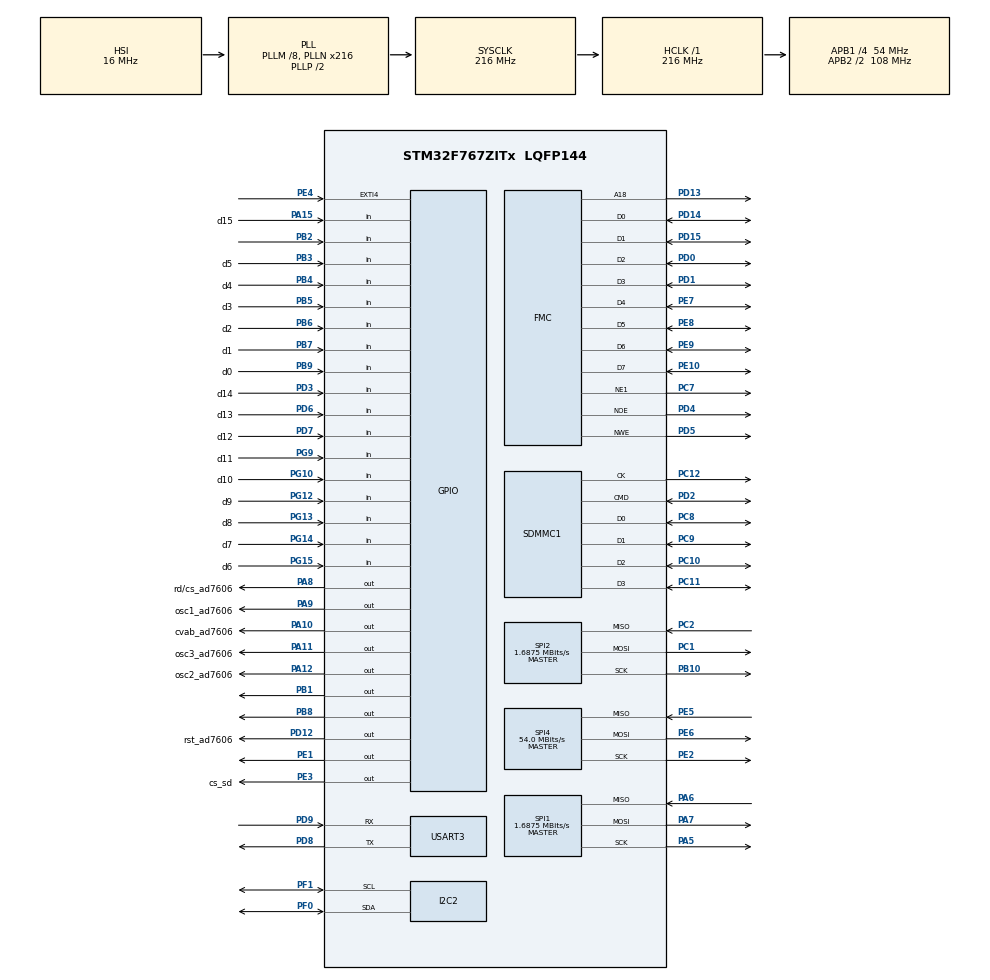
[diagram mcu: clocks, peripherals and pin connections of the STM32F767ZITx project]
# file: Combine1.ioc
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SH.FMC_D7_DA7.0=FMC_D7,8b-d1
PD12.GPIO_Label=rst_ad7606
SPI4.VirtualType=VM_MASTER
SPI1.VirtualType=VM_MASTER
SPI2.VirtualType=VM_MASTER
PB10.Mode=Full_Duplex_Master
PC12.Signal=SDMMC1_CK
PB6.GPIO_Label=d2
SH.FMC_D5_DA5.0=FMC_D5,8b-d1
PD6.GPIO_Label=d13
PG13.Signal=GPIO_Input
SH.FMC_NWE.0=FMC_NWE,Lcd1
RCC.SYSCLKSource=RCC_SYSCLKSOURCE_PLLCLK
USART3.VirtualMode-Asynchronous=VM_ASYNC
PG15.GPIO_Label=d6
SPI1.Direction=SPI_DIRECTION_2LINES
PE2.Mode=Full_Duplex_Master
RCC.APB2TimFreq_Value=216000000
PD4.Signal=FMC_NOE
PB6.Signal=GPIO_Input
PC7.Signal=FMC_NE1
SPI1.CalculateBaudRate=1.6875 MBits/s
PD0.Signal=FMC_D2_DA2
PD8.Signal=USART3_TX
PE5.Signal=SPI4_MISO
PE1.Signal=GPIO_Output
SH.FMC_A18.0=FMC_A18,A18_1
PB2.Signal=GPIO_Input
FMC.DataSetupTime1=255
PE9.Signal=FMC_D6_DA6
SPI1.DataSize=SPI_DATASIZE_8BIT
PC9.Mode=SD_4_bits_Wide_bus
SPI2.CalculateBaudRate=1.6875 MBits/s
PE2.Signal=SPI4_SCK
PA8.Signal=GPIO_Output
SH.FMC_D1_DA1.0=FMC_D1,8b-d1
PE10.Signal=FMC_D7_DA7
Mcu.Package=LQFP144
PB9.Signal=GPIO_Input
PB1.Signal=GPIO_Output
SPI2.Mode=SPI_MODE_MASTER
PD12.Signal=GPIO_Output
PA10.Signal=GPIO_Output
PC11.Mode=SD_4_bits_Wide_bus
RCC.APB2CLKDivider=RCC_HCLK_DIV2
RCC.APB1TimFreq_Value=108000000
PD15.Signal=FMC_D1_DA1
SH.FMC_D3_DA3.0=FMC_D3,8b-d1
PA5.Mode=Full_Duplex_Master
PG12.Signal=GPIO_Input
NVIC.EXTI4_IRQn=true\:0\:0\:false\:false\:true\:true\:true
PG9.Signal=GPIO_Input
FMC.WriteFifo1=FMC_WRITE_FIFO_ENABLE
PA9.GPIO_Label=osc1_ad7606
PD3.Signal=GPIO_Input
PC2.Signal=SPI2_MISO
PD7.Signal=GPIO_Input
PD1.Signal=FMC_D3_DA3
PA11.GPIO_Label=osc3_ad7606
RCC.APB1CLKDivider=RCC_HCLK_DIV4
SH.FMC_NOE.0=FMC_NOE,Lcd1
PG13.GPIO_Label=d8
PG10.Signal=GPIO_Input
PF1.Mode=I2C
PA8.GPIO_Label=rd/cs_ad7606
PA9.Signal=GPIO_Output
PD8.Mode=Asynchronous
PB10.Signal=SPI2_SCK
PA5.Signal=SPI1_SCK
PC12.Mode=SD_4_bits_Wide_bus
PE6.Mode=Full_Duplex_Master
PB4.GPIO_Label=d4
PE8.Signal=FMC_D5_DA5
SPI1.Mode=SPI_MODE_MASTER
PG14.GPIO_Label=d7
SPI1.NSSPMode=SPI_NSS_PULSE_DISABLE
PE4.GPIO_PuPd=GPIO_PULLUP
PC8.Mode=SD_4_bits_Wide_bus
PB5.Signal=GPIO_Input
PA11.Signal=GPIO_Output
ProjectManager.HeapSize=0x200
NVIC.PriorityGroup=NVIC_PRIORITYGROUP_4
PE3.Signal=GPIO_Output
SPI2.DataSize=SPI_DATASIZE_8BIT
PD2.Signal=SDMMC1_CMD
PC1.Signal=SPI2_MOSI
PG10.GPIO_Label=d10
PC1.Mode=Full_Duplex_Master
Mcu.Family=STM32F7
PA6.Mode=Full_Duplex_Master
RCC.CortexFreq_Value=216000000
PC10.Signal=SDMMC1_D2
SPI4.Direction=SPI_DIRECTION_2LINES
I2C2.Timing=0x20404768
SH.FMC_D6_DA6.0=FMC_D6,8b-d1
PD9.Mode=Asynchronous
PG15.Signal=GPIO_Input
ProjectManager.StackSize=0x400
PD13.Signal=FMC_A18
PA15.GPIO_Label=d15
PA12.Signal=GPIO_Output
SPI1.CLKPolarity=SPI_POLARITY_HIGH
SPI4.Mode=SPI_MODE_MASTER
RCC.HCLKFreq_Value=216000000
TIM3.Period=65535
RCC.AHBFreq_Value=216000000
SPI2.BaudRatePrescaler=SPI_BAUDRATEPRESCALER_32
RCC.HSE_VALUE=25000000
SH.FMC_D2_DA2.0=FMC_D2,8b-d1
TIM3.Prescaler=65
PA10.GPIO_Label=cvab_ad7606
PB7.Signal=GPIO_Input
PE4.Signal=GPXTI4
PD7.GPIO_Label=d12
PB7.GPIO_Label=d1
PA6.Signal=SPI1_MISO
SH.FMC_D0_DA0.0=FMC_D0,8b-d1
PA15.Signal=GPIO_Input
SH.FMC_D4_DA4.0=FMC_D4,8b-d1
PB5.GPIO_Label=d3
SPI2.Direction=SPI_DIRECTION_2LINES
PF0.Signal=I2C2_SDA
PD3.GPIO_Label=d14
PE7.Signal=FMC_D4_DA4
PD6.Signal=GPIO_Input
SPI1.BaudRatePrescaler=SPI_BAUDRATEPRESCALER_64
VP_TIM3_VS_ClockSourceINT.Mode=Internal
PB4.Signal=GPIO_Input
PB3.GPIO_Label=d5
PA7.Mode=Full_Duplex_Master
PB9.GPIO_Label=d0
SPI4.DataSize=SPI_DATASIZE_8BIT
PC11.Signal=SDMMC1_D3
PC8.Signal=SDMMC1_D0
PC10.Mode=SD_4_bits_Wide_bus
PE4.GPIO_ModeDefaultEXTI=GPIO_MODE_IT_RISING
PC2.Mode=Full_Duplex_Master
PD9.Signal=USART3_RX
PD5.Signal=FMC_NWE
PA12.GPIO_Label=osc2_ad7606
ProjectManager.TargetToolchain=STM32CubeIDE
RCC.USBFreq_Value=216000000
RCC.LSE_VALUE=32768
VP_FATFS_VS_Generic.Mode=User_defined
PD2.Mode=SD_4_bits_Wide_bus
PG9.GPIO_Label=d11
PG14.Signal=GPIO_Input
board=custom
RCC.VCOOutputFreq_Value=432000000
RCC.APB2Freq_Value=108000000
PE5.Mode=Full_Duplex_Master
SPI4.CalculateBaudRate=54.0 MBits/s
PF1.Signal=I2C2_SCL
PE6.Signal=SPI4_MOSI
Mcu.Name=STM32F767ZITx
PD14.Signal=FMC_D0_DA0
PB3.Signal=GPIO_Input
RCC.SYSCLKFreq_VALUE=216000000
PF0.Mode=I2C
PG12.GPIO_Label=d9
RCC.HSI_VALUE=16000000
RCC.PLLM=8
RCC.PLLN=216
PB8.Signal=GPIO_Output
PE3.GPIO_Label=cs_sd
PC9.Signal=SDMMC1_D1
PC7.Mode=NorPsramChipSelect1_1
RCC.APB1Freq_Value=54000000
PA7.Signal=SPI1_MOSI

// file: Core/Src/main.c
/* USER CODE BEGIN Header */
/**
  ******************************************************************************
  * @file           : main.c
  * @brief          : Main program body
  ******************************************************************************
  * @attention
  *
  * <h2><center>&copy; Copyright (c) 2021 STMicroelectronics.
  * All rights reserved.</center></h2>
  *
  * This software component is licensed by ST under BSD 3-Clause license,
  * the "License"; You may not use this file except in compliance with the
  * License. You may obtain a copy of the License at:
  *                        opensource.org/licenses/BSD-3-Clause
  *
  ******************************************************************************
  */
/* USER CODE END Header */
#include "main.h"
#include "fatfs.h"

/* USER CODE BEGIN Includes */
#include "MA_ILI9341.h"
#include "FIFO.h"
#include "defines.h"
#include "arm_math.h"
#include "arm_const_structs.h"

//extern float32_t testInput_f32_10khz[TEST_LENGTH_SAMPLES];
//static float32_t testOutput[TEST_LENGTH_SAMPLES/2];

#define NPT 1024 //point FFT
#define Fs 5120 //Sampling frequency 5120Hz Frequency resolution 5Hz
#define PI2 6.28318530717959

// ************ Global variables for FFT Bin Example
uint32_t fftSize = 1024;
uint32_t ifftFlag = 0;
uint32_t doBitReverse = 1;

/* USER CODE END Includes */

/* USER CODE BEGIN PTD */
uint8_t myImage[] =
{
0xff,0xff,0xff,0xff,0xff,0xff,0xff,0xff,0xff,0xff,0xff,0xff,0xff,0xff,0xff,0xff,0xff,0xff,0xff,0xff,0xff,0xff,0xff,0xff,0xff,0xff,0xff,0xff,0xff,0xff,0xff,0xff,0xff,0xff,0xff,0xff,0xff,0xff,0xff,0xff,0xff,0xff,0xff,0xff,0xff,0xff,0xff,0xff,0xff,0xff,0xff,0xff,0xff,0xff,0xff,0xff,0xff,0xff,0xff,0xff,0xff,0xff,0xff,0xff,0xff,0xff,0xff,0xff,0xff,0xff,0xff,0xff,0x9c,0xb1,0x39,0x85,0x39,0xc6,0x39,0xc6,0x39,0xe6,0x4a,0x48,0x42,0x27,0x42,0x27,0x5a,0xe9,0xef,0x9d,0xff,0xff,0xff,0xff,0xff,0xff,0xff,0xff,0xff,0xff,0xff,0xff,0xff,0xff,0xff,0xff,0xff,0xff,0xff,0xff,0xff,0xff,0xff,0xff,0xff,0xff,0xff,0xff,0xff,0xff,0xff,0xff,0xff,0xff,0xff,0xff,0xff,0xff,0xff,0xff,0xff,0xff,0xff,0xff,0xff,0xff,0xff,0xff,0xff,0xff,0xff,0xff,0xff,0xff,0xff,0xff,0xff,0xff,0xff,0xff,0xff,0xff,0xff,0xff,0xff,0xff,0xff,0xff
,0xff,0xff,0xff,0xff,0xff,0xff,0xff,0xff,0xff,0xff,0xff,0xff,0xff,0xff,0xff,0xff,0xff,0xff,0xff,0xff,0xff,0xff,0xff,0xff,0xff,0xff,0xff,0xff,0xff,0xff,0xff,0xff,0xff,0xff,0xff,0xff,0xff,0xff,0xff,0xff,0xff,0xff,0xff,0xff,0xff,0xff,0xff,0xff,0xff,0xff,0xff,0xff,0xff,0xff,0xff,0xff,0xff,0xff,0xff,0xff,0xff,0xff,0xff,0xff,0xff,0xff,0xff,0xff,0xff,0xff,0xff,0xff,0x94,0x70,0x5a,0x88,0x41,0xe7,0x39,0xc6,0x29,0x44,0x31,0x84,0x39,0xa5,0x4a,0x27,0x52,0x68,0xf7,0x7d,0xff,0xff,0xff,0xff,0xff,0xff,0xff,0xff,0xff,0xff,0xff,0xff,0xff,0xff,0xff,0xff,0xff,0xff,0xff,0xff,0xff,0xff,0xff,0xff,0xff,0xff,0xff,0xff,0xff,0xff,0xff,0xff,0xff,0xff,0xff,0xff,0xff,0xff,0xff,0xff,0xff,0xff,0xff,0xff,0xff,0xff,0xff,0xff,0xff,0xff,0xff,0xff,0xff,0xff,0xff,0xff,0xff,0xff,0xff,0xff,0xff,0xff,0xff,0xff,0xff,0xff,0xff,0xff
,0x7e,0x32,0x65,0xb0,0x65,0xb0,0x65,0x90,0x65,0x90,0x65,0x90,0x65,0x90,0x65,0x90,0x6d,0x90,0x6d,0x90,0x6d,0x90,0x6d,0x90,0x6d,0x90,0x6d,0x90,0x6d,0x90,0x6d,0x90,0x6d,0x90,0x6d,0x90,0x6d,0x90,0x6d,0x90,0x65,0x90,0x65,0xb0,0x6d,0x90,0x65,0xb0,0x65,0x90,0x65,0x90,0x65,0x90,0x65,0x90,0x65,0x90,0x65,0x90,0x6d,0x90,0x6d,0x90,0x75,0x90,0xae,0x15,0xbd,0xd5,0xbd,0xb4,0x84,0x0e,0x6b,0x2a,0x4a,0x48,0x4a,0x27,0x31,0x65,0x41,0xe6,0x4a,0x27,0x6b,0x2a,0x5a,0xa8,0xd6,0x78,0xde,0xda,0xc6,0xd8,0x7d,0xd2,0x75,0xd2,0x75,0xd2,0x75,0xd2,0x75,0xf2,0x75,0xf2,0x75,0xf2,0x75,0xf2,0x75,0xf2,0x75,0xd2,0x7d,0xf2,0x7d,0xf2,0x7d,0xf2,0x7d,0xf2,0x7d,0xf2,0x7e,0x12,0x7e,0x12,0x7e,0x12,0x7d,0xf2,0x7d,0xf2,0x7d,0xf2,0x7d,0xf2,0x7d,0xf2,0x7d,0xf2,0x7d,0xf2,0x7d,0xf2,0x7d,0xf2,0x7d,0xf3,0x7d,0xf3,0x7e,0x13,0x7e,0x33,0x8e,0x74
,0x0c,0x68,0x04,0x06,0x03,0xe6,0x03,0xe6,0x03,0xe6,0x03,0xe6,0x03,0xc6,0x03,0xc6,0x03,0xe6,0x03,0xc6,0x03,0xe6,0x03,0xe6,0x03,0xe6,0x03,0xe6,0x03,0xe6,0x03,0xe6,0x03,0xe6,0x03,0xe6,0x03,0xe6,0x03,0xe6,0x03,0xe6,0x03,0xe6,0x03,0xe6,0x04,0x06,0x04,0x06,0x03,0xe6,0x03,0xe6,0x03,0xe6,0x03,0xe6,0x03,0xe6,0x03,0xe6,0x03,0xe6,0x03,0xc6,0x6c,0xee,0xe7,0x1a,0xc5,0xd4,0x83,0xed,0x52,0x68,0x52,0x68,0x6b,0x4b,0x42,0x26,0x6b,0x2a,0x5a,0xc9,0x7b,0xad,0x4a,0x47,0xbd,0xd4,0xef,0x7c,0xa6,0x14,0x03,0xc6,0x03,0xe7,0x03,0xe7,0x03,0xe6,0x03,0xc6,0x03,0xc6,0x03,0xc6,0x03,0xe6,0x03,0xe6,0x03,0xe6,0x03,0xe6,0x03,0xe6,0x03,0xe6,0x03,0xe6,0x03,0xe7,0x03,0xe7,0x03,0xe7,0x03,0xe7,0x03,0xe7,0x03,0xe7,0x03,0xe7,0x03,0xe7,0x03,0xe7,0x03,0xe7,0x03,0xe6,0x03,0xe6,0x03,0xe7,0x03,0xe7,0x03,0xe7,0x03,0xe7,0x04,0x07,0x0c,0x28
,0x04,0x48,0x04,0x07,0x04,0x07,0x03,0xe7,0x03,0xe6,0x03,0xc7,0x03,0xa6,0x03,0x86,0x03,0xa6,0x03,0xc6,0x03,0xc6,0x03,0xc6,0x03,0xc6,0x03,0xc6,0x03,0xc6,0x03,0xe6,0x03,0xe6,0x03,0xe6,0x03,0xc6,0x03,0xe6,0x03,0xe6,0x03,0xe7,0x03,0xc6,0x03,0xe6,0x04,0x06,0x03,0xe6,0x03,0xe6,0x03,0xe6,0x03,0xe6,0x03,0xc6,0x03,0xc6,0x03,0xc6,0x03,0xe6,0x5c,0x6c,0xa5,0x12,0x9c,0x8f,0x7b,0xac,0x5a,0x89,0x42,0x27,0x8c,0x2e,0xce,0x36,0xbd,0xb5,0x4a,0x47,0x73,0xac,0x4a,0x47,0x94,0x90,0xad,0x74,0x95,0x52,0x03,0xa7,0x03,0xc7,0x03,0xc7,0x03,0xe7,0x03,0xe7,0x03,0xe7,0x03,0x86,0x03,0x86,0x03,0xe6,0x03,0xe6,0x03,0xe6,0x03,0xc6,0x03,0xc6,0x03,0xe7,0x03,0xe7,0x03,0xe7,0x03,0xe7,0x03,0xe7,0x03,0xe7,0x03,0xe7,0x03,0xe7,0x03,0xe7,0x03,0xe7,0x03,0xc7,0x03,0xa7,0x03,0xa7,0x03,0xe7,0x03,0xe7,0x03,0xe7,0x03,0xe7,0x03,0xe7,0x0c,0x08
,0x04,0x27,0x03,0xe7,0x03,0xe7,0x03,0xe6,0x03,0xe6,0x03,0xe7,0x33,0x89,0x4b,0xca,0x33,0x69,0x03,0xc6,0x03,0xc6,0x03,0xc6,0x03,0xc6,0x03,0xc6,0x03,0xe6,0x03,0xe6,0x03,0xe6,0x03,0xe6,0x03,0xe6,0x03,0xe6,0x03,0xe6,0x03,0xe6,0x03,0xe6,0x03,0xe6,0x03,0xe6,0x03,0xe6,0x03,0xe6,0x03,0xe6,0x03,0xe6,0x03,0xe5,0x03,0xe6,0x03,0xc6,0x03,0xe6,0x5c,0x6c,0x94,0x90,0x7b,0xab,0x73,0x6b,0x41,0xe6,0x42,0x06,0x5a,0xa8,0x94,0x6f,0x7b,0xcd,0x42,0x06,0x4a,0x88,0x52,0x88,0x94,0x4e,0xa5,0x32,0x95,0x52,0x03,0x87,0x03,0xe7,0x03,0xc7,0x03,0xe7,0x03,0xe7,0x03,0xa6,0x64,0x49,0x6c,0x69,0x03,0xa6,0x03,0xc7,0x03,0xc6,0x03,0xc6,0x03,0xc6,0x03,0xe7,0x03,0xe7,0x03,0xe7,0x03,0xe7,0x03,0xe7,0x03,0xe7,0x03,0xe7,0x03,0xe7,0x03,0xe7,0x03,0xe7,0x23,0x68,0x2b,0x27,0x3b,0x88,0x03,0xa7,0x03,0xe7,0x03,0xe7,0x03,0xe7,0x03,0xe7,0x14,0x08
,0x04,0x27,0x03,0xe7,0x03,0xe7,0x03,0xe7,0x03,0xe7,0x03,0xe7,0x2b,0x07,0x74,0x0a,0x4b,0xca,0x03,0xa6,0x03,0xc6,0x03,0xc6,0x03,0xc6,0x03,0xa5,0x03,0xe6,0x03,0xe6,0x03,0xe6,0x1c,0x28,0x3c,0x4b,0x33,0xa9,0x44,0x2b,0x23,0xe8,0x03,0x45,0x03,0x46,0x03,0x26,0x03,0x46,0x03,0x45,0x03,0x25,0x03,0x45,0x03,0xa6,0x03,0xe6,0x03,0xe6,0x03,0xe6,0x74,0xcf,0xd6,0x98,0xa5,0x31,0x73,0x8b,0x10,0xc2,0x18,0xc2,0x29,0x44,0x29,0x03,0x29,0x44,0x21,0x03,0x20,0xe2,0x4a,0x47,0xad,0x73,0xef,0x5c,0xa5,0xb4,0x03,0x86,0x03,0xe7,0x03,0xa6,0x03,0xe7,0x03,0xe7,0x03,0xc7,0x33,0x66,0x3b,0x87,0x03,0xc6,0x03,0xc7,0x03,0xc7,0x03,0xc6,0x03,0xc6,0x03,0xe7,0x03,0xe7,0x03,0xe7,0x03,0xe7,0x03,0xe7,0x03,0xe7,0x03,0xe7,0x03,0xe7,0x03,0xe7,0x03,0xe7,0x1b,0x07,0x6b,0xca,0x4b,0xeb,0x03,0xa7,0x03,0xe7,0x03,0xe7,0x03,0xc7,0x03,0xe7,0x14,0x08
,0x04,0x27,0x03,0xe7,0x03,0xe7,0x03,0xe7,0x03,0xe7,0x03,0xe7,0x33,0x89,0x4b,0x49,0x4b,0xaa,0x03,0xc6,0x03,0xc6,0x03,0xc6,0x03,0xc6,0x03,0xc6,0x03,0xe6,0x03,0xe6,0x03,0xe6,0x34,0x2a,0x84,0x4f,0x52,0x89,0x8c,0x8f,0x5c,0x6c,0x64,0xee,0x2c,0x49,0x03,0xa6,0x03,0xa6,0x03,0xa6,0x03,0x85,0x0b,0x45,0x03,0x45,0x03,0xc6,0x03,0xe6,0x03,0xe6,0x13,0x47,0x23,0x47,0x3b,0x68,0x63,0x2a,0x10,0xc2,0x10,0xa1,0x52,0x68,0x7b,0xad,0x63,0x0b,0x18,0xe2,0x20,0xe3,0x52,0x27,0x53,0xca,0x23,0x47,0x23,0x67,0x03,0xa7,0x03,0xc7,0x03,0xc7,0x03,0xc7,0x03,0xe7,0x03,0xe7,0x03,0xc6,0x03,0xc6,0x03,0xc7,0x03,0xc6,0x03,0xc7,0x03,0xe7,0x03,0xe7,0x03,0xe7,0x03,0xe7,0x03,0xe7,0x03,0xe7,0x03,0xe7,0x03,0xe7,0x03,0xe7,0x03,0xe7,0x03,0xe7,0x03,0xe7,0x2b,0x69,0x43,0x49,0x4b,0xaa,0x03,0xa7,0x03,0xe7,0x03,0xe7,0x03,0xc7,0x03,0xc7,0x14,0x08
,0x04,0x08,0x03,0xe7,0x03,0xe7,0x03,0xe7,0x03,0xe7,0x03,0xc7,0x03,0x46,0x2b,0x88,0x0b,0x66,0x03,0xc6,0x03,0xc6,0x03,0xc6,0x03,0xc6,0x03,0xe6,0x03,0xe6,0x03,0xc6,0x03,0xc6,0x2c,0x29,0x84,0x6f,0x5b,0x2a,0x7c,0x4e,0x4b,0xcb,0x1b,0xc9,0x13,0xc8,0x03,0x65,0x03,0x65,0x03,0x65,0x03,0x65,0x03,0x65,0x03,0xc6,0x03,0xe6,0x03,0xa6,0x03,0xc6,0x0b,0x46,0x13,0x47,0x4b,0xea,0x63,0x4a,0x10,0xa1,0x18,0xc2,0x63,0x0a,0xad,0x53,0x5a,0xea,0x31,0x64,0x20,0xe2,0x4a,0x47,0x4b,0xea,0x13,0x47,0x0b,0x46,0x03,0xa7,0x03,0xc7,0x1c,0x09,0x0b,0xe8,0x03,0xe7,0x03,0xe7,0x03,0xe7,0x03,0xc6,0x03,0xe6,0x03,0xc7,0x03,0xc7,0x03,0xc7,0x03,0xc6,0x03,0xc6,0x03,0xc6,0x03,0xe7,0x03,0xe7,0x03,0xc7,0x03,0xe7,0x03,0xe7,0x03,0xe7,0x04,0x07,0x04,0x07,0x03,0xa7,0x3b,0xeb,0x0b,0x67,0x03,0xe7,0x03,0xe7,0x03,0xe7,0x03,0xe7,0x03,0xc7,0x13,0xe8
,0x04,0x07,0x03,0xe7,0x03,0xe7,0x03,0xe7,0x03,0xe6,0x03,0xc6,0x13,0x87,0x74,0x6d,0x33,0xc9,0x03,0xa6,0x03,0xc6,0x03,0xc6,0x03,0xc6,0x03,0xc6,0x03,0xe6,0x03,0xc6,0x03,0xc6,0x1b,0xe7,0xbe,0x37,0xb5,0xd5,0xd6,0xb8,0x85,0x50,0x2c,0x49,0x03,0xc6,0x03,0xc6,0x03,0xc6,0x03,0xc6,0x03,0xe6,0x03,0xe6,0x03,0xe6,0x0c,0x07,0x0b,0xe7,0x03,0xe7,0x64,0x8f,0xce,0x98,0x9d,0x32,0x6b,0x4b,0x10,0xa1,0x63,0x0a,0x73,0x6b,0xad,0x33,0x73,0xcd,0x73,0x4c,0x31,0x23,0x52,0x47,0xa5,0x52,0xd6,0x79,0xa5,0x93,0x0b,0xa7,0x13,0xe8,0x65,0x0e,0x3c,0xac,0x03,0xe7,0x03,0xe7,0x03,0xc6,0x03,0xa6,0x03,0xc6,0x03,0xc6,0x03,0xc6,0x03,0xc6,0x03,0xc6,0x03,0xc6,0x03,0xc6,0x03,0xc7,0x03,0xc7,0x03,0xc7,0x03,0xe7,0x03,0xc6,0x03,0xe7,0x03,0xc6,0x03,0xe6,0x23,0xe9,0x63,0xea,0x6c,0xac,0x03,0xc7,0x03,0xe7,0x03,0xe7,0x03,0xe7,0x03,0xe7,0x13,0xe8
,0x04,0x27,0x03,0xe6,0x03,0xe6,0x03,0xc6,0x03,0xc6,0x03,0xc6,0x0b,0x86,0x43,0xa9,0x44,0x4a,0x03,0xa6,0x03,0xc6,0x03,0xc6,0x03,0xc6,0x03,0xa5,0x03,0xa6,0x44,0xec,0x4c,0x8c,0x54,0xac,0xef,0x5b,0xe7,0x3b,0xef,0x5b,0xa5,0xd4,0x3c,0x6b,0x03,0xc6,0x03,0xc7,0x03,0xa6,0x03,0xc6,0x03,0xc6,0x03,0xe6,0x03,0xe6,0x55,0x0d,0x75,0x91,0x3c,0xac,0x6c,0x6d,0xad,0x53,0x83,0xed,0x6b,0x4b,0x10,0xa1,0x5a,0xa9,0x6b,0x4b,0x6b,0x2b,0x6b,0x4b,0x63,0x0a,0x29,0x23,0x4a,0x47,0x8c,0x2e,0xad,0x33,0x8d,0x12,0x03,0xa7,0x44,0x8c,0x74,0xef,0x5c,0x6d,0x02,0xe5,0x03,0xc7,0x03,0xc6,0x03,0xa6,0x03,0xc6,0x03,0xa7,0x03,0x86,0x03,0xa7,0x03,0x87,0x0b,0xa7,0x0b,0xe8,0x03,0xa6,0x0b,0xc7,0x0b,0xa7,0x03,0xa7,0x03,0xc7,0x03,0xe7,0x03,0xe7,0x03,0xe6,0x1b,0xe8,0x54,0x0b,0x4c,0xac,0x03,0xc7,0x03,0xc7,0x03,0xc7,0x03,0xe7,0x03,0xe7,0x14,0x08
,0x04,0x27,0x03,0xe6,0x03,0xe6,0x03,0xc6,0x03,0xc6,0x03,0xc6,0x03,0x85,0x03,0x04,0x03,0x44,0x03,0xa6,0x03,0xc5,0x0b,0xe6,0x0c,0x07,0x03,0xe7,0x03,0xc6,0x24,0x28,0x24,0x29,0x44,0x4b,0xdf,0x1a,0xd6,0xd9,0xde,0xd9,0xa5,0xf4,0x13,0xa7,0x14,0x29,0x14,0x08,0x0c,0x07,0x03,0xc6,0x03,0xc6,0x03,0xc6,0x03,0xe6,0x03,0xe6,0x03,0xc7,0x0b,0xc8,0x6c,0x8e,0xa5,0x53,0x73,0x8b,0x63,0xcd,0x8c,0x6e,0x8c,0x0c,0x7b,0xed,0x73,0xcc,0x7b,0xab,0x83,0xcb,0x84,0x2d,0x6c,0x0d,0x6b,0x6c,0xb5,0x93,0x8d,0x11,0x03,0xa7,0x3b,0xea,0x95,0x12,0x64,0x2d,0x2b,0xaa,0x4c,0x8c,0x24,0x29,0x34,0x49,0x03,0xa7,0x03,0x05,0x33,0xc9,0x2b,0xa9,0x0b,0x46,0x3c,0x2b,0x5c,0xef,0x0b,0x47,0x4c,0x8c,0x5c,0xee,0x03,0x46,0x03,0x46,0x03,0xe7,0x03,0xe7,0x03,0xe7,0x03,0xc7,0x0b,0x66,0x03,0xa7,0x03,0xc7,0x03,0xe7,0x03,0xe7,0x03,0xe7,0x03,0xe7,0x13,0xe8
,0x04,0x07,0x03,0xa6,0x03,0xe6,0x03,0xc6,0x03,0xc6,0x03,0xa6,0x03,0x85,0x03,0x04,0x03,0x45,0x03,0x85,0x03,0xa6,0x2c,0x6a,0x5d,0x0e,0x24,0x49,0x03,0xc6,0x03,0xc6,0x03,0xc6,0x34,0x2a,0xe7,0x5a,0xdf,0x1a,0xe7,0x1a,0xa5,0xd3,0x24,0x29,0x3c,0xac,0x65,0x4f,0x3c,0xab,0x03,0xe6,0x03,0xe6,0x03,0xe6,0x03,0xe6,0x03,0xc6,0x03,0xe6,0x03,0xc7,0x6c,0x6e,0xad,0xb4,0xb5,0x93,0x12,0x64,0x23,0x06,0x42,0xe7,0x42,0xa7,0x3a,0x86,0x3a,0x86,0x3a,0xe7,0x32,0xc7,0x3b,0x89,0x7c,0x4e,0xad,0x52,0x95,0x31,0x03,0x87,0x33,0x89,0x29,0x84,0x3b,0x28,0x12,0xe6,0x5c,0x6d,0x3b,0xa9,0x34,0x09,0x03,0x86,0x13,0x06,0x4c,0x0b,0x43,0x6a,0x44,0x2c,0x0a,0x85,0x1a,0xc6,0x0a,0xc5,0x0b,0x25,0x0b,0x25,0x03,0x25,0x03,0x46,0x03,0xc7,0x03,0xe6,0x03,0xe7,0x03,0xc6,0x03,0xa7,0x03,0xa7,0x03,0xc7,0x03,0xe7,0x03,0xe7,0x03,0xe7,0x03,0xe7,0x13,0xe8
,0x0c,0x07,0x03,0xe6,0x03,0xc6,0x03,0xc6,0x03,0xa5,0x03,0x65,0x13,0x87,0x23,0x87,0x13,0x87,0x03,0x85,0x03,0xa6,0x54,0xad,0x7d,0x0f,0x3c,0x0b,0x2b,0xc9,0x3c,0x6a,0x03,0xc6,0x34,0x29,0xc6,0x57,0xbe,0x36,0xd6,0xb8,0x9d,0x51,0x0b,0x86,0x03,0x85,0x03,0xc6,0x03,0xa5,0x03,0xc5,0x2c,0x4a,0x2c,0x6b,0x3c,0xac,0x44,0xed,0x34,0x2a,0x6d,0x91,0x3b,0xa9,0x64,0x8e,0x4b,0xaa,0x02,0xa4,0x02,0x82,0x0a,0x84,0x09,0xe3,0x09,0xe3,0x09,0xe3,0x0a,0x24,0x3b,0x08,0x3b,0xca,0x33,0x08,0x74,0x8f,0x4b,0xcb,0x03,0x26,0x3b,0x48,0x10,0xe2,0x33,0x08,0x4c,0x2c,0xad,0xb4,0x74,0xcf,0x95,0x93,0x44,0x2b,0x5c,0x2c,0x84,0x6f,0x84,0x8e,0x9d,0x72,0x33,0x28,0x9d,0x31,0x7c,0xef,0x34,0x4a,0x34,0x29,0x03,0x25,0x03,0x46,0x03,0xc7,0x03,0xe7,0x03,0xc7,0x03,0xc6,0x03,0xc7,0x03,0xc7,0x03,0xc7,0x03,0xc6,0x03,0xc7,0x03,0xe7,0x03,0xe7,0x13,0xe8
,0x0c,0x07,0x03,0xc6,0x03,0xc6,0x03,0xc6,0x03,0x85,0x03,0x66,0x3b,0x88,0x5b,0xab,0x3b,0x48,0x03,0x65,0x03,0x65,0x43,0x89,0x9d,0x53,0x54,0x2d,0x64,0x6e,0x44,0x8b,0x03,0xc6,0x03,0x65,0x5c,0x0c,0x4b,0x6a,0x7c,0x8e,0x3b,0x48,0x03,0x66,0x03,0x85,0x03,0x85,0x03,0x85,0x03,0xa5,0x3c,0x6b,0x3c,0xab,0x55,0x0e,0x54,0xee,0x5c,0xee,0x75,0x90,0x0b,0xc6,0x03,0xa6,0x03,0x65,0x03,0x05,0x02,0xa4,0x33,0x68,0x6c,0x6e,0x5b,0xcb,0x64,0x2d,0x43,0x8a,0x23,0x27,0x02,0xa4,0x03,0x05,0x03,0x06,0x03,0x26,0x03,0x26,0x4b,0xea,0x7c,0x2e,0x3b,0x69,0x43,0xca,0x8c,0x2d,0x64,0x0b,0x8c,0x4d,0x53,0xaa,0x53,0x49,0x42,0x26,0x4a,0x46,0x52,0xa8,0x43,0x69,0x7c,0x0c,0x63,0xcb,0x7c,0x8f,0x7c,0xaf,0x02,0xa5,0x03,0x46,0x03,0xc7,0x03,0xc7,0x03,0xc7,0x03,0xc7,0x03,0xc6,0x03,0xc6,0x03,0xc6,0x03,0xc6,0x03,0xc7,0x03,0xe7,0x03,0xc7,0x13,0xe8
,0x0c,0x07,0x03,0xc6,0x03,0xc6,0x03,0xa6,0x03,0xa6,0x13,0x67,0x19,0x83,0x4a,0x67,0x31,0xa4,0x3c,0x09,0x03,0x25,0x22,0x45,0x29,0x84,0x64,0x2c,0xad,0xf5,0x44,0x8b,0x03,0xc6,0x03,0xa6,0x54,0x4c,0x53,0xab,0x64,0x2c,0x43,0xca,0x03,0x66,0x03,0x65,0x03,0x65,0x03,0x65,0x03,0xa5,0x2c,0x49,0x03,0xc7,0x0b,0xa7,0x0b,0xa7,0x0b,0xa6,0x0b,0xc7,0x0b,0x86,0x03,0xa6,0x0b,0x66,0x0a,0xc4,0x4b,0xeb,0x6c,0x6d,0x7c,0x8f,0x8c,0xcf,0x84,0xaf,0x7c,0x6e,0x13,0x47,0x03,0x45,0x03,0x66,0x23,0xc8,0x54,0x6c,0x75,0x30,0x54,0x4b,0x5b,0xec,0x44,0x0b,0x44,0x0b,0x9c,0xd0,0x6c,0x0c,0x6c,0x2d,0x54,0x0b,0x32,0x47,0x21,0x44,0x21,0x24,0x29,0x64,0x43,0x8a,0x84,0x6e,0x74,0x6e,0x95,0x10,0x74,0x8e,0x02,0xc5,0x03,0x66,0x03,0xc7,0x03,0xc7,0x03,0xc7,0x03,0xe7,0x03,0xe7,0x03,0xc6,0x03,0xc6,0x03,0xe7,0x03,0xe7,0x03,0xe7,0x03,0xe7,0x0c,0x08
,0x0c,0x07,0x03,0xc6,0x03,0xc6,0x03,0xa5,0x85,0x90,0x9d,0xb2,0x19,0x02,0x4a,0x46,0x19,0x02,0x3b,0x68,0x02,0x84,0x19,0xc4,0x19,0x23,0x64,0x0c,0x7c,0x6f,0x4b,0xea,0x0b,0xc7,0x44,0xac,0x74,0x0c,0x6c,0x0c,0x63,0x6a,0x5c,0x4c,0x4c,0xcd,0x03,0x66,0x2c,0x09,0x23,0xe8,0x03,0xa6,0x2c,0x4a,0x34,0x8b,0x85,0x30,0x95,0x52,0x95,0x52,0x95,0x93,0x95,0x72,0x7d,0x10,0x95,0x31,0x54,0x0c,0x53,0xab,0x7c,0x2e,0x7c,0x0d,0x84,0x0d,0x7c,0x4e,0x7b,0xcc,0x1c,0x08,0x03,0xa6,0x03,0xa6,0x14,0x08,0x4c,0xcd,0x24,0x09,0x54,0xcd,0xb5,0xf4,0x5c,0xce,0x4c,0x4b,0x8d,0x10,0x53,0xcb,0x2b,0xc9,0x13,0x47,0x3a,0xe8,0x3a,0x06,0x21,0xc4,0x63,0x2a,0x4b,0xeb,0x6c,0x6e,0x64,0x6d,0x64,0x8e,0x54,0x0c,0x02,0xc5,0x03,0x66,0x03,0xc7,0x03,0xe6,0x03,0xe6,0x03,0xe6,0x03,0xe6,0x03,0xe6,0x03,0xe7,0x03,0xe7,0x03,0xe7,0x03,0xe7,0x03,0xe7,0x0b,0xe8
,0x0c,0x07,0x03,0xc6,0x03,0xc6,0x03,0xa5,0x34,0x09,0x43,0xe9,0x29,0xa4,0x18,0xa1,0x21,0x03,0x3b,0x48,0x02,0x24,0x3a,0xe8,0x74,0x2e,0x6c,0x8d,0x84,0xf0,0x4b,0xeb,0x13,0x67,0x75,0x4f,0x8c,0xf0,0x95,0x11,0x84,0x8f,0x74,0xae,0x5c,0xcd,0x1b,0x67,0x5c,0x6c,0x33,0xea,0x03,0x87,0x03,0xc7,0x03,0xc7,0x64,0x2c,0x63,0xcc,0x5b,0x6a,0x7c,0x8f,0x53,0x29,0x6c,0x6e,0x52,0xe8,0x53,0xeb,0x7c,0xaf,0x95,0x31,0x63,0xcc,0x63,0xcc,0x6c,0x0d,0x63,0x6b,0x1c,0x08,0x03,0xa6,0x03,0xc6,0x44,0xac,0x65,0x0f,0x2c,0x49,0x7c,0xef,0xd6,0x75,0x4c,0x2b,0x4c,0x4b,0xa5,0x92,0x8c,0x6e,0x9d,0x52,0x3b,0xa9,0x32,0xe7,0x2a,0xa6,0x0a,0x03,0x5b,0xac,0x03,0x06,0x03,0x87,0x23,0xe9,0x6c,0x8e,0x64,0x6e,0x02,0xc5,0x03,0x66,0x03,0xc7,0x03,0xc7,0x03,0xe7,0x03,0xe7,0x03,0xe6,0x03,0xe6,0x0b,0xc7,0x03,0xe7,0x03,0xe7,0x03,0xe7,0x03,0xe7,0x0b,0xe8
,0x0c,0x07,0x03,0xc6,0x03,0xc6,0x03,0xa5,0x03,0x65,0x0b,0x25,0x21,0xa4,0x39,0x84,0x18,0xe2,0x3b,0x29,0x02,0x24,0x43,0x8a,0x53,0xeb,0x3b,0xc9,0x0b,0x05,0x03,0x05,0x03,0x25,0x13,0x86,0x4c,0x0b,0x4c,0x2b,0x44,0x8c,0x34,0x2a,0x5c,0x4c,0xce,0x77,0xbd,0xd5,0xb6,0x15,0x44,0x0b,0x03,0xc7,0x03,0xc6,0x75,0x0f,0x84,0xf0,0x85,0x10,0x85,0x30,0x84,0xf0,0x74,0xcf,0x7c,0xcf,0x5c,0xcd,0x44,0x2a,0x54,0x2c,0x7c,0x6e,0x94,0xf0,0x8c,0xf0,0x94,0xcf,0x23,0xa8,0x0b,0x46,0x0b,0xa6,0x34,0x6a,0x7d,0x91,0x2c,0x29,0x7c,0xef,0xce,0x14,0x54,0x6c,0x44,0x4b,0x84,0x2d,0x5b,0x09,0x74,0x0d,0x64,0x6e,0x4c,0x4c,0x0b,0x26,0x03,0x65,0x03,0x66,0x03,0x66,0x03,0x86,0x2c,0x09,0x4b,0x2a,0x5b,0xcc,0x4c,0x0b,0x44,0x2b,0x7d,0xb1,0x7d,0x91,0x6d,0x70,0x7d,0x91,0x6d,0x30,0x5d,0x2f,0x75,0x90,0x3c,0xac,0x4c,0xed,0x03,0xe7,0x03,0xc7,0x0c,0x08
,0x0c,0x07,0x03,0xc7,0x03,0xc7,0x03,0x86,0x03,0x45,0x02,0xe4,0x19,0x42,0x6a,0xe8,0x18,0xe2,0x3b,0x08,0x02,0x64,0x3b,0x89,0x74,0x2e,0x74,0x0d,0x5c,0x4c,0x02,0xa4,0x02,0xc4,0x03,0x25,0x03,0x65,0x03,0x86,0x03,0xc6,0x23,0xc7,0xa5,0x11,0x52,0x68,0x39,0x84,0x4a,0x27,0x7c,0x4e,0x13,0xc8,0x03,0xe7,0x1b,0x48,0x1b,0x07,0x33,0x89,0x7c,0xce,0x23,0x47,0x13,0x26,0x13,0x26,0x23,0x67,0x65,0x0f,0x3c,0x0a,0x3b,0xea,0x33,0xc9,0x3b,0xea,0x3b,0xeb,0x2b,0xa9,0x75,0x10,0x2b,0xca,0x34,0x2a,0x54,0xee,0x03,0xc7,0x4c,0x8d,0xa5,0xd4,0x54,0x8d,0x1b,0xe9,0x34,0x0a,0x23,0xc8,0x2b,0xea,0x2b,0xe9,0x1b,0xa9,0x03,0x45,0x03,0x66,0x03,0x86,0x0b,0xa7,0x24,0x09,0x3c,0x0a,0x21,0x64,0x3a,0x68,0x4c,0x0c,0x8d,0x92,0x6d,0x2f,0x85,0x91,0x75,0x70,0x95,0xf3,0x5c,0xee,0x5d,0x2e,0x55,0x0d,0x5d,0x0e,0x6d,0x70,0x03,0xe7,0x03,0xe7,0x0c,0x07
,0x0c,0x08,0x03,0xc7,0x03,0xa7,0x5c,0xcd,0x5c,0xad,0x13,0x26,0x21,0x64,0x10,0xa1,0x18,0xe3,0x3b,0xa9,0x03,0x05,0x44,0x2b,0x6c,0x2d,0x64,0x2c,0x54,0x4b,0x03,0x45,0x13,0x66,0x1b,0x67,0x0b,0xc7,0x24,0x49,0x03,0xc6,0x44,0x2a,0x8c,0x0e,0x39,0xa5,0x39,0xc5,0x42,0x26,0x73,0x8c,0x2b,0xe9,0x0b,0xc7,0x54,0x8d,0x3c,0x0a,0x43,0x8a,0x8c,0x8e,0x2b,0x89,0x0b,0x05,0x13,0x06,0x2b,0x88,0x3b,0xe9,0x2b,0xa8,0x33,0x89,0x23,0x68,0x12,0xe6,0x64,0x6c,0xad,0xd4,0x5c,0x4c,0x23,0x68,0x2b,0x89,0x4c,0xcd,0x03,0xc7,0x44,0x6b,0x95,0x31,0x4c,0x8c,0x2c,0x0a,0x1b,0x47,0x03,0x06,0x03,0x06,0x2b,0x68,0x54,0x0c,0x43,0xea,0x74,0xef,0x4c,0x2b,0x1b,0x47,0x5c,0x6d,0x64,0xad,0x3a,0x47,0x4b,0x2a,0x0a,0xa5,0x0b,0x87,0x0b,0x87,0x14,0x08,0x0b,0xe7,0x14,0x08,0x14,0x08,0x03,0xe7,0x0b,0xe7,0x0b,0xe7,0x0b,0xe7,0x03,0xc7,0x03,0xc6,0x0b,0xe7
,0x0c,0x07,0x03,0xc7,0x03,0xc6,0x64,0xcd,0x54,0x8d,0x1b,0x46,0x29,0xc5,0x18,0xc2,0x19,0x23,0x33,0xa9,0x03,0x45,0x34,0x29,0x6d,0x2e,0x54,0xcc,0x0b,0xa6,0x44,0x8b,0x8d,0x50,0x94,0xf0,0x5c,0x0c,0x8c,0xd0,0x3b,0xc9,0x53,0xaa,0x83,0xed,0x4a,0x47,0x6b,0x4b,0x4a,0x48,0x73,0x8b,0x2b,0xa9,0x03,0xa7,0x13,0x47,0x02,0xc5,0x54,0x0b,0xa5,0x92,0x2b,0x89,0x43,0x6a,0x74,0x6e,0x63,0xab,0x74,0x4d,0x74,0x2d,0x5b,0xcb,0x7c,0x8e,0x43,0x8b,0x4b,0x69,0x94,0x8e,0x2b,0x67,0x02,0xe5,0x02,0xe5,0x02,0xe5,0x03,0x25,0x4c,0x0b,0x4a,0xc8,0x74,0xae,0x5c,0xce,0x4c,0x6c,0x02,0xe6,0x02,0xe6,0x5c,0x0c,0x94,0xf1,0x23,0x08,0x23,0x47,0x33,0xa9,0x03,0x06,0x0b,0x06,0x4c,0x0c,0x64,0x0c,0x64,0x4d,0x03,0x46,0x03,0x26,0x03,0x46,0x03,0x86,0x03,0xe6,0x03,0xe6,0x03,0xc7,0x03,0xc6,0x03,0xe7,0x03,0xe7,0x03,0xe7,0x03,0xe7,0x03,0xc6,0x0b,0xe7
,0x0c,0x07,0x03,0xc7,0x03,0xc6,0x4c,0x8b,0x6d,0x4f,0x0b,0x06,0x19,0x42,0x7b,0x68,0x18,0xc1,0x33,0x87,0x03,0x24,0x03,0x45,0x13,0xa6,0x13,0xe7,0x03,0x85,0x3c,0x4b,0x7c,0xef,0x63,0xab,0x64,0x2c,0x8c,0x6f,0x8d,0x51,0x85,0x10,0x84,0x0d,0x4a,0x27,0x84,0x0e,0x52,0x88,0x73,0x8b,0x2b,0x88,0x03,0xa6,0x03,0x26,0x02,0xc5,0x23,0x47,0x7c,0xef,0x12,0xa5,0x43,0x49,0x74,0x2e,0x63,0x8c,0x7c,0x4e,0x7c,0x0d,0x63,0x8b,0x84,0x4e,0x43,0x4a,0x3b,0x69,0x85,0x11,0x1b,0x67,0x03,0x26,0x03,0x05,0x02,0xe5,0x03,0x26,0x44,0x2b,0x8c,0xf0,0x3c,0x4b,0x03,0x26,0x1b,0x27,0xb6,0x35,0x95,0x12,0x31,0xc6,0x39,0x85,0x42,0x48,0xad,0xf4,0xd6,0xf9,0x4c,0x8d,0x4c,0x4c,0x4c,0x4c,0x75,0x30,0x6d,0x30,0x03,0xa7,0x03,0x66,0x03,0x26,0x03,0x46,0x03,0xa6,0x03,0xe7,0x03,0xe7,0x03,0xe7,0x03,0xe7,0x03,0xc6,0x03,0xe7,0x03,0xe7,0x03,0xe7,0x0c,0x07
,0x0c,0x07,0x03,0xc7,0x03,0xc6,0x54,0xcd,0x6c,0xce,0x13,0x06,0x19,0x23,0x18,0xc1,0x18,0xc1,0x33,0x88,0x03,0x44,0x03,0x65,0x03,0xa5,0x03,0xc6,0x03,0xa6,0x44,0xcc,0x75,0x0f,0x74,0xef,0x54,0x6b,0x8d,0x70,0x54,0xac,0x5c,0x6d,0x84,0x2d,0x4a,0x68,0x73,0xac,0x52,0xa8,0x73,0x8b,0x2b,0x68,0x1c,0x08,0x3b,0xe9,0x2b,0xa8,0x1b,0x27,0x85,0x10,0x3b,0x29,0x31,0xc6,0x31,0xe6,0x31,0xe6,0x31,0xe6,0x3a,0x06,0x32,0x06,0x32,0x06,0x29,0xe6,0x32,0xe8,0x54,0x0c,0x1b,0x68,0x03,0x66,0x03,0x05,0x02,0xe5,0x02,0xe5,0x13,0x07,0x33,0xea,0x13,0x46,0x03,0x26,0x1b,0xa8,0x85,0x51,0x9d,0x52,0x41,0xe6,0x5a,0x46,0x31,0xa5,0xb5,0xf4,0xd6,0xf9,0x54,0xce,0x5d,0x0f,0x2c,0x2a,0x03,0xa6,0x03,0xa6,0x03,0xc6,0x03,0xc6,0x03,0x66,0x03,0x46,0x03,0x46,0x03,0xa6,0x03,0xe7,0x03,0xe7,0x03,0xe7,0x03,0xc6,0x03,0xe7,0x03,0xe7,0x03,0xe7,0x0c,0x07
,0x0c,0x07,0x03,0xa6,0x03,0xc6,0x4c,0x8c,0x54,0x8c,0x13,0x05,0x3a,0x06,0x18,0xc2,0x19,0x01,0x33,0xa9,0x03,0x44,0x03,0x85,0x03,0xa6,0x03,0xa6,0x03,0xc6,0x03,0xc6,0x03,0xc6,0x03,0xa5,0x03,0xa6,0x13,0xa6,0x03,0xa5,0x3b,0xe9,0x8c,0x2e,0x52,0x88,0x7b,0xac,0x5a,0xc9,0x6b,0x6b,0x2a,0xe7,0x13,0x27,0x3b,0xea,0x23,0x68,0x3b,0x8a,0x8c,0x8f,0x63,0x6b,0x29,0x44,0x29,0x64,0x31,0xc6,0x31,0xe6,0x3a,0x07,0x3a,0x06,0x3a,0x06,0x31,0xc5,0x6b,0x6b,0x8c,0xcf,0x4c,0x2c,0x24,0x09,0x03,0x25,0x03,0x05,0x03,0x05,0x02,0xe5,0x02,0xe5,0x23,0xa8,0x23,0xc8,0x23,0xe9,0x85,0x30,0x95,0x52,0x41,0xc5,0x31,0x43,0x31,0xa4,0xad,0xd4,0xd6,0xd9,0x54,0xce,0x7d,0x51,0x3c,0x6b,0x03,0xa6,0x03,0xc6,0x03,0xc6,0x03,0xc6,0x03,0xc7,0x03,0x66,0x03,0x46,0x0b,0x26,0x03,0xa7,0x03,0xe6,0x03,0xe7,0x03,0xe7,0x03,0xe7,0x03,0xe7,0x03,0xe7,0x0c,0x07
,0x0c,0x08,0x03,0xe7,0x03,0xa6,0x65,0x0e,0x54,0x8b,0x23,0x47,0x21,0x43,0x4a,0x47,0x10,0xc1,0x53,0xeb,0x1b,0x26,0x23,0x88,0x64,0xac,0x4b,0xca,0x5c,0xad,0x03,0x04,0x03,0x65,0x03,0xe6,0x0b,0xc6,0x2c,0x29,0x03,0xa6,0x3c,0x09,0x8c,0x4e,0x52,0x88,0x83,0xed,0x63,0x0a,0x6b,0x4a,0x2a,0xc6,0x02,0xc4,0x02,0xe5,0x02,0xc5,0x43,0xeb,0xa5,0x32,0x84,0x2e,0x29,0xa5,0x42,0x27,0x31,0xa6,0x39,0xe6,0x3a,0x07,0x3a,0x27,0x3a,0x06,0x39,0xc5,0x8c,0x2e,0xa5,0x92,0x5c,0x4c,0x0b,0x05,0x03,0x25,0x03,0x25,0x03,0x25,0x03,0x06,0x03,0x05,0x3b,0xea,0x85,0x51,0x23,0xc9,0x7d,0x30,0x95,0x32,0x39,0xa5,0x41,0xe5,0x31,0xc5,0xad,0xb3,0xd6,0xb8,0x54,0xce,0x75,0x71,0x4c,0xcd,0x03,0xa6,0x03,0xc6,0x03,0xc6,0x03,0xc6,0x03,0xc6,0x03,0xc6,0x03,0x46,0x9e,0x14,0x2b,0xa8,0x03,0xa6,0x03,0xe7,0x03,0xe7,0x03,0xe7,0x03,0xe7,0x03,0xe7,0x0c,0x07
,0x04,0x08,0x03,0xe6,0x03,0xc6,0x03,0xa6,0x03,0x45,0x02,0xe5,0x11,0x02,0x21,0x02,0x10,0xa1,0x84,0xae,0x74,0x4d,0x74,0x8e,0x7c,0x4d,0x53,0x49,0x74,0xae,0x0a,0xe5,0x03,0x66,0x03,0xe6,0x44,0x6b,0x8c,0xb0,0x2c,0x2a,0x3c,0x0a,0x8c,0x4e,0x4a,0x27,0x6b,0x2b,0x5a,0xc9,0x63,0x2a,0x23,0x07,0x03,0x05,0x13,0x06,0x33,0xc9,0x4b,0xcb,0x8c,0x4f,0x6b,0x6c,0x31,0xc6,0x42,0x26,0x31,0xe6,0x3a,0x06,0x3a,0x06,0x3a,0x06,0x39,0xe6,0x31,0xa5,0x73,0x6b,0x8c,0xb0,0x43,0xcb,0x03,0x05,0x03,0x25,0x03,0x25,0x03,0x25,0x02,0xe5,0x03,0x05,0x34,0x0a,0x85,0x71,0x23,0xc8,0xa5,0xf3,0x8d,0x32,0x31,0xa5,0x62,0xe8,0x31,0xc5,0x9d,0x72,0xce,0xb7,0x44,0x8c,0x4c,0x8c,0x3c,0x6b,0x03,0xa6,0x03,0xa6,0x03,0xc6,0x03,0xc6,0x03,0xc6,0x03,0xe6,0x54,0xee,0xe7,0x3b,0xa6,0x55,0x0b,0x66,0x03,0xe7,0x03,0xe7,0x03,0xe7,0x04,0x07,0x03,0xe7,0x0c,0x07
,0x04,0x08,0x03,0xe6,0x03,0xc6,0x03,0xa6,0x03,0x65,0x0b,0x05,0x32,0x06,0x18,0xa1,0x11,0x02,0x33,0xa8,0x03,0x24,0x0b,0x85,0x24,0x08,0x24,0x29,0x1c,0x08,0x03,0xc6,0x3c,0x8b,0x6d,0x50,0x54,0x6c,0x8c,0xb0,0x43,0xca,0x43,0x89,0x8c,0x2e,0x4a,0x27,0x84,0x0e,0x5a,0xea,0x63,0x2a,0x22,0xc6,0x12,0xe6,0x64,0x6d,0x85,0x51,0x5c,0x6e,0x9d,0x32,0x7b,0xed,0x31,0xc6,0x3a,0x06,0x39,0xe6,0x31,0xe6,0x3a,0x06,0x42,0x07,0x42,0x27,0x31,0xc6,0x83,0xed,0xa5,0x73,0x54,0x4c,0x1b,0x87,0x03,0x25,0x03,0x25,0x03,0x05,0x02,0xe5,0x03,0x05,0x4c,0x8c,0x85,0x51,0x13,0x87,0x1b,0x67,0x1b,0x07,0x29,0xc6,0x39,0xc6,0x31,0xc6,0x33,0xa9,0x13,0x67,0x03,0x66,0x65,0x2f,0x3c,0x6b,0x03,0xa6,0x03,0xa6,0x03,0xc6,0x03,0xc6,0x03,0xc6,0x13,0xe8,0xc6,0xd8,0xe7,0x3b,0xd7,0x19,0x34,0x6b,0x04,0x07,0x04,0x06,0x04,0x06,0x04,0x06,0x03,0xe6,0x0c,0x07
,0x04,0x08,0x03,0xe7,0x03,0xc6,0x03,0xa6,0x03,0x45,0x02,0xe5,0x11,0x22,0x39,0xe4,0x10,0xa1,0x3b,0xa9,0x02,0xe5,0x0b,0x65,0x44,0x4a,0x3c,0x09,0x3c,0x4a,0x03,0xa6,0x0b,0xe7,0x0c,0x08,0x3c,0x8b,0x5c,0x2d,0x2b,0xe9,0x3b,0xca,0x94,0x6e,0x41,0xe6,0x31,0xc5,0x31,0xa5,0x63,0x0a,0x2a,0xe7,0x12,0xa5,0x8d,0x0f,0x5c,0x6d,0x3b,0xeb,0x94,0xd0,0x73,0xcd,0x31,0xe6,0x42,0x47,0x39,0xe6,0x39,0xe6,0x39,0xe6,0x42,0x27,0x31,0xc5,0x31,0xa5,0x7b,0xac,0x95,0x12,0x43,0xcb,0x0b,0x06,0x03,0x25,0x03,0x25,0x03,0x25,0x02,0xe5,0x03,0x05,0x1b,0x87,0x44,0x2b,0x1b,0xa8,0x03,0x05,0x1b,0x26,0x31,0xe6,0x39,0xe6,0x29,0xa5,0x13,0x06,0x03,0x26,0x0b,0x66,0x54,0xad,0x4c,0xcd,0x03,0xa6,0x03,0xa6,0x03,0xc6,0x03,0xc6,0x03,0xc6,0x6d,0x50,0xa6,0x75,0x54,0xad,0x34,0x2b,0x8d,0xf3,0x0c,0x07,0x03,0xe6,0x03,0xe6,0x03,0xe6,0x03,0xc6,0x0b,0xe7
,0x04,0x28,0x03,0xe7,0x03,0xc6,0x03,0xa5,0x03,0x45,0x02,0xe5,0x11,0x02,0x39,0xc5,0x10,0xa1,0x6c,0x6d,0x43,0x8a,0x64,0x2d,0x8c,0xaf,0x52,0xe8,0x84,0xcf,0x0a,0xe5,0x03,0xc6,0x03,0xe6,0x03,0xc6,0x0b,0xa6,0x03,0xc7,0x3c,0x4a,0x8c,0x8e,0x52,0x88,0x31,0x85,0x29,0x64,0x7b,0xab,0x22,0xc7,0x23,0x47,0x94,0xf0,0x6c,0x6d,0x43,0xca,0x9c,0xf1,0x73,0x8c,0x31,0xc5,0x42,0x06,0x39,0xc6,0x39,0xe6,0x42,0x27,0x3a,0x06,0x29,0xa5,0x29,0x84,0x7b,0x8c,0x95,0x32,0x4c,0x0c,0x03,0x25,0x03,0x25,0x03,0x25,0x03,0x05,0x02,0xe5,0x03,0x05,0x13,0x66,0x3c,0x4b,0x13,0x67,0x7d,0x51,0x64,0x4d,0x29,0xc5,0x42,0x26,0x31,0xa5,0x64,0x2c,0xae,0x35,0x3c,0x2b,0x3c,0x6c,0x3c,0x6c,0x03,0xa6,0x03,0xa6,0x03,0xc6,0x03,0xe6,0x24,0x4a,0xbe,0xb7,0x6d,0x50,0x3c,0x4b,0xb6,0x56,0xe7,0x3a,0x65,0x50,0x04,0x07,0x03,0xe7,0x03,0xe6,0x03,0xe6,0x04,0x07
,0x04,0x28,0x03,0xe7,0x03,0xe6,0x03,0xa6,0x03,0x65,0x03,0x05,0x29,0xc5,0x18,0xc2,0x18,0xe2,0x4c,0x0a,0x33,0xe8,0x3c,0x4a,0x44,0x6b,0x3c,0x2a,0x3c,0x6a,0x0b,0x05,0x03,0x45,0x03,0xe6,0x03,0xe6,0x03,0xc6,0x03,0xc6,0x13,0xc7,0x64,0x6c,0x9c,0xd0,0x7b,0x8c,0x8c,0x8f,0x84,0x4e,0x12,0xe5,0x13,0x06,0x9d,0x93,0x6c,0x8f,0x43,0xaa,0xa5,0x73,0x7c,0x0e,0x31,0xc5,0x31,0xe6,0x31,0xa5,0x31,0xc6,0x39,0xe6,0x39,0xe6,0x31,0x85,0x31,0x85,0x84,0x2e,0x9d,0x94,0x4c,0x2c,0x0b,0x26,0x03,0x05,0x03,0x25,0x03,0x25,0x02,0xe5,0x03,0x05,0x4c,0x8c,0x44,0x6c,0x23,0xa9,0x85,0x10,0x8d,0x11,0x29,0xa5,0x39,0x44,0x42,0x05,0x9d,0x52,0xce,0x98,0x54,0xad,0x4c,0xad,0x4c,0xcd,0x03,0xa6,0x03,0xa6,0x03,0xc6,0x03,0xc7,0x9e,0x34,0xdf,0x1a,0xd6,0xf9,0xdf,0x5a,0xce,0xd8,0xce,0xb8,0xc6,0xd8,0x14,0x08,0x03,0xe7,0x03,0xe6,0x03,0xe6,0x0c,0x07
,0x04,0x28,0x03,0xc6,0x03,0xc6,0x03,0xa6,0x03,0x65,0x03,0x05,0x19,0x42,0x31,0x83,0x10,0xc1,0x3b,0xa9,0x03,0x25,0x03,0x85,0x0b,0x86,0x0b,0x86,0x0b,0xc7,0x03,0x25,0x03,0x45,0x03,0xe6,0x03,0xe6,0x03,0xe6,0x03,0xe6,0x03,0xa6,0x23,0xe9,0x64,0xad,0xa5,0x93,0x8d,0x30,0x33,0xc9,0x34,0x4a,0x4b,0xeb,0x7d,0x30,0x54,0x6e,0x3b,0xec,0x4b,0xec,0x43,0x49,0x3a,0x47,0x42,0x47,0x3a,0x27,0x42,0x48,0x42,0x48,0x3a,0x27,0x42,0x48,0x32,0x06,0x1a,0x04,0x23,0x28,0x12,0xe6,0x33,0xe9,0x03,0x05,0x03,0x05,0x03,0x05,0x02,0xe5,0x03,0x05,0x3c,0x2a,0x4c,0x4b,0x2b,0xa9,0x7d,0x30,0x9d,0x92,0x31,0xe6,0x10,0x40,0x4a,0x68,0xad,0xb3,0xce,0xb8,0x54,0xcd,0x65,0x0e,0x44,0x8c,0x03,0xa6,0x03,0xc6,0x03,0xc6,0x14,0x08,0x96,0x14,0x96,0x14,0x9e,0x14,0x9e,0x14,0x9d,0xf4,0x9d,0xf4,0x7d,0xb2,0x1c,0x49,0x03,0xe6,0x03,0xe6,0x03,0xe6,0x0c,0x08
,0x04,0x07,0x03,0xe7,0x03,0xc6,0x03,0xa6,0x03,0x65,0x03,0x25,0x19,0x42,0x52,0x86,0x10,0xc2,0x7c,0x6e,0x43,0x8a,0x4b,0xaa,0xa5,0x72,0x6b,0xab,0x8d,0x51,0x02,0x84,0x03,0x45,0x04,0x06,0x03,0xe6,0x03,0xe6,0x03,0xe6,0x03,0xc6,0x03,0xa5,0x0b,0x45,0x13,0x26,0x0b,0x05,0x23,0xa7,0x34,0x0a,0x74,0xcf,0x6c,0xce,0x54,0x4d,0x54,0x4d,0x5c,0x2c,0x5b,0xec,0x5b,0xaa,0x8c,0x8f,0x6b,0xcc,0x84,0x6e,0x7c,0x6e,0x63,0x8b,0x84,0xaf,0x4b,0x8a,0x0a,0x65,0x7c,0xef,0x4c,0x4b,0x03,0x46,0x03,0x26,0x03,0x46,0x03,0x46,0x03,0x26,0x03,0x46,0x2c,0x09,0x33,0xc9,0x33,0x88,0x85,0x51,0x95,0x52,0x31,0xe5,0x62,0xc7,0x42,0x26,0xa5,0x73,0xd6,0xd8,0x54,0xcd,0x6d,0x2f,0x4c,0xcd,0x03,0xa7,0x03,0xc7,0x03,0xc7,0x03,0xe7,0x03,0xe7,0x03,0xe7,0x03,0xe7,0x03,0xa7,0x03,0x87,0x03,0x66,0x03,0xe8,0x03,0xc7,0x03,0xe6,0x03,0xe6,0x03,0xe6,0x0c,0x08
,0x04,0x07,0x03,0xe7,0x03,0xe7,0x03,0xc6,0x03,0x85,0x0b,0x66,0x29,0xe5,0x19,0x02,0x21,0x43,0x5c,0x8d,0x2c,0x2a,0x23,0xc8,0x64,0x8d,0x4b,0xca,0x54,0x6c,0x02,0xc4,0x03,0x24,0x03,0xe7,0x03,0xe7,0x03,0xe6,0x03,0xe6,0x03,0xc6,0x03,0xa6,0x03,0x65,0x02,0xa4,0x1a,0xc5,0x8c,0x8e,0x8c,0xef,0x94,0xf1,0x54,0x4c,0x6c,0xae,0xa5,0xb4,0xad,0xb4,0x74,0xf0,0x3b,0x4a,0x6c,0x0d,0x5b,0x8b,0x6c,0x2d,0x5b,0xab,0x5b,0x8b,0x6c,0x2d,0x43,0x48,0x13,0x26,0x94,0xd0,0x5c,0x2c,0x3c,0x6c,0x54,0xad,0x2c,0x0a,0x03,0x46,0x03,0x46,0x03,0x25,0x03,0x25,0x03,0x05,0x1b,0x47,0xa5,0xd4,0x9d,0x73,0x31,0xe6,0x4a,0x47,0x21,0x64,0x95,0x52,0xd6,0xd8,0x54,0xad,0x65,0x2f,0x54,0xee,0x03,0xc7,0x03,0xc7,0x03,0xc7,0x03,0xe7,0x65,0x70,0xa6,0x76,0xa6,0x76,0xae,0x76,0xa6,0x56,0xae,0x75,0xa6,0x55,0x65,0x90,0x03,0xe6,0x03,0xe6,0x03,0xe6,0x0c,0x08
,0x04,0x28,0x03,0xe7,0x03,0xe6,0x03,0xc6,0x03,0xa6,0x03,0x85,0x33,0xc9,0x33,0x67,0x33,0x88,0x1b,0xc7,0x03,0x85,0x0b,0xe7,0x0b,0xe7,0x03,0xe6,0x03,0xc6,0x03,0x45,0x02,0xa4,0x03,0x46,0x03,0x46,0x03,0x45,0x03,0x45,0x03,0x25,0x03,0x25,0x33,0xc9,0x43,0xaa,0x64,0x2d,0x7b,0xec,0x7c,0x4e,0xa5,0x31,0x54,0x8d,0x64,0x4c,0x6b,0xcc,0x74,0x0d,0x6c,0x4d,0x0a,0xc5,0x1b,0x27,0x12,0xe6,0x0a,0xe6,0x0a,0xc6,0x0a,0xa6,0x0a,0xe6,0x0a,0xe5,0x13,0x87,0x8d,0x31,0x64,0xae,0x1c,0x09,0x2c,0x29,0x0b,0xc7,0x03,0xc7,0x03,0xc7,0x03,0xa7,0x03,0xa7,0x03,0x67,0x03,0x26,0x4c,0x0c,0x54,0x4c,0x53,0x4a,0x42,0xa8,0x4a,0xe9,0x44,0x0b,0x44,0x2b,0x0b,0x67,0x0b,0x67,0x0b,0x67,0x03,0x86,0x03,0xa7,0x03,0xc7,0x1c,0x08,0x5d,0x4f,0x34,0x6b,0x44,0xad,0x44,0x8c,0x34,0x2b,0x23,0xc9,0x3c,0xac,0x03,0xe7,0x03,0xe6,0x03,0xe7,0x03,0xe7,0x14,0x08
,0x04,0x28,0x04,0x07,0x04,0x06,0x03,0xe6,0x03,0xa6,0x03,0x85,0x03,0x24,0x0b,0x05,0x03,0x05,0x23,0xc8,0x0b,0x86,0x44,0x6a,0x54,0xcc,0x1b,0xe7,0x03,0xa7,0x03,0x45,0x03,0x66,0x03,0x26,0x03,0x46,0x03,0x46,0x03,0x46,0x03,0x46,0x03,0x46,0x23,0xa8,0x3c,0x4c,0x4c,0x6d,0x9d,0xf4,0x64,0xce,0x6d,0x2f,0x33,0xca,0x75,0x10,0x9d,0xb3,0x9d,0x92,0x85,0x50,0x02,0xc5,0x13,0x26,0x13,0x06,0x0b,0x06,0x13,0x67,0x0b,0x46,0x03,0x26,0x03,0x05,0x0a,0xc5,0x43,0xca,0x23,0xc9,0x03,0xc7,0x03,0x46,0x03,0x46,0x03,0x46,0x03,0x25,0x03,0x25,0x03,0x05,0x03,0x26,0x03,0x26,0x02,0xc6,0x02,0xe5,0x1b,0x26,0x12,0xc5,0x1b,0x26,0x0b,0x05,0x03,0x05,0x03,0x26,0x03,0x26,0x03,0x26,0x03,0x46,0x03,0x26,0x03,0x66,0x7d,0xb1,0x44,0xed,0xa6,0x55,0xe7,0x3a,0xe7,0x3a,0x6d,0x30,0xae,0x15,0x8e,0x13,0x03,0xe7,0x03,0xe6,0x03,0xe7,0x03,0xe7,0x13,0xe8
,0x04,0x08,0x03,0xe7,0x03,0xe6,0x03,0xe6,0x03,0xa6,0x03,0x85,0x03,0x64,0x23,0xe9,0x23,0xa7,0x65,0x2f,0x03,0xa6,0x64,0xad,0x6c,0x0c,0x64,0x0c,0x74,0xcf,0x0b,0x06,0x03,0x05,0x03,0xa6,0x03,0xc6,0x03,0xc6,0x0c,0x28,0x1c,0x29,0x1c,0x09,0x24,0x49,0x24,0x29,0x24,0x29,0x2c,0x09,0x0b,0x26,0x3c,0x2b,0x54,0xcd,0x0b,0x46,0x43,0xea,0x3b,0xca,0x2b,0x89,0x3b,0xea,0x2b,0x88,0x4c,0x2b,0x3b,0xca,0x4c,0x8d,0x2b,0xa9,0x3b,0xeb,0x2b,0x68,0x7c,0xef,0x3b,0xa9,0x64,0x8d,0x75,0x30,0x75,0x30,0x03,0x87,0x2c,0x2a,0x6d,0x30,0x3c,0x6c,0x2b,0xe9,0x2c,0x2a,0x33,0xea,0x23,0x28,0x1a,0xc6,0x2b,0x69,0x23,0x07,0x23,0x47,0x13,0x26,0x03,0x05,0x03,0x25,0x03,0x25,0x03,0x25,0x03,0x25,0x03,0x66,0x1b,0xa8,0xce,0xf9,0xc6,0xd8,0x3c,0x8c,0xc6,0xd8,0xce,0xf9,0x4c,0x8d,0xd7,0x5a,0x2c,0x6b,0x14,0x28,0x03,0xe6,0x03,0xe7,0x03,0xe7,0x0b,0xe8
,0x04,0x08,0x03,0xc6,0x03,0xe6,0x03,0xe6,0x03,0xc6,0x03,0x85,0x03,0xc6,0x24,0x49,0x24,0x08,0x3c,0x8b,0x0b,0xc7,0x85,0x10,0x9c,0xcf,0x8c,0x8e,0x84,0xaf,0x12,0xc6,0x02,0xa4,0x03,0x05,0x03,0x65,0x03,0xc6,0x1c,0x28,0x9e,0x14,0x75,0x50,0x96,0x13,0x85,0xd2,0x85,0xf2,0x9d,0xf4,0x23,0xa9,0x7d,0x31,0x6c,0xcf,0x33,0xca,0x5c,0x4d,0x74,0xce,0x95,0xd2,0x85,0x51,0x6c,0xae,0x4c,0x2c,0x64,0x8d,0x7d,0x0f,0x6c,0xae,0x64,0xad,0x5c,0xcd,0x7d,0x71,0x4c,0x4c,0x54,0x6c,0x7d,0x2f,0xa5,0xf3,0x3c,0x4c,0x6d,0x2f,0x85,0x71,0x7d,0x71,0x7d,0x71,0x4c,0x2c,0x7d,0x30,0x7d,0x51,0x6c,0xae,0x8d,0x51,0x6c,0x8e,0x4c,0x0b,0x4c,0x4c,0x02,0xe5,0x02,0xe5,0x03,0x05,0x03,0x06,0x03,0x86,0x02,0xe5,0x75,0x10,0xd7,0x3a,0xd7,0x19,0x8e,0x33,0x55,0x0e,0x6c,0xef,0x9d,0xf4,0x9e,0x34,0x3c,0xac,0x9e,0x34,0x2c,0x6a,0x03,0xe6,0x03,0xe7,0x0b,0xe8
,0x04,0x08,0x03,0xe7,0x03,0xe6,0x04,0x06,0x03,0xe6,0x03,0xc6,0x03,0xc6,0x0b,0xe7,0x03,0xa6,0x0b,0xc6,0x54,0xcc,0x9d,0x92,0x74,0xce,0x43,0xaa,0x44,0x0a,0x53,0xcb,0x32,0x87,0x19,0xe4,0x4b,0x68,0x4c,0x0b,0x03,0x46,0x1c,0x09,0x44,0xac,0x7c,0xef,0x5c,0xad,0x14,0x29,0x14,0x29,0x24,0x09,0x2b,0xc9,0x24,0x0a,0x13,0x68,0x2b,0xa9,0x23,0x67,0x1b,0x46,0x13,0x46,0x1b,0x05,0x2b,0x88,0x2b,0xa8,0x1b,0x26,0x23,0x07,0x12,0xe5,0x1a,0xe6,0x2b,0x68,0x23,0x68,0x33,0xea,0x23,0x88,0x23,0xe9,0x03,0xe7,0x1c,0x48,0x4c,0xac,0x85,0x71,0x64,0x8d,0x7d,0x71,0x3c,0x6c,0x0b,0xa7,0x13,0x87,0x2c,0x09,0x13,0x87,0x2b,0xe9,0x13,0xc7,0x03,0x66,0x03,0x86,0x03,0x66,0x02,0xa5,0x02,0x84,0x03,0x86,0x03,0x05,0x0b,0x86,0x0b,0xa7,0x14,0x28,0x85,0xf2,0x3c,0x6b,0xd7,0x39,0x3c,0x8b,0x2c,0x6a,0x75,0x70,0x1c,0x29,0x03,0xe6,0x03,0xe7,0x13,0xe8
,0x04,0x08,0x03,0xe7,0x03,0xe6,0x03,0xe6,0x03,0xe6,0x03,0xc6,0x03,0xc6,0x03,0xa6,0x03,0xa6,0x03,0x65,0x5c,0x6c,0xad,0x92,0x54,0x6c,0x54,0x2c,0x0a,0xe5,0x4b,0xcb,0x32,0x05,0x21,0x84,0x42,0x67,0x74,0xaf,0x1b,0x87,0x95,0x50,0x84,0xcf,0xad,0x51,0x74,0x8d,0x65,0x4e,0x24,0x4a,0x75,0x0f,0x1b,0xe9,0x1b,0xa8,0x1b,0xc8,0x7c,0xf0,0x84,0xef,0x8c,0xcf,0x74,0xcf,0x03,0x24,0x03,0x65,0x0b,0x85,0x03,0x04,0x02,0xa4,0x53,0xeb,0x84,0xcf,0x84,0xcf,0x7c,0xcf,0x54,0xcc,0x6c,0xed,0x44,0xac,0x0b,0xe7,0x03,0xe6,0x4c,0x6c,0xc6,0x77,0x6c,0x2d,0xb5,0xd4,0x64,0xce,0x44,0x4b,0x54,0xad,0x03,0x86,0x03,0x65,0x03,0x85,0x03,0x85,0x03,0x85,0x03,0x66,0x02,0xa4,0x02,0xc5,0x02,0xc6,0x03,0x45,0x02,0xe5,0x03,0x46,0x03,0xa6,0x03,0xe6,0x0b,0xc7,0x0b,0x86,0x13,0xa7,0x03,0x25,0x03,0xe7,0x03,0xe7,0x03,0xc7,0x03,0xc7,0x03,0xe7,0x13,0xe8
,0x04,0x07,0x03,0xe6,0x03,0xe6,0x03,0xe6,0x03,0xc6,0x03,0xc6,0x03,0xc6,0x03,0xc6,0x03,0xa5,0x03,0xa5,0x4b,0xe9,0x8c,0x0b,0x74,0x4d,0x7c,0x4d,0x2b,0x68,0x0a,0x85,0x29,0xe5,0x29,0x64,0x52,0x87,0x74,0x4d,0x2b,0xe9,0x94,0x8e,0x84,0x8e,0xa4,0xcf,0x6c,0x2c,0x64,0xac,0x2b,0xe8,0x5c,0x8c,0x3c,0x0a,0x4c,0x8b,0x54,0xac,0x8d,0x30,0x84,0x2d,0x7b,0xec,0x7c,0xae,0x03,0x64,0x03,0x65,0x03,0x04,0x02,0x84,0x02,0x64,0x53,0xab,0x7c,0x0c,0x84,0x4e,0x74,0x2e,0x1b,0xc8,0x54,0xec,0x6d,0x70,0x4c,0xec,0x03,0xe7,0x3c,0x0b,0x64,0x2d,0x4b,0xcb,0x6c,0xce,0x34,0x6c,0x24,0x29,0x24,0x09,0x03,0x66,0x03,0x45,0x03,0x85,0x03,0x85,0x03,0x85,0x03,0x86,0x02,0xa4,0x02,0xa4,0x02,0xc5,0x03,0x66,0x02,0xe5,0x03,0x66,0x03,0xa6,0x03,0xe6,0x03,0xc6,0x03,0xa6,0x03,0x45,0x03,0x45,0x03,0x86,0x03,0x66,0x0b,0x25,0x03,0x66,0x03,0x86,0x13,0xe8
,0x04,0x07,0x03,0xc6,0x04,0x06,0x04,0x06,0x03,0xe6,0x03,0xc6,0x03,0xc6,0x03,0xc6,0x1b,0xe8,0x0b,0xc6,0x5c,0x4b,0x9d,0x10,0x84,0xae,0x94,0xaf,0x33,0xe9,0x8d,0x51,0x42,0x87,0x21,0x84,0x53,0x09,0x8d,0x72,0x5c,0x8c,0x8c,0xce,0x95,0x10,0x94,0xf0,0x64,0x6d,0x33,0xea,0x2b,0xc9,0x3b,0xa9,0x03,0x46,0x03,0x85,0x03,0x85,0x44,0x0a,0x7c,0xae,0x95,0x11,0xad,0x94,0x7d,0x0f,0x85,0x50,0x85,0x10,0x8d,0x11,0x84,0xf0,0xad,0xb4,0xa5,0x93,0x5c,0x0b,0x33,0xa9,0x13,0x06,0x65,0x0f,0x4c,0xee,0x44,0x4b,0x03,0x05,0x33,0x68,0xb5,0xf5,0x2b,0x89,0x03,0xa6,0x03,0xa6,0x03,0xa6,0x03,0x86,0x53,0xeb,0x74,0x6e,0x03,0x25,0x03,0x85,0x03,0x85,0x03,0x65,0x02,0xa4,0x02,0xc5,0x02,0xc5,0x03,0x66,0x02,0xe6,0x03,0x66,0x03,0xa6,0x03,0xc6,0x14,0x07,0x13,0xe7,0x03,0x65,0x03,0x45,0x03,0x45,0x02,0xe5,0x02,0xe5,0x03,0xa7,0x03,0x86,0x0b,0xe8
,0x0c,0x07,0x04,0x06,0x04,0x06,0x03,0xe6,0x5d,0x0e,0x3c,0xab,0x03,0xc5,0x03,0xa6,0x3c,0xab,0x2c,0x69,0x34,0x29,0x3b,0xa9,0x5c,0x8d,0x64,0xce,0x1b,0xe8,0x03,0x45,0x1a,0x84,0x23,0x07,0x1b,0x27,0x03,0x45,0x03,0x45,0x34,0x2a,0x2c,0x29,0x34,0x4a,0x34,0x6b,0x3c,0x6b,0x5c,0xad,0x3b,0xca,0x85,0x0f,0x7c,0xef,0x44,0x0a,0x7c,0xee,0xbd,0xb4,0x9c,0xb1,0x94,0x70,0x8c,0x2e,0x7b,0xcd,0x6b,0x2a,0x6b,0x2a,0x62,0xea,0x5a,0xc9,0x6b,0x4c,0x94,0xf0,0x4c,0x2c,0x74,0xef,0x8c,0xd0,0x7c,0xcf,0x8d,0x31,0x7d,0x10,0x64,0x4c,0xc6,0x15,0x54,0x6d,0x34,0x8b,0x34,0x6b,0x3c,0x4a,0x3c,0x4a,0x74,0x4d,0xa5,0x52,0x4c,0x2c,0x03,0x86,0x03,0x65,0x03,0x04,0x03,0x05,0x02,0xc4,0x0a,0xc5,0x03,0x46,0x8d,0xb2,0x75,0x0f,0x03,0xa6,0x03,0xc6,0x4c,0xcc,0x54,0xed,0x03,0xc6,0x03,0x65,0x03,0x66,0x03,0x46,0x02,0xc5,0x03,0xa7,0x03,0x66,0x0c,0x08
,0x04,0x07,0x04,0x06,0x04,0x06,0x03,0xe6,0x96,0x13,0x75,0x70,0x6c,0xee,0x6c,0xcd,0x6c,0xce,0x54,0x8c,0x5c,0x8c,0x4c,0x8b,0x34,0x6a,0x03,0x65,0x02,0xa4,0x02,0xe5,0x2b,0xe9,0x4c,0x2b,0x24,0x09,0x03,0x85,0x1b,0x86,0x1b,0x86,0x13,0xa6,0x03,0xa5,0x24,0x2a,0x64,0xce,0xad,0x31,0x8c,0x8e,0xdd,0xf0,0xc5,0x8f,0x84,0x8e,0x7b,0xec,0x31,0xa4,0x29,0x64,0x4a,0x47,0x3a,0x06,0x52,0x67,0x4a,0x47,0x52,0x88,0x42,0x06,0x42,0x07,0x21,0x23,0x39,0xc5,0xa5,0x52,0xa5,0x52,0x9c,0xd0,0x53,0x0a,0x9d,0x11,0xa5,0xd4,0x43,0xcb,0xad,0xb5,0x4c,0x2c,0x65,0x4f,0x03,0xc7,0x03,0xa6,0x03,0xa6,0x5c,0x0c,0x9d,0x52,0x3b,0xeb,0x13,0xc8,0x1b,0x68,0x03,0x45,0x03,0x05,0x02,0xc5,0x02,0xc5,0x03,0x65,0x74,0xef,0x74,0xee,0x6c,0xee,0x6c,0xed,0x6c,0xee,0x5c,0xac,0x6c,0xcd,0x54,0xac,0x2b,0xc9,0x03,0x87,0x02,0xe6,0x03,0xa7,0x03,0x86,0x0b,0xe8
,0x0c,0x07,0x34,0x6a,0x4c,0xcc,0x4c,0xcb,0x55,0x0d,0x0b,0xa6,0x9d,0x71,0xa4,0xcf,0x9d,0x51,0x5c,0x8c,0x7c,0x4c,0x54,0x2a,0x4c,0xac,0x44,0x8c,0x5c,0x4c,0x5c,0x6d,0x3c,0x2b,0x1b,0xc8,0x0b,0x86,0x03,0x45,0xa5,0x92,0xce,0x55,0x74,0xae,0x02,0xe5,0x3b,0xea,0x6c,0xae,0x7b,0xec,0x94,0x8d,0xe5,0x6b,0xdd,0x4b,0x84,0x0c,0x63,0x09,0x21,0x64,0x29,0x84,0x73,0x6c,0x4a,0x47,0x6b,0x8c,0x63,0x4a,0x6b,0x4b,0x5a,0xe9,0x63,0x0a,0x29,0x64,0x29,0x64,0x9d,0x11,0xa5,0xd4,0x7c,0x8e,0x5b,0xec,0x7c,0xcf,0xb6,0x15,0x1b,0x28,0x02,0xa6,0x1b,0xc9,0x85,0x91,0x24,0x4a,0x03,0xc6,0x03,0xc6,0x02,0xc6,0x02,0x85,0x3c,0x6b,0x4c,0x6b,0x5c,0xcd,0x03,0x25,0x03,0x86,0x3b,0xa9,0x54,0x4c,0x4c,0x6b,0x54,0x6c,0x2c,0x28,0x8c,0xaf,0x9c,0xed,0x84,0x6e,0x6c,0xed,0x9c,0x8d,0x7c,0xee,0x44,0x2b,0x44,0xab,0x64,0x8d,0x6d,0x2f,0x3c,0x8b,0x0c,0x08
,0x0c,0x07,0x3c,0x8b,0x55,0x0e,0x4c,0xed,0x55,0x0d,0x0b,0xc6,0x95,0x71,0xa4,0xcf,0x95,0x31,0x54,0x4b,0x8c,0x8e,0x5c,0x0a,0x4c,0xac,0x65,0x0d,0x5c,0x8d,0x6c,0xce,0x33,0xaa,0x03,0x66,0x03,0x64,0x0b,0x44,0xd5,0xad,0xe5,0x8b,0x94,0x8c,0x02,0x64,0x2b,0xa8,0x4b,0xcb,0x74,0x6d,0x94,0xcd,0xe5,0x6b,0xdd,0x4a,0x74,0x0b,0x6b,0x2a,0x31,0x84,0x29,0x64,0x42,0x06,0x41,0xe6,0x41,0xe6,0x39,0xc5,0x31,0x65,0x29,0x44,0x31,0x64,0x4a,0x26,0x8c,0x0e,0x94,0xf1,0x8c,0xf1,0xa5,0x11,0x63,0x4b,0xad,0x92,0xad,0xf4,0x5c,0x4c,0xad,0xf4,0x44,0x0b,0x75,0x70,0x0c,0x08,0x03,0xa7,0x03,0xc7,0x5c,0x4d,0x95,0x73,0x3c,0x2b,0x03,0x45,0x03,0x46,0x03,0xc6,0x03,0xc7,0x43,0xca,0x74,0xee,0x54,0x8c,0x54,0x6c,0x2c,0x29,0x84,0x8d,0xa4,0xae,0x7c,0x8e,0x74,0xee,0xa4,0xce,0x7c,0xee,0x44,0x4b,0x6d,0x2e,0x5c,0x6c,0x6d,0x0e,0x3c,0x6b,0x0c,0x08
,0x0c,0x28,0x03,0xc6,0x03,0xe6,0x04,0x06,0x03,0xe6,0x0b,0xc6,0x64,0x8d,0x4b,0x07,0x3b,0x48,0x23,0xc8,0x12,0x85,0x02,0xc5,0x44,0x8a,0x03,0xc5,0x03,0x24,0x03,0x85,0x02,0xa5,0x03,0x46,0x13,0x45,0x13,0x25,0xcd,0x4b,0xe5,0x09,0x94,0x6b,0x74,0x4d,0x7c,0xae,0x53,0xcb,0xa5,0x71,0x9c,0xce,0xdc,0xe9,0xcc,0xaa,0x4b,0x68,0x6b,0xab,0xa4,0xf1,0xa4,0xd1,0x94,0x70,0x94,0x4f,0x8c,0x4e,0x94,0x6f,0x9c,0x90,0x9c,0x90,0xad,0x12,0x9c,0xd0,0x94,0xf0,0x4c,0x0c,0x4b,0xcb,0x74,0x8e,0x53,0x8b,0x7c,0xaf,0x9d,0x93,0x4b,0xaa,0xc6,0x56,0x54,0x2c,0x24,0x4a,0x14,0x08,0x14,0x08,0x13,0xe8,0x74,0x6d,0xb5,0xf6,0x4c,0x4b,0x03,0x45,0x03,0x46,0x03,0xc7,0x03,0xc7,0x02,0xe5,0x02,0xe5,0x03,0x45,0x03,0x04,0x2c,0x49,0x54,0x0c,0x43,0x28,0x43,0x8a,0x1b,0xe8,0x1b,0x05,0x13,0x26,0x44,0x2a,0x03,0xa7,0x02,0xc5,0x03,0xa6,0x03,0x45,0x0c,0x07
,0x0c,0x08,0x1c,0x28,0x3c,0xcb,0x3c,0xcc,0x2c,0x8a,0x0b,0xc6,0x6c,0x6c,0x9c,0xad,0x63,0xeb,0x1a,0xc6,0x84,0x4d,0x4b,0x48,0x54,0x4b,0x24,0x49,0x44,0x8b,0x3c,0x2a,0x1b,0x88,0x44,0x4b,0x84,0xcf,0x7c,0x4d,0xcd,0x4c,0xdd,0x29,0x94,0x4a,0x6b,0xab,0x6b,0xcc,0x5b,0xcc,0x94,0x6e,0x84,0x6e,0xac,0x6c,0xa4,0x8c,0x3b,0xc9,0x12,0xc5,0x53,0x8a,0x6b,0xec,0x6c,0x0d,0x74,0x8e,0x95,0x11,0x9d,0x32,0x84,0xd0,0x9d,0x32,0x84,0x90,0x7c,0x6e,0x4b,0xaa,0x2b,0x68,0x0a,0xc6,0x6c,0x6d,0x6c,0x8e,0x5c,0x2d,0x7c,0xcf,0x64,0x2c,0xb6,0x15,0x6c,0xaf,0x5c,0xee,0x55,0x0d,0x2c,0x8a,0x2c,0x6b,0x6c,0x4d,0x95,0x74,0x23,0x68,0x03,0x45,0x03,0x46,0x03,0xc7,0x03,0xe7,0x33,0xca,0x23,0x67,0x1b,0xc7,0x02,0xe4,0x2c,0x28,0x5b,0xea,0x94,0x8d,0x4b,0xa9,0x33,0x67,0x94,0xad,0x63,0xeb,0x4c,0x8b,0x34,0x09,0x23,0x88,0x03,0xc7,0x03,0x85,0x0c,0x07
,0x0c,0x07,0x44,0xcc,0x5d,0x0d,0x6d,0x4f,0x4c,0xcb,0x0b,0xa5,0x7c,0xce,0xa4,0xaf,0x74,0x2d,0x2a,0xc6,0x8c,0x8e,0x53,0x8a,0x43,0xe9,0x64,0xed,0x6d,0x2f,0x6c,0xce,0x3b,0xca,0x64,0xcd,0x84,0x4d,0x7b,0xca,0xb4,0x6a,0xbb,0xa6,0x8b,0xea,0x73,0xcc,0x63,0xcc,0x6c,0x4c,0x7b,0xec,0x84,0xcf,0x6c,0x4e,0x74,0x8e,0x4c,0x4b,0x5c,0x0c,0x84,0x6e,0x94,0xcf,0x64,0x8d,0x4b,0x89,0x63,0xab,0x73,0xab,0x54,0x0b,0x73,0xab,0x7c,0x4f,0x94,0xce,0x84,0x2c,0x8d,0x31,0x7c,0xae,0x7c,0x2e,0x7c,0x4e,0x8c,0xef,0xa5,0x10,0x3c,0x4b,0x4c,0x0c,0x74,0xf0,0x7d,0x72,0x4c,0xef,0x03,0xc6,0x03,0xa7,0x03,0x05,0x02,0xa5,0x02,0xe5,0x03,0xa5,0x03,0x65,0x03,0xe6,0x03,0xc6,0x4c,0x0a,0x5c,0x8d,0x23,0xe7,0x03,0x04,0x24,0x08,0x6c,0x2b,0x94,0x2a,0x5c,0x2b,0x54,0x09,0x9c,0x8d,0x7c,0x8e,0x44,0x2a,0x4c,0x2a,0x4c,0x8b,0x0b,0xa6,0x03,0xa6,0x0c,0x08
,0x0c,0x27,0x03,0xe7,0x03,0xe6,0x03,0xc6,0x03,0xc5,0x0b,0xa5,0x3c,0x29,0x22,0xe5,0x0a,0xe4,0x03,0x05,0x1a,0x64,0x01,0xe3,0x44,0x09,0x03,0x05,0x03,0xa6,0x03,0x25,0x0b,0x06,0x4c,0x6b,0x6c,0x4d,0x63,0xeb,0x84,0x6d,0x5b,0x49,0x6c,0x0d,0x7c,0x0d,0x7c,0x6e,0x74,0xae,0x95,0x32,0x54,0x2c,0x23,0x28,0x23,0x68,0x02,0x64,0x3b,0x88,0x4b,0xea,0x4b,0xa9,0x23,0x27,0x02,0x84,0x43,0x09,0x4b,0x08,0x5c,0x0b,0x63,0x09,0x43,0x09,0x5c,0x2b,0x54,0x2c,0x5c,0x6d,0x6c,0x8f,0x63,0x8c,0x63,0x8b,0x8c,0x8e,0x7c,0x0c,0x44,0x4b,0xb5,0xd5,0x84,0xf1,0x9d,0x12,0x9d,0x94,0x33,0xc9,0x03,0x66,0x34,0x2a,0x34,0x2b,0x03,0xa6,0x02,0xa4,0x03,0xc6,0x03,0xe6,0x03,0x25,0x0b,0x05,0x02,0xc5,0x03,0x85,0x03,0x05,0x2c,0x49,0x2b,0x07,0x22,0xa5,0x02,0x44,0x02,0x44,0x1a,0x84,0x12,0xa5,0x3b,0xea,0x02,0xe4,0x03,0xa6,0x03,0x45,0x03,0xc7,0x0c,0x08
,0x0c,0x27,0x1c,0x48,0x24,0x69,0x1c,0x08,0x24,0x69,0x0b,0xa6,0x54,0xac,0x7c,0xac,0x4c,0x09,0x1b,0x25,0x74,0x2c,0x2a,0xc6,0x4c,0x2a,0x2b,0xa7,0x2c,0x49,0x23,0xc8,0x2b,0xc9,0x03,0x06,0x13,0x66,0x13,0x46,0x43,0xc9,0x5b,0xeb,0x3b,0xca,0x3c,0x2b,0x4c,0x8c,0x44,0x4c,0x64,0xaf,0x4c,0x4c,0x4c,0x8c,0x3c,0x0a,0x1b,0x67,0x5c,0x6d,0x8d,0x72,0x12,0xe6,0x02,0xa4,0x0a,0xa5,0x7c,0xaf,0x95,0x11,0x54,0x0c,0xa5,0x72,0x6c,0x6e,0x54,0x2b,0x54,0xce,0x5c,0x6d,0x6c,0xcf,0x9d,0x51,0x9d,0x51,0x9d,0x52,0x95,0x10,0x44,0x6c,0x6d,0x0f,0x5c,0x6d,0x74,0xf0,0x7d,0x11,0x5c,0x6d,0x03,0x47,0x4c,0x4c,0x4c,0x6d,0x03,0x45,0x02,0xe5,0x02,0xe5,0x03,0xc7,0x03,0x05,0x23,0xa8,0x1b,0x46,0x0b,0xc6,0x02,0xe4,0x2c,0x29,0x4b,0xaa,0x7c,0x4c,0x33,0x27,0x23,0x06,0x84,0x6c,0x43,0xa9,0x3b,0xca,0x2c,0x09,0x1b,0x87,0x03,0xc6,0x04,0x07,0x0c,0x08
,0x14,0x08,0x4c,0xcd,0x75,0x70,0x7d,0x70,0x65,0x4e,0x0b,0xa6,0x85,0x2f,0x9c,0x6c,0x84,0xee,0x33,0x88,0x94,0xae,0x53,0x49,0x64,0x2b,0x9d,0xb3,0x85,0x91,0x64,0xcf,0x4c,0x6d,0x02,0x84,0x02,0x84,0x02,0xa4,0x22,0xe8,0x43,0x09,0x2b,0x27,0x23,0x48,0x33,0x69,0x23,0x48,0x54,0x8c,0x3b,0xca,0x33,0xc9,0x3b,0xe9,0x03,0x05,0x13,0x46,0x33,0xa9,0x03,0x06,0x03,0x05,0x4c,0x0c,0x8d,0x30,0x8d,0x51,0x7c,0xaf,0x85,0x31,0x95,0x51,0x43,0xea,0x03,0x06,0x03,0x06,0x23,0x68,0x44,0x0c,0x5c,0xce,0x75,0x0f,0x95,0x92,0x2c,0x6a,0x2c,0x4a,0x34,0x4b,0x3c,0x6b,0x4c,0x8d,0x9e,0x13,0x44,0x2b,0x7d,0x90,0x65,0x4f,0x03,0xe6,0x03,0x46,0x0a,0xe5,0x03,0xc6,0x03,0x05,0x4c,0x0a,0x6d,0x2f,0x23,0x87,0x03,0x24,0x24,0x08,0x7c,0xad,0xa4,0x6b,0x64,0x6b,0x54,0x4a,0xac,0xcd,0x7c,0x8d,0x3b,0xc9,0x5c,0xac,0x65,0x4e,0x03,0xe7,0x03,0xe7,0x0c,0x08
,0x0c,0x28,0x13,0xe7,0x0c,0x08,0x0b,0xe8,0x0b,0xe7,0x0b,0xa5,0x44,0x4a,0x54,0x0a,0x23,0x87,0x0b,0x04,0x43,0x49,0x1a,0x66,0x4c,0x2a,0x13,0x45,0x0b,0xc7,0x13,0x66,0x0b,0x25,0x02,0xa5,0x02,0xc4,0x23,0x27,0x32,0xa8,0x3a,0x68,0x3a,0xa7,0x23,0x27,0x02,0xa5,0x02,0xa5,0x03,0x66,0x02,0xc5,0x1b,0x67,0x1b,0x67,0x02,0xe5,0x02,0xc5,0x4b,0xca,0x3b,0x68,0x3b,0xa8,0x53,0xcb,0x7c,0xf0,0x74,0xae,0x64,0x2c,0x7d,0x12,0x6c,0x8e,0x43,0x8a,0x3b,0xab,0x2b,0x29,0x43,0xaa,0x33,0x6a,0x33,0x69,0x64,0xce,0x44,0x8c,0x85,0x92,0x9d,0x52,0xad,0x93,0xad,0xb4,0x9d,0x72,0xad,0x72,0xad,0xb3,0xb6,0x14,0xa6,0x14,0x03,0xe7,0x03,0xa7,0x02,0xe5,0x03,0x46,0x03,0x05,0x13,0x26,0x0b,0xa7,0x02,0xe4,0x03,0x85,0x23,0x68,0x33,0x47,0x43,0x48,0x12,0x85,0x0a,0x84,0x43,0x27,0x22,0xc6,0x3b,0xca,0x13,0xa7,0x0b,0x66,0x03,0xe6,0x03,0xc7,0x0c,0x08
,0x0c,0x28,0x0b,0xe7,0x0c,0x07,0x0c,0x07,0x03,0xc6,0x0b,0xa6,0x4c,0x0a,0x6c,0x0a,0x33,0x47,0x12,0xe5,0x6c,0x2c,0x2a,0xa6,0x4c,0x2a,0x13,0x25,0x0b,0xc7,0x13,0x26,0x0b,0x66,0x02,0xa4,0x02,0xa4,0x33,0x48,0x29,0x85,0x41,0xe6,0x31,0x85,0x54,0x0c,0x2b,0x89,0x43,0xea,0x1b,0x67,0x02,0xc4,0x03,0x05,0x0b,0x05,0x02,0xe4,0x02,0x84,0x8c,0x8e,0x84,0x2b,0x8c,0x4c,0x73,0x89,0x84,0x6d,0x7c,0x2c,0x6b,0xcb,0x84,0xaf,0x6b,0xec,0x6b,0xed,0x74,0x8f,0x63,0xec,0x64,0x2e,0x6c,0x50,0x5b,0xad,0x6c,0x4e,0x75,0x90,0x54,0x8c,0x9d,0x51,0x9d,0x51,0xa5,0x52,0x95,0x72,0x5b,0x4b,0x74,0x4f,0x5b,0xeb,0x5c,0x6d,0x03,0xe7,0x03,0xc6,0x03,0xa6,0x03,0x05,0x03,0x05,0x13,0x26,0x0b,0xa6,0x0b,0x25,0x0b,0x45,0x2b,0x87,0x43,0x69,0x6b,0xea,0x1a,0xc6,0x1b,0x45,0x63,0xea,0x33,0x28,0x3b,0xca,0x13,0xa7,0x13,0x87,0x0b,0xe6,0x04,0x07,0x0c,0x07
,0x0c,0x08,0x5d,0x4d,0x5d,0x2d,0x44,0xeb,0x13,0xe6,0x0b,0xa5,0x8d,0x10,0xac,0xad,0x84,0x6d,0x3b,0x27,0x9c,0x8d,0x63,0xab,0x5c,0x0b,0x85,0x50,0x54,0x4b,0x75,0x70,0x02,0xe5,0x02,0x84,0x02,0xa4,0x2a,0xe7,0x29,0x64,0x6a,0xe8,0x31,0xa4,0x5c,0x0c,0x33,0x89,0x64,0x6d,0x23,0x88,0x03,0x04,0x33,0xe9,0x6c,0xce,0x2c,0x09,0x12,0xc6,0x73,0x6b,0x7b,0xcc,0x7b,0xed,0x63,0x6b,0x74,0x0e,0x6b,0xad,0x63,0x8c,0x6c,0x0f,0x5b,0x8d,0x5b,0x8d,0x6c,0x0f,0x5b,0x8c,0x63,0xad,0x73,0xed,0x63,0x6c,0x43,0x49,0x02,0xa4,0x23,0xa8,0x4c,0x2c,0x6c,0x8f,0x7d,0x31,0x85,0x72,0x94,0xaf,0xad,0xb3,0xb5,0xf5,0x9d,0xb3,0x4c,0xee,0x4c,0xcd,0x55,0x0e,0x03,0x25,0x03,0x05,0x5c,0x8d,0x6d,0x0e,0x7d,0x50,0x44,0x0a,0x24,0x08,0x7c,0x8d,0x9c,0x6c,0x63,0xeb,0x53,0x88,0x9c,0xac,0x84,0xce,0x43,0xea,0x75,0x4f,0x85,0xb0,0x4c,0xcc,0x03,0xe7,0x04,0x28
,0x0c,0x07,0x0c,0x27,0x1c,0x47,0x2c,0x49,0x13,0xe6,0x0b,0xa5,0x4c,0x0b,0x63,0xeb,0x33,0x27,0x0a,0x64,0x6c,0x0c,0x3b,0x49,0x4c,0x4b,0x13,0x45,0x2c,0x09,0x2b,0xc8,0x03,0xa6,0x03,0x05,0x02,0xa4,0x33,0x08,0x21,0x44,0x29,0x03,0x39,0xa4,0x5c,0x2c,0x43,0x89,0x5c,0x4d,0x23,0x88,0x02,0xe5,0x0b,0x05,0x6c,0x8e,0x64,0x2d,0x32,0x27,0x31,0xa5,0x29,0xa5,0x29,0x85,0x31,0xa5,0x29,0xa6,0x29,0xa6,0x29,0xa5,0x29,0xa5,0x29,0xa6,0x29,0xa5,0x29,0xa5,0x29,0xa5,0x31,0xa5,0x31,0xa5,0x31,0xa5,0x31,0xa5,0x53,0x6a,0x74,0xf0,0x33,0xaa,0x23,0xa9,0x54,0x8c,0x75,0x0f,0x64,0x6d,0x64,0x8e,0x4c,0x0c,0x5c,0x8d,0x1b,0x67,0x8d,0x71,0x75,0x30,0x03,0x05,0x03,0x05,0x13,0x26,0x13,0xe7,0x23,0x87,0x1b,0xa7,0x24,0x28,0x33,0x88,0x63,0xc9,0x22,0xa6,0x12,0xa4,0x5b,0xa9,0x33,0x28,0x3b,0xea,0x13,0xa7,0x1b,0xa8,0x1c,0x49,0x04,0x08,0x0c,0x08
,0x0c,0x07,0x03,0xe6,0x03,0xe6,0x03,0xc6,0x03,0xc6,0x03,0xa5,0x44,0x0a,0x43,0x28,0x1a,0xe7,0x02,0x85,0x53,0x8a,0x2b,0x48,0x44,0x6a,0x03,0xa6,0x02,0xe4,0x02,0xe4,0x03,0xa6,0x03,0x25,0x02,0xa4,0x3b,0x28,0x21,0x43,0x5a,0x67,0x31,0xa4,0x84,0x6f,0x95,0x30,0xad,0x72,0x64,0xae,0x02,0xc5,0x02,0xc5,0x6c,0x2d,0x6b,0xed,0x39,0xe6,0x21,0x64,0x29,0x64,0x29,0x85,0x29,0x65,0x29,0x64,0x29,0x85,0x29,0x85,0x29,0x85,0x29,0x85,0x29,0x65,0x29,0x85,0x29,0x85,0x29,0x85,0x21,0x64,0x29,0x64,0x29,0x85,0x63,0x4a,0x6c,0x2e,0x2b,0x88,0x13,0x47,0x4c,0x4b,0x44,0x0b,0x03,0x05,0x03,0x05,0x03,0x05,0x03,0x05,0x02,0xe5,0x6c,0x2d,0x64,0x4d,0x0b,0x05,0x03,0x06,0x0b,0x05,0x03,0xa6,0x02,0xe5,0x03,0x45,0x24,0x49,0x2b,0xa8,0x3b,0x27,0x0a,0x84,0x02,0x84,0x43,0x28,0x1a,0xc6,0x3b,0xca,0x03,0x65,0x03,0x45,0x03,0xc6,0x03,0xe7,0x0c,0x08
,0x0c,0x27,0x55,0x2e,0x5d,0x0d,0x3c,0xab,0x24,0x49,0x03,0xa5,0x85,0x0f,0x94,0x4c,0x7c,0x6d,0x3b,0x48,0x9c,0xaf,0x74,0x2d,0x54,0x2b,0x75,0x70,0x3c,0xab,0x44,0xcc,0x03,0xa6,0x54,0xad,0x5c,0x4c,0x3b,0x28,0x21,0x64,0x5a,0xc9,0x29,0x64,0x8c,0x8f,0x8c,0xae,0xa5,0x10,0x5c,0x0c,0x03,0x05,0x0b,0x05,0x7d,0x11,0x84,0x8f,0x42,0x27,0x29,0x64,0x21,0x64,0x29,0x85,0x29,0x85,0x29,0x85,0x29,0x85,0x29,0x64,0x29,0x65,0x29,0x85,0x29,0x65,0x29,0x64,0x29,0x85,0x29,0x85,0x19,0x03,0x21,0x44,0x29,0xa5,0x7b,0xcc,0x8d,0x33,0x3b,0xeb,0x03,0x05,0x2b,0xa8,0x23,0xa8,0x03,0x26,0x03,0x26,0x03,0x26,0x03,0x05,0x03,0x05,0x7c,0x8f,0x85,0x31,0x0b,0x05,0x03,0x05,0x64,0xad,0x5c,0xed,0x3b,0xea,0x4c,0x8b,0x4c,0xab,0x7c,0x8d,0x94,0x8d,0x5c,0x0b,0x4b,0xa9,0x9c,0x4a,0x7c,0xae,0x43,0xca,0x75,0x4f,0x44,0xac,0x44,0x8b,0x55,0x2e,0x14,0x08
,0x0c,0x27,0x1c,0x28,0x2c,0x4a,0x2c,0x4a,0x14,0x27,0x03,0xa5,0x5c,0x2b,0x7c,0x4c,0x43,0x89,0x12,0xa5,0x8c,0xae,0x5c,0x0c,0x4c,0x6b,0x1b,0xe8,0x34,0x6a,0x3c,0xab,0x03,0x46,0x33,0x88,0x23,0x67,0x43,0x69,0x21,0xc5,0x32,0x27,0x32,0x26,0x95,0x51,0x84,0xaf,0x84,0xf0,0x5c,0x6c,0x1b,0x67,0x3b,0xea,0x84,0xaf,0x7c,0x2d,0x3a,0x06,0x29,0x85,0x31,0xa5,0x39,0xe6,0x3a,0x06,0x3a,0x06,0x39,0xe6,0x39,0xc6,0x29,0x85,0x29,0x85,0x29,0x85,0x29,0x85,0x31,0xc5,0x29,0x85,0x29,0x85,0x29,0x85,0x29,0xa5,0x63,0x49,0x74,0x6f,0x2b,0x89,0x03,0x05,0x03,0x05,0x03,0x05,0x23,0x88,0x23,0xa9,0x03,0x06,0x02,0xe5,0x02,0xe5,0x44,0x0b,0x44,0x2c,0x03,0x06,0x0b,0x06,0x1b,0x88,0x2c,0x29,0x2b,0xc9,0x2b,0xe9,0x3c,0x8b,0x4b,0xa9,0x84,0x4d,0x33,0x27,0x1a,0xe6,0x74,0x0b,0x43,0x89,0x3b,0xca,0x23,0xc8,0x34,0x2a,0x34,0x8a,0x2c,0x8b,0x14,0x08
,0x0c,0x08,0x03,0xc5,0x03,0xe7,0x03,0xc6,0x03,0xc6,0x0b,0xa5,0x3c,0x0a,0x22,0xa6,0x0a,0x85,0x02,0xa5,0x1a,0xa5,0x0a,0x84,0x3c,0x4a,0x03,0xa5,0x03,0xa5,0x03,0x45,0x0a,0xc5,0x02,0xe4,0x02,0xe4,0x2b,0x48,0x43,0x49,0x43,0x49,0x3b,0x68,0x2b,0x88,0x1b,0x26,0x1b,0x46,0x0b,0x25,0x02,0xe5,0x0a,0xe5,0x7c,0xcf,0x8c,0xaf,0x42,0x07,0x29,0x85,0x3a,0x06,0x52,0xa8,0x42,0x47,0x4a,0x47,0x4a,0x47,0x4a,0x47,0x31,0xc5,0x31,0xa5,0x29,0x85,0x42,0x27,0x5a,0xc9,0x52,0x87,0x5a,0xc9,0x29,0x85,0x29,0xa5,0x6b,0x8b,0x7c,0xd0,0x4c,0x2c,0x13,0x67,0x02,0xe5,0x13,0x26,0xb5,0xd4,0xa5,0xb3,0x33,0x89,0x23,0x68,0x03,0x26,0x03,0x65,0x02,0xe5,0x03,0x05,0x03,0x05,0x03,0x05,0x03,0xa7,0x03,0x05,0x03,0x45,0x24,0x28,0x23,0xa8,0x22,0xa5,0x02,0x64,0x02,0x64,0x1a,0xa5,0x0a,0x84,0x3b,0xea,0x03,0x65,0x03,0x45,0x03,0xe6,0x03,0xc6,0x14,0x08
,0x0c,0x07,0x44,0xcb,0x44,0xed,0x34,0x8a,0x1c,0x07,0x03,0xa5,0x7c,0xae,0xa4,0xcd,0x7c,0x4c,0x2a,0xe7,0xa4,0xad,0x84,0xce,0x5c,0x4c,0x64,0xee,0x44,0x6b,0x64,0x8d,0x0a,0xe5,0x03,0x04,0x02,0xe4,0x1b,0x06,0x53,0xeb,0x53,0xec,0x2b,0x88,0x02,0xa4,0x02,0xc4,0x02,0xe5,0x03,0x05,0x02,0xe5,0x0a,0xe5,0x85,0x10,0x8c,0xaf,0x42,0x27,0x29,0xa5,0x4a,0x88,0x52,0xc9,0x4a,0x47,0x52,0x88,0x42,0x27,0x4a,0x47,0x42,0x27,0x4a,0x27,0x29,0x85,0x4a,0x68,0x4a,0x88,0x52,0xc9,0x42,0x27,0x29,0x85,0x29,0xa5,0x6b,0x8b,0x94,0xf1,0x3b,0xca,0x03,0x05,0x03,0x05,0x0b,0x06,0x74,0x4e,0x63,0xcc,0x8c,0xf0,0x8d,0x31,0x54,0x6c,0x0b,0x86,0x03,0x46,0x03,0x05,0x02,0xe5,0x44,0x2b,0x64,0xee,0x4c,0x4b,0x13,0x66,0x24,0x08,0x6c,0x2c,0x9c,0x8c,0x53,0xc9,0x43,0x68,0xac,0x8c,0x74,0x6d,0x3b,0xc9,0x5c,0xcc,0x3c,0x6a,0x34,0x6a,0x3c,0xcc,0x14,0x08
,0x0c,0x27,0x34,0x8b,0x3c,0xab,0x44,0xcb,0x24,0x48,0x03,0xa5,0x6c,0x8d,0x94,0xae,0x74,0x8d,0x1a,0xa5,0x94,0x8d,0x8c,0xaf,0x5c,0x0b,0x3b,0xaa,0x5c,0x8d,0x64,0xad,0x0b,0x05,0x02,0xe4,0x02,0xe4,0x13,0x05,0x54,0x2b,0x53,0xeb,0x23,0x47,0x02,0xc4,0x02,0xe4,0x02,0xe5,0x02,0xe5,0x02,0xe5,0x2b,0x89,0x74,0x4e,0x84,0x2e,0x3a,0x06,0x29,0x85,0x29,0xa5,0x31,0xa5,0x31,0xa5,0x39,0xe6,0x31,0xa5,0x31,0xa5,0x31,0xa5,0x31,0xa5,0x29,0x85,0x31,0xc6,0x39,0xe6,0x39,0xe6,0x29,0x85,0x29,0x85,0x29,0x84,0x63,0x29,0x74,0x4e,0x23,0x68,0x02,0xe5,0x03,0x05,0x13,0x46,0x9d,0x51,0x9d,0x32,0x84,0xb0,0x74,0x8e,0x7d,0x71,0x13,0xa7,0x03,0x66,0x03,0x06,0x02,0xe5,0x33,0xc9,0x44,0x8b,0x44,0x2a,0x23,0xa7,0x24,0x27,0x5c,0x0b,0x9c,0xce,0x43,0x68,0x33,0x27,0x9c,0x8c,0x5c,0x0b,0x3b,0xca,0x34,0x49,0x44,0x8b,0x3c,0xab,0x4c,0xcc,0x14,0x08
,0x0c,0x27,0x03,0xe7,0x03,0xe7,0x03,0xc6,0x03,0xc5,0x0b,0xa5,0x44,0x2a,0x12,0x86,0x0a,0xa5,0x02,0x84,0x12,0x43,0x3b,0x69,0x4b,0xca,0x02,0xa4,0x02,0xe4,0x03,0x05,0x02,0xe4,0x02,0xe4,0x02,0xc4,0x02,0xc4,0x02,0xa4,0x02,0xa4,0x02,0xa4,0x1b,0x07,0x23,0x47,0x0a,0xe6,0x03,0x05,0x02,0xe5,0x0a,0xe5,0x95,0x51,0x94,0xd0,0x42,0x48,0x29,0x85,0x29,0x85,0x29,0x85,0x29,0x85,0x29,0x85,0x29,0x85,0x29,0x85,0x29,0x85,0x29,0x85,0x29,0x85,0x29,0x85,0x29,0x85,0x29,0x85,0x29,0x85,0x21,0x64,0x29,0x64,0x7b,0xec,0x9d,0x72,0x54,0x6d,0x3c,0x2a,0x02,0xc5,0x0b,0x06,0x74,0xcf,0x74,0xef,0x84,0xf0,0x7c,0xf0,0x5c,0xae,0x0b,0x46,0x03,0x45,0x03,0x06,0x02,0xe5,0x03,0x05,0x03,0xa6,0x03,0x04,0x03,0x45,0x24,0x28,0x23,0xc7,0x0a,0x23,0x02,0x43,0x02,0x83,0x0a,0x43,0x0a,0x63,0x3b,0xca,0x03,0x86,0x03,0x46,0x03,0xe6,0x03,0xe7,0x14,0x07
,0x0c,0x07,0x34,0x6b,0x34,0x8b,0x24,0x49,0x1c,0x28,0x03,0xa5,0x6c,0x6c,0x9c,0xcf,0x64,0x2b,0x1a,0xc6,0x74,0x0b,0x74,0x8d,0x54,0x0b,0x43,0xea,0x3b,0xe9,0x34,0x09,0x03,0x04,0x02,0xe4,0x02,0xc4,0x03,0x04,0x03,0x04,0x13,0x47,0x23,0x47,0x84,0xaf,0x94,0xf1,0x23,0x68,0x02,0xa4,0x02,0xe5,0x02,0xe5,0x7c,0x6e,0x7c,0x0d,0x3a,0x07,0x29,0x85,0x29,0x85,0x29,0x85,0x29,0x85,0x29,0x85,0x29,0x85,0x29,0x85,0x29,0x85,0x29,0x85,0x29,0x85,0x29,0x85,0x29,0x85,0x29,0x85,0x29,0x64,0x29,0x85,0x29,0x85,0x63,0x09,0x7c,0x4e,0x2b,0x69,0x03,0x05,0x03,0x25,0x02,0xe5,0x5c,0x2d,0x33,0xca,0x23,0x88,0x5c,0x2c,0x54,0x0b,0x54,0x8d,0x23,0xe9,0x1b,0x68,0x03,0x05,0x33,0xc8,0x3c,0x8c,0x23,0xa8,0x0b,0x66,0x1c,0x08,0x5c,0x0a,0x9c,0xee,0x43,0x89,0x33,0x27,0x94,0xee,0x64,0x0c,0x3b,0xc9,0x44,0x6a,0x44,0x4a,0x2c,0x69,0x04,0x06,0x14,0x07
,0x04,0x07,0x4c,0xec,0x4c,0xcc,0x5d,0x2e,0x34,0xaa,0x03,0xa5,0x7c,0xce,0x9c,0x8e,0x7c,0xae,0x1a,0xc6,0x84,0x2c,0x7c,0xae,0x5c,0x2c,0x64,0xae,0x7d,0x50,0x64,0xee,0x03,0x05,0x02,0xe4,0x02,0xe4,0x03,0x24,0x0b,0x04,0x64,0x4d,0x8c,0xd0,0x63,0xac,0x4b,0x2a,0x2b,0x68,0x02,0xe4,0x1b,0x67,0x33,0xea,0x8d,0x11,0x94,0xd0,0x42,0x27,0x29,0x85,0x29,0x85,0x39,0xe6,0x31,0xe6,0x31,0xe6,0x31,0xe6,0x42,0x27,0x3a,0x07,0x3a,0x07,0x42,0x48,0x31,0xe6,0x31,0xe6,0x3a,0x27,0x29,0x85,0x29,0x65,0x29,0x85,0x73,0xac,0x9c,0xf0,0x33,0xca,0x03,0x25,0x03,0x25,0x0b,0x05,0x54,0x4d,0x2b,0xca,0x3b,0xea,0x7c,0x8e,0x6c,0x0c,0xa5,0xd4,0x7d,0x30,0x6d,0x10,0x0b,0x26,0x44,0x2b,0x5d,0x0e,0x5c,0x6c,0x23,0xc7,0x24,0x08,0x6c,0x2c,0x9c,0xad,0x54,0x0a,0x43,0x67,0x9c,0xcd,0x74,0x8e,0x3b,0xea,0x4c,0x8b,0x6d,0x2e,0x4d,0x0d,0x04,0x07,0x14,0x28
,0x0c,0x07,0x03,0xc6,0x03,0xe6,0x03,0xc6,0x03,0xc5,0x03,0xa5,0x44,0x0a,0x22,0xc6,0x12,0xc6,0x02,0x64,0x12,0x44,0x33,0x48,0x54,0x2b,0x03,0x05,0x03,0x05,0x02,0xe4,0x03,0x04,0x03,0x04,0x03,0xa5,0x02,0xe4,0x02,0xe5,0x53,0x8a,0x6b,0xec,0x9d,0x11,0x7c,0xb0,0x2b,0x88,0x03,0x05,0x02,0xe5,0x0a,0xc5,0x84,0xd0,0x84,0x6e,0x3a,0x27,0x29,0x85,0x29,0x85,0x31,0xe6,0x31,0xe6,0x42,0x27,0x3a,0x07,0x39,0xe6,0x31,0xe6,0x42,0x68,0x42,0x48,0x39,0xe6,0x31,0xc6,0x3a,0x27,0x29,0x85,0x29,0x85,0x29,0x85,0x63,0x4a,0x94,0xaf,0x4c,0x0b,0x1b,0x67,0x03,0x25,0x03,0x05,0x4c,0x6c,0x1b,0x67,0x0b,0x26,0x2b,0xc9,0x2b,0xe9,0x1b,0xa8,0x03,0x25,0x02,0xe5,0x03,0x25,0x02,0xe5,0x03,0xc6,0x03,0x05,0x03,0x45,0x24,0x28,0x23,0x89,0x22,0xa5,0x02,0x64,0x02,0x64,0x1a,0xa5,0x12,0x85,0x33,0xea,0x03,0x66,0x03,0x45,0x03,0xc6,0x03,0xe6,0x14,0x07
,0x04,0x07,0x24,0x49,0x1c,0x48,0x1c,0x29,0x0c,0x07,0x03,0xa5,0x5c,0x2b,0x84,0x4c,0x4b,0x8a,0x0a,0x64,0x5b,0x8a,0x43,0x49,0x5b,0xeb,0x33,0xc8,0x1b,0x67,0x23,0x67,0x0a,0xe4,0x03,0xa5,0x03,0x25,0x02,0xa4,0x02,0xc5,0x6c,0x8d,0x7c,0xaf,0x8d,0x0f,0x74,0x8e,0x2b,0xa8,0x02,0xe5,0x03,0x05,0x03,0x05,0x6c,0x4d,0x84,0x4e,0x3a,0x07,0x29,0xa5,0x29,0x85,0x31,0xa5,0x29,0xa5,0x39,0xe6,0x31,0xc6,0x31,0xa5,0x31,0xe6,0x31,0xe6,0x31,0xc6,0x31,0xe6,0x31,0xe6,0x39,0xe6,0x29,0x85,0x29,0x85,0x29,0x85,0x63,0x4a,0x8c,0x4e,0x2b,0x68,0x03,0x05,0x03,0x25,0x03,0x25,0x03,0x25,0x03,0x25,0x03,0x05,0x03,0x05,0x03,0x25,0x03,0x45,0x03,0x25,0x03,0x05,0x03,0x25,0x2b,0xa8,0x34,0x49,0x23,0xa8,0x0b,0x66,0x24,0x08,0x4b,0xca,0x8c,0x6c,0x33,0x07,0x22,0xe6,0x84,0x4b,0x4b,0xa9,0x3b,0xca,0x2c,0x09,0x2c,0x09,0x1c,0x49,0x03,0xe6,0x14,0x08
,0x04,0x27,0x55,0x0d,0x6d,0x4e,0x65,0x2e,0x34,0x69,0x0b,0xa5,0x8d,0x0f,0x9c,0x4c,0x84,0xae,0x12,0xa5,0x84,0x2c,0x6c,0x2c,0x64,0x2c,0x6c,0xce,0x8d,0x91,0x95,0xb2,0x03,0x05,0x03,0x25,0x02,0xe4,0x02,0xc4,0x2b,0xa8,0x8d,0x30,0x95,0x92,0x85,0x70,0x7c,0xae,0x54,0x4c,0x02,0xe5,0x03,0x05,0x1b,0x67,0x8d,0x31,0x94,0xb0,0x42,0x47,0x29,0x85,0x29,0x85,0x29,0x85,0x29,0x85,0x29,0x85,0x29,0x85,0x29,0x85,0x29,0x85,0x29,0x85,0x29,0x85,0x29,0x85,0x29,0x85,0x29,0x85,0x29,0x85,0x29,0x85,0x29,0xa5,0x73,0xcc,0x9d,0x11,0x3c,0x0a,0x03,0x26,0x03,0x25,0x03,0x25,0x03,0x25,0x03,0x05,0x0b,0x25,0x02,0xa4,0x02,0xe5,0x03,0x45,0x03,0x25,0x03,0x06,0x03,0x05,0x5c,0x8c,0x6d,0x0e,0x43,0xea,0x1b,0xa7,0x24,0x08,0x7c,0x8d,0xa4,0x6b,0x64,0x0b,0x4b,0xa9,0x94,0x2b,0x84,0x8e,0x43,0xca,0x64,0xed,0x65,0x2e,0x55,0x2d,0x04,0x07,0x14,0x08
,0x04,0x27,0x04,0x07,0x04,0x07,0x0b,0xe7,0x0b,0xc6,0x03,0xa5,0x44,0x0a,0x4b,0x8a,0x23,0x67,0x02,0x84,0x22,0xc6,0x22,0xc7,0x54,0x0b,0x0b,0x05,0x0b,0x05,0x0b,0x05,0x02,0xa4,0x02,0xc5,0x02,0xc5,0x03,0x04,0x03,0x05,0x13,0x26,0x0a,0xe5,0x0b,0x05,0x13,0x26,0x0b,0x06,0x02,0xe5,0x03,0x05,0x1b,0x47,0x6c,0x0d,0x73,0xcc,0x3a,0x06,0x29,0xa5,0x29,0x85,0x29,0x85,0x29,0x85,0x29,0x85,0x29,0x85,0x29,0xa5,0x29,0x85,0x29,0x85,0x29,0x85,0x29,0x85,0x29,0x85,0x29,0x85,0x29,0x85,0x29,0x85,0x29,0xa5,0x5a,0xe9,0x7c,0x2d,0x43,0xca,0x33,0xea,0x03,0x25,0x03,0x05,0x02,0xe5,0x02,0xe5,0x02,0xe5,0x02,0xe5,0x03,0x04,0x03,0x45,0x03,0x05,0x03,0x05,0x03,0x05,0x02,0xe5,0x0b,0xc7,0x13,0x26,0x03,0x66,0x24,0x29,0x2b,0x88,0x3b,0x47,0x12,0x65,0x0a,0x84,0x3b,0x67,0x1a,0xc6,0x3b,0xea,0x0b,0x85,0x13,0x87,0x14,0x07,0x03,0xe7,0x14,0x08
,0x04,0x07,0x0b,0xe7,0x0b,0xe7,0x0b,0xe7,0x0b,0xc6,0x03,0xa6,0x4c,0x0b,0x63,0xeb,0x33,0x27,0x0a,0xa5,0x64,0x0c,0x43,0x49,0x54,0x2b,0x13,0x26,0x0b,0x05,0x13,0x25,0x03,0x04,0x02,0xe5,0x03,0x04,0x03,0x04,0x02,0xe5,0x03,0x04,0x03,0x04,0x03,0x04,0x03,0x04,0x02,0xe4,0x03,0x04,0x0b,0x05,0x0b,0x06,0x85,0x10,0x8c,0xaf,0x42,0x68,0x29,0x85,0x29,0x85,0x29,0x85,0x29,0x85,0x29,0x85,0x29,0x85,0x29,0x85,0x29,0x85,0x29,0x85,0x29,0x85,0x29,0x85,0x29,0x85,0x29,0x85,0x29,0x85,0x29,0x85,0x29,0xa5,0x73,0xcc,0x9d,0x11,0x3b,0xca,0x03,0x05,0x03,0x05,0x02,0xe5,0x02,0xe5,0x02,0xe5,0x02,0xe4,0x03,0x05,0x02,0xe5,0x03,0x25,0x03,0x05,0x02,0xe5,0x03,0x05,0x13,0x26,0x13,0xc7,0x13,0x46,0x03,0x65,0x24,0x28,0x3b,0xa9,0x6b,0xeb,0x22,0xe6,0x12,0xa5,0x64,0x0b,0x3b,0x49,0x3b,0xca,0x13,0xa6,0x13,0x86,0x0b,0xe6,0x03,0xe7,0x0c,0x08
,0x04,0x07,0x65,0x2d,0x65,0x4e,0x44,0xcc,0x2c,0x8a,0x03,0xc6,0x95,0x30,0xa4,0x6b,0x84,0xae,0x2b,0x48,0x8c,0x2d,0x7c,0x8e,0x64,0x2b,0x7d,0x30,0x8d,0xb2,0x8d,0x71,0x0a,0xe5,0x03,0x05,0x03,0x04,0x02,0xe5,0x02,0xe5,0x02,0xe5,0x02,0xe4,0x02,0xe4,0x02,0xe4,0x0b,0x04,0x03,0x04,0x03,0x05,0x0a,0xc5,0x6c,0x4e,0x7c,0x0d,0x3a,0x27,0x29,0x85,0x29,0x85,0x29,0x85,0x29,0x85,0x29,0x85,0x29,0x85,0x29,0x85,0x29,0x85,0x29,0x85,0x29,0x85,0x29,0x85,0x29,0x85,0x29,0x85,0x29,0x85,0x29,0x85,0x29,0xa5,0x63,0x4a,0x7c,0x4d,0x2b,0x68,0x02,0xe5,0x02,0xe5,0x0a,0xe5,0x02,0xe5,0x02,0xe5,0x03,0x05,0x02,0xe5,0x03,0x45,0x03,0x05,0x02,0xe5,0x02,0xc5,0x03,0x05,0x64,0x8c,0x6d,0x2f,0x54,0x6c,0x2b,0xe8,0x1c,0x07,0x7c,0x6c,0x9c,0x6b,0x64,0x2b,0x53,0xa9,0x9c,0x6c,0x7c,0xce,0x43,0xca,0x75,0x4e,0x65,0x0e,0x3c,0xab,0x03,0xe7,0x0c,0x08
,0x04,0x07,0x13,0xe7,0x13,0xe7,0x1c,0x28,0x03,0xc5,0x03,0xa5,0x4c,0x0b,0x6c,0x0b,0x3b,0xa9,0x0a,0x85,0x53,0xeb,0x2b,0x28,0x4c,0x0b,0x13,0x46,0x1b,0x67,0x2b,0xc9,0x0a,0xe5,0x03,0x05,0x02,0xe4,0x02,0xe5,0x02,0xc4,0x02,0xc4,0x0a,0xa4,0x33,0x48,0x3b,0xa9,0x13,0x05,0x02,0xc4,0x23,0x47,0x33,0xa9,0x5c,0x6d,0x53,0xcb,0x32,0x25,0x31,0xc5,0x31,0xa6,0x31,0xa5,0x31,0xa5,0x31,0xa5,0x31,0xa5,0x31,0xc6,0x31,0xc6,0x31,0xa6,0x31,0xa6,0x31,0xa6,0x31,0xc6,0x31,0xc6,0x29,0xa6,0x29,0xa6,0x29,0xc6,0x5b,0x8a,0x5c,0x4d,0x1b,0x68,0x02,0xc4,0x02,0xe5,0x02,0xc5,0x02,0xa4,0x02,0xa4,0x02,0xa4,0x03,0x25,0x03,0x24,0x03,0x65,0x02,0xe5,0x0a,0xe5,0x0b,0x05,0x13,0x26,0x24,0x08,0x23,0x88,0x0b,0x66,0x24,0x08,0x3b,0xa9,0x63,0xeb,0x1a,0xc6,0x12,0xa5,0x5b,0xaa,0x33,0x48,0x3b,0xea,0x0b,0xa6,0x24,0x09,0x1c,0x8a,0x03,0xe7,0x14,0x08
,0x0c,0x07,0x03,0xc6,0x03,0xe6,0x03,0xc6,0x03,0xc5,0x03,0xa5,0x43,0xe9,0x4b,0x68,0x1a,0xa5,0x02,0x84,0x3b,0x48,0x22,0xc6,0x4b,0xeb,0x02,0xe5,0x02,0xe5,0x02,0xe5,0x02,0xe5,0x0a,0xe5,0x02,0xe5,0x02,0xc4,0x02,0xc4,0x13,0x06,0x1a,0x64,0x3b,0x07,0x3b,0x27,0x22,0xc5,0x1a,0xc5,0x0a,0xc3,0x23,0x27,0x4c,0x2c,0x0b,0x66,0x23,0x06,0x73,0xcc,0x73,0xac,0x7b,0xcd,0x63,0x6b,0x73,0xed,0x6b,0xcd,0x5b,0x6c,0x74,0x0e,0x63,0xad,0x5b,0x8c,0x6c,0x0e,0x63,0x8c,0x63,0x8c,0x73,0xcd,0x6b,0x6b,0x43,0x0a,0x1a,0xa5,0x12,0xa5,0x23,0x48,0x02,0xa4,0x02,0x84,0x02,0xa4,0x03,0x25,0x03,0x25,0x13,0x67,0x13,0x66,0x03,0x86,0x03,0xa6,0x02,0xe5,0x03,0x87,0x02,0xe5,0x02,0xc4,0x0b,0x87,0x02,0xe5,0x03,0x45,0x1c,0x28,0x2b,0xa8,0x43,0x48,0x12,0x85,0x0a,0x85,0x3b,0x67,0x1a,0xe5,0x3b,0xea,0x0b,0x66,0x03,0x45,0x03,0xc7,0x03,0xc6,0x0c,0x08
,0x0c,0x07,0x55,0x0d,0x54,0xed,0x4c,0xec,0x1c,0x08,0x0b,0xa5,0x84,0xee,0xa4,0x8c,0x7c,0x8d,0x33,0x28,0xa5,0x32,0x74,0x8e,0x5c,0x0c,0x85,0x50,0x4c,0x2b,0x6c,0xef,0x02,0xe5,0x02,0xe5,0x02,0xe4,0x02,0xe4,0x12,0xe6,0xa5,0x51,0xd5,0x8c,0xd5,0x8b,0xd5,0x6b,0xbc,0xcc,0x95,0x11,0x43,0xe9,0x64,0x4c,0x84,0xaf,0x1b,0xc8,0x02,0xe5,0x74,0x2e,0x6c,0x0c,0x74,0x0d,0x5b,0x8c,0x6c,0x2f,0x5c,0x0d,0x4b,0xac,0x6c,0x6f,0x4b,0xac,0x53,0xcc,0x6c,0x4f,0x5b,0xac,0x63,0xec,0x6c,0x2e,0x63,0x8a,0x5c,0x2c,0x03,0x05,0x74,0xef,0x95,0x71,0x44,0x2b,0x5c,0xad,0x34,0x2a,0x03,0x05,0x02,0xc4,0x54,0x2b,0x7d,0x30,0x34,0x6b,0x03,0x66,0x02,0xc4,0x03,0x86,0x03,0x05,0x54,0x6c,0x75,0x50,0x7d,0x30,0x33,0xe9,0x23,0xe8,0x7c,0x6c,0xa4,0x6b,0x64,0x2b,0x4b,0x89,0x94,0x4c,0x7c,0x8d,0x43,0xea,0x6d,0x4e,0x85,0x90,0x6d,0x6f,0x03,0xc7,0x0b,0xe7
,0x0c,0x27,0x1c,0x48,0x24,0x69,0x24,0x6a,0x14,0x08,0x03,0xa5,0x5c,0x4b,0x8c,0x8d,0x5c,0x2b,0x12,0xa5,0x74,0x2d,0x2b,0x08,0x4b,0xeb,0x23,0x47,0x3b,0xea,0x33,0xea,0x02,0xe5,0x02,0xe5,0x02,0xe4,0x02,0xc4,0x1a,0xe5,0xbd,0xb3,0xed,0x8a,0xe5,0x29,0xe5,0x2a,0xc4,0x4a,0x84,0xaf,0x75,0x0f,0x64,0x2c,0x8c,0xae,0x23,0x47,0x02,0xa4,0x33,0x49,0x33,0xaa,0x43,0xca,0x2b,0x49,0x3b,0xca,0x3b,0xa9,0x23,0x49,0x33,0xa9,0x23,0x28,0x23,0x29,0x33,0x6a,0x33,0x28,0x3b,0xaa,0x33,0x49,0x2b,0x48,0x23,0x68,0x03,0x25,0x6c,0x4c,0x84,0x6e,0x23,0x87,0x1b,0x47,0x13,0x46,0x03,0x66,0x4b,0xea,0x6c,0x0c,0x7c,0x4e,0x3b,0x8a,0x02,0xa5,0x03,0x45,0x03,0x66,0x03,0x05,0x1b,0x67,0x2c,0x0a,0x44,0x8b,0x1b,0xc8,0x23,0xe7,0x4b,0xca,0x84,0x6d,0x33,0x27,0x22,0xe6,0x74,0x4c,0x4b,0x8a,0x3b,0xea,0x1b,0xc7,0x44,0x6a,0x2c,0x69,0x03,0xe7,0x0c,0x08
,0x0c,0x07,0x03,0xe6,0x03,0xe6,0x03,0xe6,0x03,0xc5,0x0b,0xa5,0x3c,0x0a,0x22,0xa5,0x0a,0x84,0x02,0x84,0x1a,0xc5,0x0a,0x85,0x4c,0x0b,0x02,0xc4,0x03,0x05,0x02,0xe5,0x02,0xe5,0x0a,0xe5,0x02,0xe5,0x02,0xe4,0x12,0xc5,0x74,0xad,0x94,0x6a,0x94,0x49,0x8c,0x28,0x7b,0xa9,0x64,0x4c,0x2c,0x08,0x33,0xe9,0x5c,0x0c,0x33,0x88,0x54,0x2c,0x0b,0x05,0x03,0x05,0x1b,0x67,0x13,0x26,0x03,0x05,0x23,0x88,0x1b,0x68,0x02,0xe5,0x13,0x06,0x1b,0x26,0x02,0xc4,0x1b,0x47,0x33,0xc9,0x02,0xa5,0x23,0x87,0x3c,0x29,0x1b,0x46,0x54,0x0b,0x6c,0x4c,0x03,0x24,0x23,0x88,0x33,0xc9,0x23,0xc8,0x4b,0xca,0x63,0xcc,0x6b,0xec,0x3b,0x89,0x03,0x46,0x03,0x65,0x02,0xc5,0x02,0xe5,0x02,0xc5,0x03,0x65,0x03,0xa6,0x03,0x25,0x24,0x28,0x2b,0xa8,0x22,0xa5,0x02,0x63,0x02,0x64,0x22,0xa5,0x12,0x64,0x43,0xca,0x03,0x66,0x03,0x45,0x03,0xe6,0x03,0xe7,0x0c,0x07
,0x04,0x27,0x4c,0xac,0x65,0x2e,0x3c,0xcb,0x0b,0xe6,0x0b,0xa5,0x7c,0xae,0x9c,0x8d,0x74,0x6c,0x1a,0xc6,0x94,0xaf,0x6c,0x4d,0x5c,0x2b,0x74,0xee,0x7d,0x30,0x64,0xee,0x02,0xe5,0x02,0xe5,0x02,0xe5,0x2b,0x68,0x3b,0xea,0x33,0xa9,0x3b,0x27,0x3a,0x65,0x2a,0x04,0x4b,0x29,0x2b,0x47,0x5c,0xad,0x43,0xeb,0x0a,0xa4,0x2b,0x68,0x44,0x0b,0x03,0x05,0x0a,0xe5,0x03,0x05,0x03,0x05,0x2b,0xc8,0x2b,0xa9,0x3c,0x0b,0x9d,0x52,0x5b,0xac,0x8d,0x11,0x44,0x0b,0x0a,0xe5,0x0b,0x05,0x0a,0xe5,0x5c,0x6d,0x64,0x8d,0x74,0x8d,0x33,0x46,0x33,0x46,0x23,0xa8,0x3b,0xaa,0x5c,0x4d,0x2b,0x68,0x0a,0x84,0x0a,0xa5,0x0b,0x46,0x03,0x66,0x03,0x46,0x02,0xc4,0x02,0xc4,0x6c,0xee,0x4c,0x4b,0x5c,0xcd,0x44,0x6a,0x5c,0xcb,0x64,0xed,0x74,0x6c,0xa4,0xad,0x5c,0x0a,0x43,0x68,0x9c,0xad,0x7c,0xcf,0x4c,0x4b,0x44,0x8a,0x54,0xac,0x44,0xcb,0x24,0x69,0x0c,0x08
,0x0c,0x08,0x34,0x6b,0x44,0xac,0x44,0xec,0x14,0x07,0x0b,0xa6,0x6c,0x6d,0x9c,0xae,0x6c,0x8d,0x12,0x85,0x74,0x2c,0x43,0x89,0x54,0x2b,0x44,0x09,0x75,0x2f,0x5c,0xad,0x03,0x04,0x03,0x05,0x03,0x04,0x23,0x67,0x43,0xca,0x3b,0x68,0x64,0x0c,0x7b,0xaa,0x62,0xc7,0x74,0x0d,0x3a,0xe7,0x7c,0x2d,0x63,0xcb,0x02,0x63,0x1b,0x47,0x33,0xa8,0x0a,0xe5,0x7d,0x30,0x0b,0x26,0x03,0x25,0x54,0x8d,0x5c,0xae,0x64,0xce,0x7c,0x6e,0x4a,0xe8,0x84,0x8f,0x4c,0x0c,0x0a,0xe5,0x03,0x06,0x3c,0x6b,0xad,0xb3,0xc4,0x8b,0xe5,0x6c,0xe5,0x4b,0xd5,0x8c,0x8c,0xae,0x7c,0x6e,0x6c,0x0c,0x7c,0xaf,0x8c,0xf0,0x84,0x8e,0x8c,0xef,0x44,0x2b,0x3b,0xa8,0x33,0x68,0x03,0x65,0x54,0xed,0x54,0x8c,0x54,0xcd,0x3c,0x6a,0x3c,0x69,0x5c,0xed,0x5c,0x0b,0x94,0x8d,0x43,0xa9,0x33,0x07,0x9c,0xcf,0x6c,0x2c,0x44,0x2a,0x44,0x6a,0x4c,0xcc,0x4c,0xcb,0x24,0x69,0x0c,0x28
,0x0c,0x07,0x03,0xa6,0x03,0xe7,0x03,0xc6,0x03,0xc6,0x03,0xa6,0x3c,0x4a,0x12,0xc4,0x0a,0xc4,0x02,0x64,0x0a,0x43,0x0a,0x64,0x4c,0x2b,0x03,0x04,0x03,0x24,0x03,0x04,0x03,0x25,0x03,0x25,0x03,0x05,0x02,0xa4,0x0a,0xa5,0x33,0x48,0x53,0xab,0x4b,0x08,0x4b,0x28,0x6b,0xec,0x43,0x29,0x52,0xe8,0x4b,0x49,0x0a,0x84,0x13,0x05,0x2b,0xa8,0x33,0xa9,0x85,0x50,0x13,0x46,0x03,0x25,0x03,0x05,0x03,0x25,0x0b,0x46,0x2b,0x88,0x7d,0x30,0x6c,0xce,0x4c,0xcd,0x6d,0x50,0x5c,0xee,0x65,0x2e,0xad,0xb3,0xcc,0x49,0xe5,0x6a,0xe5,0x6a,0xe5,0x8b,0x8c,0x6d,0x64,0x0c,0x3a,0xc8,0x4b,0x29,0x5b,0xeb,0x42,0xc7,0x63,0xcb,0x43,0xaa,0x43,0xca,0x23,0xc9,0x03,0xc6,0x03,0xc7,0x03,0x46,0x03,0x66,0x03,0xa6,0x03,0x45,0x24,0x29,0x2b,0xc9,0x12,0x44,0x02,0x43,0x02,0x63,0x0a,0x24,0x0a,0xc4,0x3c,0xab,0x03,0xc5,0x03,0xc6,0x03,0xe6,0x03,0xe6,0x14,0x28
,0x0c,0x27,0x2c,0x69,0x3c,0xab,0x2c,0x4a,0x3c,0xcb,0x03,0xc6,0x64,0xcd,0x9c,0xee,0x6c,0xad,0x12,0xc5,0x84,0x8e,0x53,0xcb,0x54,0x2b,0x4c,0x6c,0x54,0x4c,0x44,0x2a,0x03,0x05,0x44,0x0a,0x54,0x2c,0x54,0x6c,0x2b,0xe9,0x8c,0x8f,0x4a,0xe8,0x7c,0x4e,0x6b,0xab,0x63,0x69,0x6b,0xec,0x52,0xe9,0x53,0x6a,0x02,0x64,0x2b,0x68,0x54,0x4d,0x7d,0x31,0x64,0xcf,0x0b,0x05,0x5c,0xce,0x54,0xaf,0x3c,0x6c,0x13,0x46,0x95,0x71,0xad,0x91,0xad,0xb2,0x75,0x4f,0x14,0x08,0x14,0x08,0x24,0x29,0x6c,0xcd,0x74,0x0a,0x7b,0xe9,0x7b,0xc8,0x73,0xe8,0x3b,0x28,0x12,0xe6,0x53,0xcb,0x32,0xc7,0x01,0xe3,0x02,0x03,0x02,0x23,0x02,0x64,0x03,0x05,0x03,0xc7,0x03,0xc6,0x03,0xe7,0x34,0x2a,0x4c,0xac,0x3c,0x8b,0x13,0x87,0x2c,0x29,0x64,0x2b,0xa4,0xcd,0x4b,0xaa,0x33,0x27,0x94,0xad,0x64,0x0c,0x3c,0x8a,0x3c,0x8a,0x3c,0xaa,0x34,0x8a,0x03,0xe6,0x0c,0x07
,0x0c,0x27,0x44,0xcb,0x6d,0x4f,0x65,0x2f,0x65,0x4e,0x0b,0xa6,0x7d,0x2f,0x9c,0xad,0x85,0x0f,0x12,0xe6,0x74,0x0c,0x53,0xeb,0x5c,0x2c,0x54,0x6d,0x85,0x92,0x64,0xad,0x03,0x05,0x1b,0x67,0x44,0x0c,0x95,0x32,0x5c,0x2c,0x74,0x2c,0x8c,0xaf,0x95,0x10,0x84,0x8e,0x7c,0x4e,0x84,0x6f,0x84,0x6f,0x74,0x2c,0x43,0x69,0x85,0x10,0x8d,0x52,0x64,0x6d,0x0b,0x26,0x43,0xea,0x3b,0xaa,0x4c,0x0c,0x3c,0x2c,0x13,0x47,0x85,0x10,0xa5,0x71,0x95,0x31,0x64,0x8e,0x03,0xe7,0x03,0xc7,0x03,0xe6,0x03,0xa6,0x0a,0xe5,0x42,0xe8,0x32,0x85,0x32,0x85,0x4b,0x68,0x4b,0x8a,0x64,0x0c,0x63,0xcb,0x4b,0x49,0x4b,0x49,0x4b,0x8a,0x4b,0x69,0x64,0x8d,0x64,0xef,0x33,0xea,0x03,0xe7,0x44,0xac,0x65,0x2e,0x7d,0x6f,0x34,0x6b,0x24,0x08,0x74,0x4c,0xa4,0xad,0x53,0xca,0x3b,0x68,0x94,0x6c,0x7c,0x6e,0x44,0x8b,0x3c,0xab,0x6d,0x8f,0x2c,0x6a,0x04,0x07,0x0c,0x28
,0x0c,0x07,0x03,0xe6,0x03,0xe6,0x03,0xc7,0x03,0xc6,0x0b,0xa6,0x3c,0x4a,0x33,0x88,0x13,0x26,0x02,0x84,0x12,0x64,0x0a,0x85,0x4c,0x0b,0x02,0xe5,0x03,0x05,0x0b,0x25,0x03,0x05,0x03,0x05,0x33,0x89,0xce,0x16,0xb5,0x51,0x9c,0xaf,0x5a,0xe9,0x4a,0x48,0x19,0x65,0x22,0x08,0x3a,0x28,0x42,0x08,0x5a,0xe9,0x73,0xcd,0xb5,0xb4,0xad,0x12,0x5c,0x2c,0x1b,0x67,0xad,0x92,0x63,0x8c,0x94,0xf1,0x6c,0xae,0x1b,0x26,0x2b,0x06,0x22,0x45,0x2a,0xa5,0x43,0xc9,0x44,0xac,0x14,0x08,0x03,0xe6,0x03,0xc6,0x13,0x47,0xad,0x52,0xad,0x30,0x8c,0x6e,0x6b,0x6a,0x52,0x88,0x3a,0x06,0x42,0x47,0x31,0xe6,0x42,0x47,0x52,0xe9,0x84,0x2d,0xce,0x36,0xbd,0xf5,0x7c,0xcf,0x03,0xc6,0x03,0x46,0x03,0x66,0x03,0xa6,0x03,0x46,0x24,0x28,0x2b,0xa8,0x1a,0x85,0x02,0x63,0x02,0x63,0x1a,0x65,0x12,0xe5,0x3c,0xab,0x03,0xc6,0x03,0xa6,0x03,0xe7,0x04,0x07,0x0c,0x28
,0x0c,0x27,0x24,0x69,0x2c,0x69,0x24,0x49,0x0b,0xe6,0x03,0xc6,0x5c,0x2b,0x84,0x4c,0x54,0x0a,0x0a,0x64,0x64,0x0c,0x3b,0x69,0x54,0x0b,0x33,0xc8,0x33,0xc9,0x34,0x09,0x03,0x05,0x03,0x05,0x23,0x48,0x95,0x93,0x7c,0xae,0x74,0x2d,0x52,0xaa,0x19,0x87,0x0b,0x11,0x0b,0xb4,0x0b,0x93,0x0a,0x0a,0x3a,0x07,0x5b,0x6b,0x63,0xec,0x74,0x6e,0x3b,0xca,0x13,0x47,0x64,0x6d,0x4b,0xca,0x6c,0x4d,0x74,0xcf,0x6c,0xee,0x42,0x88,0x3a,0x47,0x42,0x68,0x53,0x4a,0x44,0x4b,0x4c,0xcd,0x5d,0x0e,0x0b,0xe7,0x13,0x47,0x8d,0x52,0x6c,0x2d,0x63,0xcb,0x5a,0xe9,0x21,0x02,0x19,0x02,0x29,0x64,0x21,0x44,0x10,0xc1,0x39,0xe6,0x73,0xcc,0x7c,0x8e,0x84,0xef,0x54,0x2c,0x03,0xc7,0x2b,0xe9,0x34,0x29,0x24,0x08,0x13,0x86,0x24,0x08,0x53,0xca,0x84,0x8c,0x33,0x27,0x22,0xe5,0x84,0x4c,0x4b,0x89,0x3c,0xaa,0x2c,0x49,0x2c,0x6a,0x1c,0x49,0x04,0x07,0x04,0x28
,0x0c,0x07,0x4d,0x0d,0x6d,0x4f,0x3c,0xaa,0x0c,0x06,0x03,0xa6,0x85,0x10,0x84,0x0c,0x7c,0x8d,0x1a,0xa5,0x84,0xae,0x64,0x2c,0x64,0x4c,0x6c,0xee,0x6c,0xef,0x95,0xb2,0x02,0xe5,0x03,0x05,0x02,0xc4,0x02,0xe5,0x02,0x64,0x3b,0x28,0x31,0xe6,0x02,0xf1,0x03,0x76,0x03,0x56,0x03,0x55,0x03,0x95,0x09,0x87,0x2a,0x45,0x02,0x43,0x02,0xc4,0x02,0xe4,0x03,0x05,0x0b,0x05,0x4c,0x2b,0x33,0xea,0x02,0xc4,0x2b,0xa9,0x3a,0x27,0x3a,0x27,0x3a,0x28,0x4a,0x89,0x1a,0xe6,0x3c,0xab,0x85,0x70,0x44,0x8b,0x03,0x86,0x03,0x87,0x03,0x26,0x22,0xe6,0x31,0xe6,0x18,0xe2,0x18,0xe2,0x10,0xa2,0x10,0xa2,0x19,0x03,0x18,0xe2,0x53,0x6a,0x0b,0x05,0x03,0x86,0x03,0xc7,0x03,0xe7,0x54,0xcd,0x85,0x71,0x7d,0x71,0x3c,0x8b,0x24,0x28,0x7c,0x6d,0x94,0x4b,0x6c,0x6d,0x4b,0xa9,0xac,0x8b,0x7c,0x8e,0x44,0x8b,0x5c,0xed,0x85,0xb1,0x55,0x0e,0x03,0xe7,0x0c,0x28
,0x0c,0x08,0x03,0xc7,0x0c,0x07,0x03,0xe7,0x03,0xc6,0x03,0xa5,0x3c,0x0a,0x43,0x48,0x1a,0xa5,0x02,0x64,0x22,0xc6,0x0a,0x85,0x4c,0x2b,0x0a,0xc5,0x13,0x26,0x13,0x46,0x02,0xe5,0x54,0x4b,0x2b,0x6a,0x03,0x05,0x02,0xc5,0x43,0x69,0x32,0x28,0x03,0x95,0x03,0x55,0x03,0x55,0x03,0x55,0x03,0x76,0x0a,0x6d,0x32,0xc7,0x02,0x84,0x13,0x06,0x2b,0xa9,0x33,0xea,0x64,0x4c,0x74,0xae,0x7c,0xcf,0x3b,0xca,0x2b,0xa9,0x3a,0x27,0x42,0x69,0x42,0x48,0x42,0xc8,0x13,0x87,0x75,0x10,0x95,0x10,0x8d,0x30,0x54,0x8d,0x0b,0xa8,0x0b,0x86,0x23,0x68,0x29,0xa5,0x11,0x02,0x10,0xa2,0x10,0xa2,0x10,0xc2,0x10,0xa1,0x19,0x03,0x5b,0xcb,0x03,0x25,0x03,0xa6,0x03,0xa6,0x03,0xc7,0x03,0x46,0x0b,0x87,0x0b,0xa7,0x03,0x66,0x24,0x28,0x33,0xa9,0x43,0x47,0x0a,0x85,0x0a,0x84,0x3b,0x28,0x23,0x07,0x3c,0xac,0x03,0xe7,0x0b,0xc6,0x0b,0xe8,0x03,0xe7,0x0c,0x28
,0x0c,0x07,0x13,0xe7,0x14,0x07,0x14,0x07,0x03,0xc6,0x0b,0xa6,0x4b,0xea,0x6b,0xea,0x33,0xa7,0x0a,0x64,0x64,0x2c,0x2b,0x28,0x53,0xea,0x1b,0x26,0x1b,0x67,0x0b,0x26,0x13,0x26,0x2b,0xaa,0x1b,0x48,0x02,0xe5,0x02,0xc5,0x3b,0x08,0x32,0x28,0x0b,0x75,0x03,0x56,0x03,0x55,0x03,0x55,0x03,0x76,0x12,0x6c,0x32,0xc8,0x02,0x44,0x2b,0x47,0x3c,0x0a,0x54,0x4c,0x84,0xae,0xce,0x13,0xad,0x94,0x5c,0x4d,0x2b,0x89,0x32,0x06,0x31,0xe7,0x31,0xe7,0x42,0xa8,0x13,0x26,0xad,0xd3,0xce,0x34,0xce,0x55,0x74,0xaf,0x85,0x71,0x6c,0xee,0x2b,0x28,0x29,0xa5,0x21,0x23,0x10,0xa2,0x10,0xa2,0x10,0xc2,0x10,0xa2,0x18,0xe2,0x63,0xcb,0x03,0x46,0x03,0x86,0x03,0xa6,0x03,0xe7,0x13,0x87,0x13,0x88,0x13,0xc8,0x13,0x87,0x24,0x28,0x3b,0xc9,0x6c,0x0b,0x22,0xe6,0x12,0xa5,0x6b,0xeb,0x33,0x48,0x44,0xac,0x13,0xc8,0x13,0xe7,0x14,0x07,0x03,0xc7,0x0c,0x08
,0x0c,0x08,0x5d,0x2f,0x6d,0x50,0x65,0x0e,0x2c,0x69,0x03,0xa6,0x8d,0x2f,0x94,0x4b,0x7c,0x8d,0x22,0xe7,0x8c,0x4d,0x7c,0xae,0x64,0x6d,0x8d,0x71,0x6c,0xce,0x6c,0x6d,0x7d,0x30,0x03,0x06,0x33,0x48,0xa5,0xb3,0x8d,0x10,0x6b,0xeb,0x42,0x48,0x12,0xae,0x03,0x96,0x03,0x56,0x03,0x76,0x0b,0x74,0x19,0xa6,0x52,0xe9,0x95,0x10,0xad,0xd3,0x54,0x6d,0x3c,0x0b,0x7c,0xcf,0x33,0x48,0x4b,0xec,0x33,0xca,0x2b,0x48,0x42,0x47,0x42,0x47,0x42,0x68,0x42,0xa8,0x12,0xa6,0xa5,0x91,0x73,0xeb,0x73,0xcb,0x7c,0x6e,0xa5,0x93,0x9d,0x31,0x4b,0x29,0x4a,0x27,0x21,0x64,0x10,0xc2,0x10,0xc2,0x10,0xc2,0x18,0xc2,0x21,0x24,0x73,0x8b,0x9d,0x32,0xad,0xf5,0x5c,0x6d,0x03,0xe7,0x64,0xed,0x75,0x0f,0x4c,0x8c,0x3c,0x8b,0x24,0x28,0x84,0x6e,0x94,0x4b,0x6c,0x4c,0x53,0xaa,0x9c,0x2b,0x84,0x8e,0x54,0x8c,0x6d,0x4f,0x85,0xb0,0x54,0xec,0x03,0xe7,0x0c,0x08
,0x0c,0x07,0x0c,0x27,0x1c,0x68,0x24,0x69,0x0b,0xc6,0x0b,0xa6,0x54,0x0a,0x64,0x0b,0x2b,0x27,0x02,0x44,0x43,0x69,0x22,0xc6,0x54,0x2b,0x13,0x26,0x2b,0xa8,0x2b,0xa9,0x23,0xa9,0x03,0x45,0x3b,0xea,0xce,0x78,0xb5,0xd3,0x9c,0xf0,0x52,0xa8,0x29,0xe7,0x12,0x8d,0x1b,0x74,0x13,0x31,0x22,0x09,0x42,0x07,0x7c,0x0e,0xb5,0x92,0xa4,0xd0,0x7c,0xcf,0x3b,0xca,0x54,0x4e,0x7c,0xd0,0x8c,0x8f,0x64,0xce,0x2b,0x48,0x3a,0x26,0x42,0x47,0x42,0x68,0x42,0xa8,0x0a,0x85,0x9d,0x52,0x7c,0x2e,0x73,0xcd,0x64,0x2d,0xb5,0x53,0xb5,0x93,0x8c,0x8f,0x4a,0x68,0x31,0xa6,0x21,0x64,0x21,0x44,0x29,0x64,0x29,0x64,0x42,0x07,0x83,0xcd,0xc5,0xd3,0xbd,0x93,0x7d,0x10,0x03,0xe7,0x13,0xa7,0x1b,0xe8,0x1b,0xe8,0x0b,0x66,0x1c,0x28,0x3b,0xa9,0x5b,0xeb,0x1a,0xc6,0x12,0x85,0x63,0xea,0x33,0x49,0x3c,0xac,0x14,0x08,0x24,0x49,0x1c,0x4a,0x04,0x07,0x0c,0x08
,0x0c,0x08,0x03,0xe7,0x03,0xe7,0x03,0xc6,0x03,0xc6,0x0b,0xc6,0x44,0x09,0x43,0x67,0x1b,0x26,0x02,0x64,0x3b,0x69,0x1a,0xa6,0x54,0x2a,0x0a,0xe5,0x02,0xe5,0x0b,0x26,0x03,0x26,0x03,0xc6,0x13,0x88,0x4c,0x6d,0x4c,0x0b,0x53,0xea,0x74,0x8d,0x6c,0x6d,0x63,0xeb,0x5b,0xec,0x5b,0xcb,0x5b,0x6a,0x63,0xeb,0x5c,0x2c,0x43,0x8a,0x43,0xeb,0x23,0x48,0x33,0xc9,0x3b,0xea,0x7d,0x0f,0x7c,0xae,0x7d,0x10,0x4c,0x2b,0x63,0x8b,0x53,0x4a,0x4b,0x2a,0x4b,0x8a,0x13,0x06,0x74,0x6e,0x5c,0x0b,0x4b,0xeb,0x2b,0x68,0x3b,0xca,0x23,0x28,0x3b,0x69,0x7c,0x6e,0x6b,0xcc,0x43,0x08,0x4b,0x29,0x3a,0xa7,0x42,0xc9,0x63,0xcc,0x74,0xae,0x33,0xa9,0x3c,0x0a,0x23,0xa9,0x03,0xe7,0x03,0x46,0x03,0x66,0x0b,0x86,0x03,0x45,0x1c,0x28,0x33,0xc8,0x43,0x48,0x12,0xa5,0x0a,0x64,0x43,0x48,0x23,0x26,0x3c,0xac,0x03,0xa6,0x03,0xc6,0x03,0xc7,0x03,0xe7,0x0c,0x08
,0x04,0x08,0x5d,0x2e,0x6d,0x6f,0x44,0xec,0x34,0x8a,0x13,0xa6,0x8c,0xef,0x9c,0x4c,0x7c,0xae,0x1a,0xc6,0x8c,0x8e,0x74,0x8e,0x64,0x0c,0x85,0x50,0x6c,0xcd,0x4c,0x4c,0x44,0xac,0x03,0xc6,0x03,0xc6,0x03,0xc6,0x03,0xa6,0x03,0x45,0x03,0x24,0x2b,0x88,0x54,0x0b,0x43,0xe9,0x33,0xa8,0x02,0xc3,0x02,0xc4,0x02,0xc4,0x02,0xa4,0x03,0x05,0x03,0x05,0x54,0x4c,0x1b,0xc8,0x03,0xa7,0x2b,0xc8,0x33,0xea,0x54,0xac,0xa5,0xb2,0x43,0x28,0x3b,0x29,0x3b,0x49,0x1b,0x47,0x8d,0x30,0x95,0x10,0x6c,0xae,0x13,0x47,0x03,0x06,0x23,0x89,0x64,0xaf,0x64,0x6d,0x2a,0xe7,0x33,0x48,0x3b,0xea,0x1b,0x47,0x13,0x46,0x13,0x26,0x1b,0xa8,0x03,0x66,0x03,0xa6,0x03,0xa6,0x03,0xa7,0x54,0xad,0x75,0x0f,0x64,0xed,0x3c,0x4a,0x23,0xc7,0x7c,0x8c,0x94,0x2b,0x64,0x2c,0x53,0xaa,0xa4,0xac,0x84,0x8e,0x74,0xee,0x7d,0x4f,0x6d,0x2e,0x75,0x4f,0x0c,0x08,0x0c,0x29
,0x0c,0x07,0x1c,0x48,0x2c,0x69,0x2c,0xaa,0x24,0x6a,0x13,0xc7,0x64,0x4c,0x7c,0x6c,0x43,0x89,0x0a,0x64,0x5b,0xeb,0x2a,0xe7,0x53,0xeb,0x23,0x47,0x33,0xc9,0x43,0xeb,0x3c,0x6b,0x03,0xc6,0x03,0xc5,0x03,0xa5,0x03,0x85,0x03,0x65,0x03,0x44,0x23,0x47,0x33,0x07,0x3b,0x28,0x1a,0xa5,0x02,0x43,0x02,0x63,0x02,0xa4,0x02,0xc4,0x2b,0x48,0x2b,0x68,0x64,0xef,0x34,0x4c,0x3c,0x6b,0x3c,0x0b,0x3c,0x2c,0x1c,0x29,0xa5,0x93,0xb5,0xb2,0xbd,0xd3,0x7c,0xcf,0x54,0x2d,0x9c,0xf0,0x6b,0x8b,0x9d,0x52,0x33,0xca,0x02,0xc5,0x1b,0x27,0x74,0x8f,0x54,0x0c,0x53,0x6a,0x6b,0x8c,0x7c,0xaf,0x6c,0xae,0x6c,0xcd,0x6c,0xee,0x44,0x6c,0x03,0x25,0x03,0x45,0x03,0x45,0x03,0x85,0x1b,0xc9,0x2b,0xc9,0x2c,0x4a,0x23,0xe8,0x23,0xa8,0x4b,0xaa,0x84,0x6c,0x33,0x27,0x23,0x07,0x84,0x8d,0x53,0xca,0x4c,0xcd,0x1b,0xe8,0x3c,0xab,0x34,0x8b,0x0c,0x08,0x0c,0x29
,0x04,0x27,0x03,0xc6,0x04,0x07,0x03,0xe6,0x03,0xc6,0x03,0xa6,0x3c,0x0a,0x22,0x85,0x12,0xa4,0x02,0x64,0x1a,0xc5,0x0a,0x85,0x4b,0xeb,0x02,0xc4,0x02,0xe5,0x02,0xe5,0x03,0x25,0x03,0xa6,0x03,0x05,0x02,0xe5,0x02,0xc5,0x02,0xa4,0x02,0x84,0x02,0x23,0x02,0x03,0x01,0xe2,0x02,0x22,0x02,0x23,0x02,0x43,0x0a,0x83,0x2b,0x48,0x84,0xd0,0x95,0x71,0x9d,0x73,0x8c,0xd1,0x8d,0x10,0x5c,0x8d,0x3b,0xeb,0x13,0xa8,0x85,0x31,0x6c,0x2d,0x74,0x8e,0x5c,0x4d,0x54,0x0c,0x7c,0x6e,0x5b,0x8a,0x74,0xaf,0x33,0xea,0x02,0xe5,0x24,0x09,0x73,0xac,0x4c,0x0b,0x43,0x09,0x4a,0x88,0x4b,0xaa,0x2b,0x68,0x23,0x07,0x02,0xc5,0x03,0x05,0x03,0x26,0x03,0x26,0x03,0x26,0x03,0x26,0x03,0x25,0x03,0xa6,0x03,0x45,0x03,0xc6,0x23,0xa8,0x2b,0x48,0x2a,0xc6,0x02,0x64,0x02,0x84,0x22,0x85,0x12,0xc5,0x3c,0xac,0x03,0xc7,0x03,0xe6,0x03,0xe7,0x03,0xe7,0x0c,0x08
,0x0c,0x07,0x4c,0xcc,0x5d,0x0d,0x3c,0xcb,0x34,0x69,0x13,0xe7,0x7c,0xce,0xac,0xcd,0x7c,0x8d,0x1a,0x85,0x94,0xcf,0x64,0x4d,0x5c,0x0b,0x64,0x8d,0x54,0x4c,0x43,0xeb,0x44,0x6b,0x03,0x05,0x02,0x84,0x02,0x84,0x02,0x84,0x02,0x63,0x02,0x43,0x0a,0x23,0x02,0x02,0x02,0x02,0x02,0x22,0x02,0x43,0x02,0x64,0x1a,0x84,0x74,0x8f,0x8c,0x8e,0x95,0x10,0x94,0xaf,0x8c,0xb0,0x8c,0x8e,0x2c,0x0a,0x64,0xce,0x8d,0x92,0x6d,0x0f,0x6d,0x10,0x44,0x4b,0x23,0xe8,0x9d,0xd3,0xa6,0x14,0x2b,0xc9,0x0b,0x87,0x0b,0x46,0x54,0xae,0x6c,0xce,0x84,0xb0,0x43,0x8a,0x63,0xcc,0x8c,0x6f,0x64,0x2d,0x54,0x4c,0x4c,0x0b,0x03,0x05,0x03,0x25,0x03,0x25,0x03,0x25,0x03,0x45,0x03,0x46,0x44,0x4a,0x5c,0xac,0x44,0x8b,0x34,0x8a,0x23,0x87,0x6c,0x4c,0x9c,0x8c,0x5c,0x0b,0x4b,0x68,0xa4,0x8c,0x7c,0x4d,0x4c,0x8c,0x6d,0x0e,0x65,0x2e,0x54,0xac,0x0b,0xc7,0x0c,0x08
,0x04,0x07,0x34,0x8a,0x3c,0xab,0x3c,0xcb,0x34,0x8a,0x1c,0x07,0x6c,0x6c,0x9c,0xad,0x5b,0xec,0x12,0x64,0x6b,0xeb,0x4b,0x8a,0x53,0xeb,0x33,0xa9,0x4b,0xea,0x4c,0x0b,0x4c,0x0a,0x02,0x84,0x02,0x83,0x02,0x83,0x02,0xc3,0x02,0xa3,0x02,0x83,0x02,0x83,0x02,0x63,0x02,0x03,0x01,0xe2,0x02,0x23,0x02,0x63,0x0a,0x64,0x53,0xeb,0x5b,0xec,0x64,0x0b,0x74,0xae,0x5c,0x2d,0x74,0xae,0x23,0x69,0x6c,0xae,0x8c,0x8f,0x9d,0x30,0x7d,0x11,0x64,0x8e,0x95,0x93,0x9d,0x11,0x94,0xb0,0x6d,0x10,0x44,0xad,0x4c,0x4c,0x6c,0x4d,0x2a,0xc7,0x6c,0x0e,0x33,0x69,0x44,0x2b,0x54,0x0c,0x2b,0x68,0x02,0xc4,0x02,0xe5,0x02,0xc4,0x03,0x86,0x03,0x85,0x03,0xa6,0x03,0xa6,0x03,0xc6,0x34,0x6a,0x34,0x6b,0x34,0x8b,0x2c,0x6a,0x23,0x68,0x5b,0xea,0x84,0x6d,0x43,0x8a,0x33,0x27,0x8c,0x6c,0x64,0x0c,0x44,0xac,0x34,0x4a,0x5d,0x0d,0x4c,0xcd,0x0c,0x08,0x0c,0x29
,0x04,0x07,0x04,0x07,0x03,0xe7,0x03,0xe6,0x03,0xc6,0x03,0xa5,0x3c,0x2a,0x12,0x23,0x02,0x63,0x02,0x63,0x0a,0x24,0x02,0x24,0x43,0xea,0x02,0xa4,0x02,0xa4,0x02,0xa4,0x02,0xa4,0x02,0xa4,0x02,0x84,0x02,0xe4,0x0b,0x24,0x23,0x66,0x23,0x86,0x02,0xe3,0x02,0xc3,0x02,0x23,0x02,0x23,0x02,0x23,0x02,0x23,0x01,0xc2,0x1a,0x24,0x12,0x04,0x09,0xc3,0x12,0x24,0x12,0x44,0x63,0xeb,0x5b,0xec,0x74,0x8f,0x6c,0x2c,0x64,0x0c,0x8d,0x72,0x5b,0xca,0x84,0x8f,0x9d,0x73,0x95,0x11,0x84,0xf0,0x95,0x52,0x8c,0xf1,0x6b,0x8c,0x11,0x63,0x4a,0xa8,0x22,0xa6,0x03,0x65,0x1b,0xa8,0x13,0x46,0x02,0xe5,0x03,0x05,0x03,0x05,0x02,0xc5,0x02,0xe5,0x03,0x05,0x03,0x06,0x03,0x26,0x03,0x26,0x03,0x26,0x03,0x26,0x03,0x05,0x23,0x87,0x2b,0xc8,0x12,0x44,0x02,0x64,0x02,0x84,0x0a,0x43,0x0a,0xc5,0x44,0xcc,0x03,0xc7,0x03,0xc7,0x03,0xe7,0x04,0x08,0x0c,0x08
,0x04,0x07,0x34,0x8b,0x3c,0xcc,0x2c,0x89,0x24,0x6a,0x0b,0xa6,0x6c,0x6d,0x9c,0xad,0x64,0x4b,0x0a,0x64,0x74,0x2c,0x43,0x89,0x4b,0xea,0x43,0xea,0x44,0x0a,0x23,0x47,0x3b,0xa9,0x02,0x83,0x02,0x63,0x02,0xc4,0x0b,0x25,0x23,0x47,0x2b,0xa9,0x43,0xca,0x5b,0xaa,0x7c,0x6e,0x2a,0xc6,0x02,0x43,0x09,0xe3,0x11,0x63,0x29,0xc5,0x29,0xc5,0x29,0xc5,0x32,0x06,0x3a,0x06,0x31,0xe5,0x32,0x67,0x95,0x12,0x63,0xcd,0x9d,0xb4,0xa5,0x72,0xac,0xef,0xad,0x31,0xa5,0x93,0x9d,0x11,0x63,0x4b,0x84,0x4e,0x74,0x2d,0x19,0x03,0x21,0x23,0x19,0x03,0x32,0x86,0x23,0x27,0x8c,0xf1,0x84,0xf0,0x33,0x49,0x1a,0xe7,0x02,0x64,0x03,0x25,0x03,0x05,0x03,0x25,0x03,0x45,0x03,0x66,0x34,0x0a,0x44,0x4b,0x2c,0x09,0x1b,0xc7,0x1c,0x08,0x64,0x2b,0xa4,0xcd,0x4b,0xaa,0x33,0x27,0x9c,0xed,0x6c,0x2b,0x44,0x8b,0x4c,0xab,0x4c,0xcc,0x34,0x6a,0x04,0x27,0x0c,0x08
,0x04,0x07,0x4c,0xcc,0x5d,0x2e,0x4d,0x0c,0x44,0xcb,0x24,0x08,0x7c,0xad,0x94,0x8c,0x74,0x4c,0x12,0x64,0x73,0xeb,0x53,0xaa,0x4c,0x0b,0x44,0x0b,0x6c,0xef,0x3b,0xca,0x5c,0x4d,0x02,0x64,0x02,0x43,0x02,0xa3,0x0a,0xe5,0x23,0x47,0x33,0x87,0x43,0x8a,0x5b,0x6a,0x7c,0x4d,0x2a,0xe6,0x02,0x23,0x12,0x44,0x21,0x84,0x21,0x44,0x29,0x64,0x31,0xc6,0x31,0xc6,0x31,0xa5,0x29,0x85,0x3a,0x67,0x6c,0x6e,0x4b,0x6a,0x63,0xec,0x7c,0x6f,0x7c,0x6d,0x74,0x2d,0x85,0x30,0x6c,0x6d,0x4b,0x49,0x7c,0x6e,0x64,0x4e,0x52,0x88,0x4a,0x68,0x42,0x27,0x53,0x4a,0x84,0xf0,0x53,0x09,0x53,0x6b,0x7c,0x70,0x54,0x6d,0x1b,0x27,0x23,0xe9,0x13,0xc7,0x03,0xa6,0x03,0xa6,0x03,0xc6,0x44,0xac,0x4c,0xcc,0x44,0x8b,0x3c,0xaa,0x1c,0x28,0x74,0x4d,0x9c,0x8b,0x5b,0xea,0x3b,0x47,0x9c,0x6c,0x74,0x2c,0x4c,0x6b,0x4c,0xab,0x65,0x4e,0x55,0x2e,0x0c,0x28,0x0c,0x28
,0x04,0x26,0x03,0xc6,0x03,0xe6,0x03,0xe6,0x03,0xc5,0x03,0xa6,0x3c,0x09,0x22,0x84,0x0a,0x63,0x02,0x63,0x12,0x65,0x0a,0x44,0x43,0xea,0x02,0x84,0x02,0xa3,0x02,0x84,0x02,0x84,0x02,0x63,0x02,0x43,0x02,0xa3,0x0a,0xc4,0x1b,0x06,0x23,0x48,0x53,0xca,0x73,0x8b,0x84,0x6e,0x32,0xe7,0x02,0x84,0x09,0xe2,0x21,0x84,0x21,0x44,0x21,0x64,0x29,0x85,0x29,0x85,0x29,0xa5,0x29,0x85,0x32,0x67,0x6c,0x6d,0x94,0xf1,0x95,0x11,0x95,0x51,0x9d,0xd3,0x95,0x52,0x85,0x11,0x7c,0xd0,0x8d,0x30,0x9d,0xb3,0x23,0x07,0xa5,0x93,0x94,0xf0,0x8c,0xb0,0x4b,0xab,0x95,0x31,0x7c,0x2d,0x84,0x8f,0x74,0x0d,0x54,0x0c,0x43,0xaa,0x64,0xee,0x44,0x8b,0x03,0xc6,0x03,0xc5,0x03,0xc6,0x03,0xc6,0x03,0xe6,0x03,0xe6,0x03,0xc6,0x1c,0x28,0x2b,0xa9,0x22,0x85,0x02,0x64,0x02,0x85,0x1a,0x65,0x12,0xc5,0x3c,0xcc,0x03,0xe7,0x03,0xe6,0x03,0xe6,0x03,0xe7,0x14,0x08
,0x04,0x27,0x24,0x49,0x24,0x49,0x1c,0x48,0x14,0x07,0x0b,0xa6,0x5c,0x2a,0x7c,0x2b,0x54,0x0a,0x0a,0x44,0x63,0xcb,0x32,0xe8,0x4b,0xaa,0x33,0x68,0x33,0x87,0x23,0x06,0x23,0x27,0x02,0x63,0x02,0xa3,0x02,0xc4,0x02,0xa3,0x02,0xa3,0x02,0xa3,0x22,0xe5,0x32,0x86,0x43,0x69,0x1b,0x06,0x02,0x63,0x09,0xe3,0x21,0xa5,0x29,0xa5,0x31,0xa6,0x29,0x85,0x31,0xc6,0x31,0xc6,0x31,0xc6,0x32,0x66,0x6c,0x2d,0x7c,0x2e,0x7c,0x4d,0x7c,0x8f,0x75,0x51,0xa5,0xb3,0x8d,0x32,0x8d,0x32,0x9d,0x93,0x8d,0x92,0x0a,0x85,0x3b,0xaa,0x33,0x69,0x43,0x49,0x3a,0xe8,0x53,0xaa,0x6c,0x4d,0x74,0xaf,0x6c,0x8e,0x43,0xeb,0x02,0xa5,0x03,0xa6,0x03,0xc6,0x03,0xc6,0x03,0xc6,0x03,0xc6,0x24,0x49,0x24,0x69,0x24,0x69,0x24,0x28,0x34,0x6a,0x4b,0xea,0x84,0x2b,0x3b,0x48,0x22,0xe6,0x8c,0x4c,0x53,0xaa,0x44,0x8b,0x3c,0x4a,0x34,0x6a,0x34,0x49,0x03,0xe7,0x14,0x08
,0x04,0x07,0x55,0x0d,0x75,0x6f,0x5d,0x4f,0x3c,0xab,0x1c,0x08,0x84,0xce,0x8b,0xea,0x7c,0x6d,0x12,0x64,0x7c,0x0b,0x4b,0x49,0x53,0xea,0x6c,0x6c,0x8d,0x70,0x5c,0x0a,0x4c,0x0a,0x02,0xc3,0x02,0xe4,0x02,0xc3,0x02,0xa3,0x02,0xa3,0x02,0x83,0x33,0x27,0x3a,0xc6,0x43,0x08,0x3b,0x49,0x02,0xe4,0x01,0xc2,0x21,0xa5,0x29,0x85,0x29,0xa5,0x31,0xc6,0x29,0x85,0x31,0xc6,0x29,0x85,0x32,0x46,0x7c,0x8f,0x94,0xd0,0x94,0x90,0xa5,0xb3,0xae,0x14,0xad,0xd4,0x8d,0x11,0x95,0x73,0xb6,0x15,0x95,0x51,0x3b,0xaa,0x5c,0x6d,0x23,0x06,0x53,0x69,0x6b,0xcb,0x43,0x48,0x22,0xc6,0x13,0x05,0x03,0x45,0x03,0x04,0x02,0xc5,0x03,0x45,0x03,0xc6,0x03,0xc6,0x03,0xc6,0x03,0xc6,0x4c,0xcc,0x5d,0x0e,0x3c,0xab,0x4c,0xed,0x44,0xac,0x7c,0x8d,0x94,0x2b,0x6c,0x2c,0x43,0x88,0x9c,0x4c,0x7c,0x6d,0x4c,0x8b,0x64,0xcd,0x75,0x6f,0x75,0x4f,0x1c,0x69,0x14,0x08
,0x04,0x06,0x0c,0x07,0x14,0x27,0x14,0x07,0x14,0x07,0x0b,0xc6,0x3b,0xe9,0x3b,0x48,0x1a,0xa5,0x02,0x43,0x1a,0x84,0x0a,0x04,0x43,0xc9,0x0a,0xc5,0x0b,0x66,0x0b,0x65,0x0b,0x65,0x03,0x04,0x02,0xe3,0x02,0xc3,0x2b,0x87,0x3b,0xc9,0x1a,0xc4,0x63,0xcb,0x83,0xec,0x84,0x0d,0x74,0x4e,0x0a,0x23,0x09,0xe3,0x21,0xa4,0x21,0x64,0x29,0x64,0x31,0xa5,0x29,0x85,0x29,0x85,0x21,0x64,0x32,0x26,0x63,0xec,0x84,0x90,0x84,0xd1,0x84,0xcf,0x85,0x71,0x8d,0x32,0x53,0x2a,0x7c,0xb0,0x7d,0x52,0x64,0xd0,0x4c,0x2d,0xa5,0x72,0xb4,0xed,0xc4,0xca,0xc5,0x0a,0xc5,0x0b,0xad,0x0e,0x3c,0x4b,0x03,0xa5,0x03,0xa5,0x03,0x25,0x03,0x25,0x03,0xc6,0x03,0xc6,0x03,0xc6,0x03,0xc6,0x03,0xe6,0x0b,0xc7,0x0c,0x07,0x0c,0x07,0x24,0x28,0x2b,0xc9,0x43,0x68,0x0a,0x85,0x02,0x64,0x3b,0x27,0x1a,0xe6,0x44,0xcc,0x03,0xe7,0x0b,0xe7,0x0c,0x07,0x04,0x07,0x0c,0x08
,0x04,0x07,0x04,0x06,0x04,0x06,0x03,0xc6,0x03,0xa5,0x0b,0xa6,0x4c,0x0a,0x6b,0xea,0x33,0x07,0x0a,0x64,0x5b,0xeb,0x32,0xe7,0x43,0xa9,0x12,0xe5,0x13,0x86,0x0b,0x65,0x0b,0x45,0x03,0x04,0x03,0x03,0x02,0xc3,0x02,0x84,0x02,0x62,0x02,0x62,0x43,0x09,0x3a,0x25,0x3a,0x86,0x4b,0xcb,0x02,0x44,0x09,0xe4,0x21,0x84,0x21,0x24,0x21,0x44,0x31,0xe5,0x31,0xa5,0x21,0x64,0x21,0x44,0x3a,0x67,0x4b,0xaa,0x6c,0x0d,0x74,0x4e,0x84,0xf0,0x8c,0xef,0x7c,0x4d,0x95,0x51,0x8c,0xf0,0x8c,0xd0,0x74,0x4d,0xa5,0x93,0x9d,0x72,0xcd,0x6e,0xe5,0x4a,0xe5,0x2a,0xdd,0x49,0xc5,0xd0,0x3c,0x6b,0x03,0xc6,0x03,0xa5,0x03,0x45,0x03,0x06,0x03,0xe6,0x03,0xe6,0x03,0xe6,0x03,0xe6,0x14,0x27,0x14,0x08,0x14,0x28,0x14,0x07,0x24,0x29,0x43,0xca,0x6b,0xeb,0x22,0xe6,0x12,0xa5,0x6b,0xea,0x3b,0x68,0x44,0xab,0x13,0xe7,0x14,0x07,0x13,0xe7,0x0c,0x07,0x0c,0x28
,0x0c,0x28,0x5d,0x4e,0x7d,0x90,0x5d,0x2e,0x34,0x6a,0x2c,0x29,0x8c,0xef,0x8b,0xea,0x7c,0x6d,0x22,0xa7,0x84,0x0c,0x6c,0x0d,0x53,0xaa,0x74,0xce,0x7d,0x2f,0x44,0x4b,0x65,0x2e,0x03,0x24,0x03,0x04,0x02,0xc3,0x12,0xe6,0x23,0x27,0x12,0xc4,0x5b,0xab,0x73,0xab,0x73,0xcb,0x64,0x0c,0x02,0x64,0x02,0x23,0x21,0xe5,0x31,0xc6,0x31,0xc6,0x31,0xc5,0x31,0xe5,0x31,0xe5,0x29,0xc5,0x2a,0xe7,0x54,0x0b,0x5b,0x4a,0x6c,0x0d,0x9d,0x52,0x9d,0x31,0x9d,0x10,0x8c,0xf0,0x95,0x72,0xa5,0x32,0x8c,0xae,0x84,0xaf,0x85,0x31,0x84,0x8d,0x8c,0x8b,0x94,0x8c,0xa4,0xac,0x84,0x6d,0x4c,0x2b,0x4c,0xcc,0x34,0x6a,0x0b,0x66,0x03,0x26,0x03,0xc6,0x03,0xe6,0x03,0xc6,0x03,0xe6,0x5d,0x0d,0x65,0x6f,0x3c,0xcb,0x65,0x0e,0x5c,0xed,0x8c,0x8e,0x9c,0x0b,0x6c,0x2c,0x4b,0x89,0x9c,0x4b,0x84,0xae,0x54,0x6b,0x75,0x2e,0x4c,0xac,0x44,0xac,0x44,0xed,0x0c,0x08
,0x0c,0x07,0x14,0x29,0x24,0x6a,0x2c,0x6a,0x1c,0x69,0x13,0xc7,0x4b,0xea,0x64,0x0b,0x2b,0x27,0x02,0x44,0x3a,0xe7,0x1a,0x65,0x4b,0xaa,0x12,0xc5,0x23,0xc8,0x1b,0xe8,0x0b,0x66,0x03,0x24,0x02,0xe4,0x02,0xa4,0x1a,0xe6,0x23,0x26,0x1a,0xc5,0x43,0x09,0x3a,0x25,0x3a,0x66,0x53,0xcb,0x02,0x44,0x02,0x44,0x12,0x44,0x2a,0x66,0x22,0x44,0x1a,0x65,0x2a,0x86,0x1a,0x65,0x3b,0x49,0x33,0xe9,0x54,0xcd,0x6d,0x2f,0x55,0x0e,0x54,0x6c,0x43,0x49,0x4b,0x6a,0x53,0xcb,0x4b,0xcb,0x43,0x6a,0x3b,0x49,0x4b,0xab,0x43,0xca,0x7c,0x6d,0x43,0x68,0x22,0x65,0x32,0x85,0x33,0x48,0x2b,0x89,0x4c,0x4d,0x5c,0xcf,0x13,0xa7,0x03,0x05,0x03,0x45,0x03,0x45,0x03,0x66,0x03,0x66,0x13,0x87,0x1b,0xa7,0x24,0x4a,0x24,0x6a,0x2c,0x69,0x3b,0xca,0x5b,0xca,0x1b,0x06,0x12,0x85,0x63,0xeb,0x33,0x48,0x4c,0xac,0x0b,0xe7,0x24,0x49,0x1c,0x69,0x1c,0x6a,0x0c,0x08
,0x04,0x07,0x03,0xc7,0x03,0xe6,0x03,0xc6,0x03,0xa6,0x0b,0xa6,0x3b,0xea,0x43,0x48,0x12,0xa5,0x02,0x44,0x2a,0xe6,0x12,0x65,0x43,0xa9,0x0a,0x84,0x03,0x45,0x03,0x65,0x03,0x45,0x0b,0x46,0x13,0x25,0x12,0xa4,0x02,0x63,0x02,0x63,0x02,0x43,0x43,0x49,0x63,0x6a,0x6b,0xab,0x32,0xc7,0x3b,0x89,0x3b,0x89,0x3b,0x6a,0x64,0x2e,0x5c,0x0c,0x53,0xec,0x7c,0xcf,0x43,0xca,0x43,0xeb,0x3b,0xea,0x44,0x8c,0x65,0x0f,0x5d,0x2f,0x7d,0x10,0x8c,0x8f,0x7c,0x0d,0x95,0x31,0x8d,0x31,0x8c,0x4f,0x73,0xcc,0x9d,0x52,0x64,0x6e,0x4a,0xe8,0x4b,0x8b,0x4b,0x0b,0x53,0x2b,0x13,0x05,0x1b,0xc7,0x44,0x0b,0x13,0x67,0x03,0x86,0x02,0xe5,0x02,0xc5,0x02,0xc5,0x02,0xc5,0x02,0xe5,0x02,0xe5,0x02,0xe6,0x03,0x45,0x03,0xc6,0x1c,0x28,0x33,0xca,0x43,0x68,0x12,0x84,0x0a,0x85,0x4b,0x28,0x23,0x06,0x44,0xab,0x03,0xa6,0x03,0xc6,0x03,0xe6,0x03,0xc6,0x0c,0x07
,0x0c,0x07,0x5d,0x2e,0x7d,0x90,0x4d,0x0d,0x4c,0xab,0x23,0xe8,0x84,0xef,0x9c,0x2b,0x7c,0x6d,0x12,0x86,0x73,0xec,0x5b,0xab,0x4b,0xaa,0x7c,0xcf,0x64,0xee,0x6d,0x2f,0x0b,0x25,0x23,0x67,0x33,0x68,0x3b,0x27,0x02,0x63,0x02,0x43,0x02,0x43,0x3b,0x07,0x42,0x25,0x4b,0x08,0x3b,0x07,0x2b,0x27,0x43,0xca,0x84,0x8e,0x9d,0x31,0x33,0x08,0x8c,0xd0,0x95,0x11,0x54,0x0b,0x6c,0x4d,0x53,0xca,0x43,0xc9,0x7c,0xcf,0x74,0xce,0x74,0x6e,0x7c,0x2e,0x63,0x8b,0x5b,0xab,0x74,0x6e,0x6b,0xcc,0x63,0x8a,0x84,0xd0,0x74,0xcf,0x7c,0x4e,0x5b,0xec,0x53,0x6c,0x53,0x8d,0x12,0xe6,0x2b,0x88,0x64,0xaf,0x23,0x27,0x13,0x67,0x13,0x06,0x02,0xe5,0x02,0xe4,0x02,0xe4,0x03,0x05,0x64,0x8d,0x6c,0xcf,0x4c,0x4c,0x5c,0xce,0x65,0x2e,0x84,0x8e,0xa4,0xed,0x64,0x0b,0x43,0x69,0x9c,0x4c,0x84,0x6d,0x54,0x6b,0x6d,0x6e,0x6d,0x4e,0x4c,0x8b,0x55,0x4e,0x0c,0x29
,0x0c,0x07,0x1c,0x49,0x2c,0x8a,0x34,0xab,0x24,0x48,0x1b,0xc7,0x54,0x0a,0x7c,0x2b,0x43,0x89,0x0a,0x44,0x43,0x08,0x12,0x45,0x4b,0xa9,0x1b,0x06,0x3b,0xa9,0x3b,0xc9,0x03,0x45,0x02,0xc5,0x32,0xe7,0x42,0xe7,0x2a,0xc7,0x32,0xc6,0x32,0xa6,0x4b,0x08,0x5a,0xc8,0x5b,0x2a,0x53,0x49,0x3b,0x28,0x33,0xea,0x73,0xec,0x73,0xec,0x2b,0x07,0x7c,0x2c,0x6b,0xab,0x84,0x8e,0xad,0x72,0x8c,0xcf,0xa5,0x93,0x95,0x30,0x7d,0x11,0x9d,0x93,0x4b,0xab,0x74,0x4e,0x29,0xe5,0x7c,0x2e,0x74,0x8f,0x9d,0x93,0xad,0xf4,0x4c,0x4c,0x4c,0x2b,0x2b,0x48,0x0a,0x65,0x0a,0xa5,0x13,0x05,0x8d,0x31,0x85,0x51,0x75,0x2f,0x4d,0x2f,0x85,0xd1,0x03,0xc7,0x03,0xc6,0x03,0xc6,0x03,0xc6,0x1b,0x88,0x1b,0x68,0x2b,0xc9,0x2b,0xc9,0x44,0x2b,0x5c,0x0b,0x84,0x8c,0x33,0x07,0x1a,0xa4,0x74,0x2b,0x43,0x28,0x4c,0x8b,0x1c,0x07,0x2c,0x8a,0x3c,0xaa,0x2c,0xaa,0x0c,0x08
,0x0c,0x07,0x04,0x06,0x03,0xe6,0x03,0xc6,0x03,0xc6,0x0b,0x85,0x33,0xe9,0x22,0x85,0x0a,0x44,0x02,0x44,0x1a,0x65,0x0a,0x03,0x43,0xa9,0x02,0xa4,0x02,0x43,0x02,0xa4,0x03,0x25,0x0a,0x65,0x10,0xc2,0x10,0xa1,0x08,0xa1,0x10,0xc2,0x10,0xa1,0x10,0xa2,0x10,0xc2,0x10,0xc2,0x10,0xc1,0x09,0x02,0x1b,0x27,0x7c,0x0c,0x7b,0xec,0x2b,0x48,0x74,0x0c,0x73,0xec,0x94,0x0b,0xcc,0x49,0xa4,0x09,0x8c,0xae,0x8c,0x8e,0x74,0x4d,0xa5,0x10,0x53,0x8b,0x94,0xd0,0x31,0x84,0x3a,0xa7,0x54,0x2d,0x7c,0xd0,0x85,0x11,0x74,0xcf,0xa5,0xb4,0x43,0xeb,0x0a,0xa5,0x95,0x52,0x6c,0x0c,0x9d,0x71,0x23,0x68,0x23,0x88,0x23,0xa8,0x1b,0x88,0x1c,0x08,0x03,0xe6,0x03,0xc6,0x03,0xe6,0x03,0xa6,0x03,0x46,0x03,0x05,0x02,0xe5,0x23,0x68,0x33,0x89,0x22,0xe5,0x0a,0x84,0x02,0x83,0x2a,0xc5,0x12,0x84,0x4c,0x6b,0x03,0xc6,0x04,0x06,0x04,0x06,0x03,0xe6,0x0c,0x28
,0x0c,0x06,0x44,0xcb,0x4c,0xec,0x54,0xed,0x2c,0x69,0x0b,0xa5,0x74,0x8d,0x9c,0x6d,0x6c,0x2c,0x12,0x85,0x7c,0x6d,0x53,0x8a,0x4b,0x89,0x54,0x2c,0x4c,0x0b,0x33,0xa9,0x3c,0x09,0x1a,0x04,0x19,0x23,0x10,0xa1,0x10,0x81,0x10,0x81,0x10,0x81,0x10,0x81,0x10,0xa1,0x10,0x81,0x10,0x81,0x08,0xe2,0x13,0x27,0x84,0xb0,0x84,0x8f,0x33,0x68,0x7c,0x6d,0x7c,0x6d,0x94,0x2b,0xe5,0x4a,0xbc,0xaa,0x8c,0x8d,0x8c,0x6d,0x7c,0x6d,0xad,0x10,0x53,0xab,0x6c,0x0c,0x29,0x84,0x42,0x88,0x64,0x6e,0x7c,0xd0,0x95,0x73,0x74,0x8e,0x6b,0xed,0x7c,0xf0,0x5c,0x6d,0xbe,0x35,0x7c,0x8f,0x8d,0x10,0x0a,0xe6,0x74,0x8f,0x84,0x0d,0x7b,0xac,0x9d,0x73,0x0b,0xe7,0x03,0xe6,0x03,0xe6,0x44,0xcc,0x5d,0x0e,0x4b,0xea,0x54,0x4c,0x5c,0x4c,0x8c,0xce,0xac,0xae,0x5b,0xeb,0x3b,0x27,0xac,0xad,0x74,0x4c,0x4b,0xea,0x54,0xcc,0x3c,0xaa,0x34,0x8a,0x3c,0xec,0x0c,0x08
,0x0c,0x07,0x34,0xaa,0x3c,0xaa,0x44,0xcc,0x2c,0x6a,0x03,0xa5,0x6c,0x4b,0x9c,0xad,0x53,0xea,0x0a,0x65,0x73,0xcb,0x22,0x45,0x4b,0xa9,0x33,0x48,0x4b,0xeb,0x43,0xca,0x3b,0xc9,0x1a,0x25,0x21,0x03,0x10,0xa1,0x08,0x60,0x08,0x60,0x08,0x61,0x10,0x81,0x10,0x81,0x10,0x81,0x08,0x81,0x08,0xe1,0x1b,0x27,0x8c,0xb0,0x8c,0xd0,0x33,0x68,0x84,0x8f,0x8c,0x8f,0x8c,0x0b,0xdd,0x2a,0xbc,0x89,0x8d,0x2f,0x8d,0x10,0x8d,0x31,0x9d,0x92,0x43,0x89,0x74,0x6e,0x32,0x26,0x5b,0x4a,0x64,0x6d,0x95,0x52,0x9d,0x93,0x74,0x8f,0x63,0xac,0x7c,0xcf,0x74,0xae,0xb5,0xf4,0x63,0xac,0x85,0x11,0x02,0x84,0x64,0x0b,0x63,0x2a,0x6b,0x4a,0x84,0x8e,0x0b,0x87,0x03,0xe6,0x04,0x06,0x2c,0x8a,0x34,0xab,0x4c,0xab,0x54,0xed,0x54,0x8c,0x74,0x8d,0xb5,0x4f,0x4b,0x89,0x2a,0xc6,0x94,0x8d,0x53,0xaa,0x4c,0x0a,0x2c,0x49,0x45,0x0c,0x3c,0xab,0x44,0xac,0x0c,0x28
,0x0c,0x07,0x03,0xc6,0x03,0xe6,0x03,0xe6,0x03,0xc6,0x0b,0xa5,0x33,0xe9,0x12,0x03,0x02,0x63,0x02,0x43,0x0a,0x24,0x02,0x23,0x43,0xa9,0x02,0xa4,0x02,0x43,0x02,0xa5,0x03,0x04,0x12,0x24,0x21,0x24,0x10,0x81,0x08,0x61,0x08,0x60,0x08,0x61,0x08,0x81,0x10,0x81,0x08,0x61,0x08,0x81,0x08,0xe1,0x1b,0x07,0x6b,0xcc,0x53,0x08,0x33,0x68,0x63,0xca,0x52,0xe7,0x94,0x6b,0xe5,0x8b,0xbc,0xca,0x6c,0xcd,0x3c,0x4b,0x4c,0xcd,0x1b,0xe8,0x3c,0x0a,0x4b,0xeb,0x13,0x46,0x03,0x45,0x2c,0x4a,0x3c,0x6b,0x24,0x6a,0x5c,0x8d,0x84,0xd0,0x64,0x6e,0x33,0xea,0x7c,0xcf,0x5b,0xec,0x5c,0xad,0x0a,0xe5,0x1a,0x45,0x19,0xc4,0x19,0xa4,0x1a,0x24,0x03,0x66,0x03,0xe6,0x03,0xe7,0x03,0xe7,0x03,0xe6,0x03,0xe6,0x03,0xe6,0x24,0x28,0x33,0xe8,0x0a,0x43,0x02,0x43,0x02,0x64,0x12,0x23,0x0a,0x64,0x4c,0x4b,0x03,0xe6,0x04,0x06,0x04,0x07,0x03,0xe7,0x04,0x07
,0x0c,0x07,0x2c,0x8a,0x34,0xaa,0x24,0x48,0x1c,0x28,0x1b,0xc6,0x64,0x2b,0x9c,0x8d,0x64,0x2b,0x0a,0x64,0x74,0x4d,0x4b,0x69,0x43,0xa9,0x43,0xca,0x3b,0xa9,0x2b,0x48,0x23,0x87,0x0a,0x45,0x19,0x23,0x10,0x81,0x08,0x60,0x08,0x60,0x08,0x60,0x08,0x81,0x10,0x81,0x08,0x60,0x10,0x81,0x08,0xe1,0x1b,0x06,0x74,0x0c,0x84,0x4e,0x33,0x68,0x7c,0x4d,0x84,0xaf,0x63,0xab,0x9c,0xef,0x7c,0x4e,0x85,0x50,0x34,0x4a,0x5c,0xed,0x13,0xa7,0x13,0x26,0x24,0x09,0x13,0xe7,0x24,0x29,0x3c,0xcc,0x2c,0x4a,0x44,0xcc,0x1b,0x87,0x2b,0xc9,0x1b,0xa7,0x03,0x05,0x5c,0xcd,0x7d,0x50,0x85,0x92,0x5b,0xab,0x5a,0xe9,0x42,0x47,0x3a,0x07,0x4a,0x87,0x12,0xe6,0x03,0xa6,0x03,0x05,0x3c,0x2a,0x34,0xab,0x34,0x8b,0x2c,0x69,0x24,0x08,0x6c,0x4c,0x9c,0xad,0x53,0xca,0x2b,0x07,0x9c,0xad,0x6c,0x6c,0x4c,0x8a,0x3c,0xaa,0x2c,0x69,0x3c,0xab,0x04,0x07,0x0c,0x08
,0x0c,0x07,0x44,0xec,0x4c,0xcd,0x44,0xcc,0x44,0xcc,0x34,0x69,0x74,0x8d,0x9c,0x6b,0x6c,0x4c,0x12,0x44,0x63,0x8a,0x2a,0x45,0x53,0xaa,0x53,0xeb,0x5c,0x6e,0x43,0xcb,0x3b,0xe9,0x0a,0x44,0x19,0x03,0x10,0xa1,0x08,0x60,0x08,0x60,0x10,0x81,0x08,0x81,0x10,0x81,0x10,0x81,0x10,0x81,0x08,0xe1,0x1b,0x26,0x5c,0x2c,0x53,0xab,0x2b,0x47,0x54,0x0b,0x54,0x0b,0x2b,0x27,0x2b,0xa7,0x2b,0xe8,0x3c,0x4a,0x2c,0x4a,0x3c,0x8b,0x0b,0x06,0x03,0x65,0x03,0xe6,0x2c,0x6b,0x65,0x4f,0x55,0x0e,0x34,0xab,0x54,0xad,0x03,0x05,0x03,0xa6,0x03,0x05,0x0a,0xe6,0x1b,0xa8,0x1b,0x47,0x23,0x07,0x42,0xc8,0x52,0x89,0x3a,0x06,0x3a,0x06,0x5a,0xe9,0x12,0xe6,0x84,0xf0,0x54,0x8c,0x4c,0x8c,0x44,0xcd,0x75,0x90,0x3c,0xec,0x1c,0x28,0x74,0x4d,0xac,0xcd,0x5c,0x0a,0x3b,0x47,0x9c,0xad,0x74,0x2c,0x44,0x6a,0x44,0xcb,0x65,0x4e,0x5d,0x4e,0x0b,0xe8,0x0c,0x08
,0x0c,0x07,0x04,0x06,0x03,0xe6,0x03,0xe6,0x03,0xc6,0x0b,0xa5,0x33,0xc9,0x22,0xa5,0x0a,0x64,0x02,0x63,0x0a,0x03,0x02,0x03,0x3b,0x88,0x03,0x04,0x02,0xc4,0x02,0xa4,0x02,0xe4,0x0a,0x44,0x19,0x03,0x10,0xa1,0x08,0x60,0x08,0x60,0x08,0x61,0x10,0x81,0x10,0x81,0x08,0x61,0x10,0x81,0x00,0xc1,0x1a,0xc6,0x43,0x8a,0x5b,0xec,0x3b,0x49,0x3b,0xc9,0x2b,0x88,0x1b,0x07,0x33,0xe9,0x5c,0xcd,0x34,0x4a,0x03,0x87,0x02,0xe5,0x03,0x65,0x03,0xe6,0x03,0xe6,0x03,0xc7,0x03,0xe7,0x03,0xe7,0x0b,0x66,0x13,0x26,0x03,0xa7,0x03,0xa7,0x02,0xe5,0x2b,0x89,0x9d,0x52,0xa5,0x93,0x84,0xf1,0x53,0x4b,0x42,0x28,0x3a,0x27,0x3a,0x27,0x3a,0x27,0x1a,0xa6,0x94,0x8e,0x5c,0x2c,0x03,0x66,0x04,0x07,0x03,0xe6,0x03,0xe6,0x1c,0x47,0x2b,0xc9,0x1a,0xa5,0x02,0x64,0x02,0x84,0x1a,0xa5,0x12,0xe5,0x3c,0xcb,0x03,0xe6,0x03,0xe6,0x04,0x06,0x04,0x07,0x04,0x08
,0x04,0x06,0x0c,0x27,0x14,0x07,0x0b,0xc6,0x0b,0xe6,0x13,0xc6,0x53,0xea,0x7c,0x2b,0x4b,0xc9,0x12,0x85,0x6c,0x0c,0x1a,0x45,0x43,0xc9,0x23,0xc8,0x2b,0x68,0x1b,0x06,0x13,0x46,0x1a,0x25,0x19,0x03,0x10,0xa1,0x08,0x60,0x08,0x61,0x08,0x61,0x10,0x81,0x10,0x81,0x10,0x81,0x10,0x81,0x08,0xc1,0x1a,0xc5,0x1b,0x27,0x2b,0x68,0x23,0x07,0x54,0x8c,0x54,0x4c,0x13,0x88,0x1b,0xe9,0x24,0x29,0x13,0xe8,0x03,0x05,0x03,0x66,0x03,0xc6,0x03,0xa5,0x03,0xc6,0x03,0xa6,0x0b,0xc7,0x0b,0x06,0x12,0xc6,0x03,0x46,0x03,0xa7,0x03,0xa7,0x02,0xe5,0x2b,0x68,0x53,0x09,0x84,0xaf,0x53,0x29,0x53,0x4b,0x42,0x68,0x42,0x68,0x42,0x47,0x3a,0x27,0x1b,0x07,0x8c,0xd0,0x5c,0xcd,0x24,0x89,0x2c,0x8a,0x2c,0x8a,0x14,0x48,0x1c,0x28,0x54,0x0b,0x84,0x4c,0x3b,0x48,0x22,0xe6,0x7c,0x2c,0x4b,0xa9,0x3c,0x8a,0x2c,0x69,0x24,0x49,0x2c,0x8a,0x04,0x07,0x04,0x08
,0x04,0x27,0x5d,0x2e,0x5c,0xed,0x54,0xed,0x3c,0x8b,0x44,0x8b,0x84,0xce,0x9c,0x4b,0x74,0x4c,0x2b,0x07,0x63,0x69,0x2a,0x66,0x4b,0xea,0x54,0x8c,0x64,0xce,0x4b,0xca,0x64,0x8c,0x1a,0x04,0x19,0x23,0x08,0xa1,0x08,0x60,0x08,0x60,0x08,0x61,0x08,0x61,0x10,0x81,0x10,0x81,0x10,0x81,0x00,0xc1,0x13,0x26,0x13,0x05,0x02,0x63,0x02,0xe4,0x03,0x65,0x03,0x25,0x03,0x66,0x03,0x86,0x03,0xa6,0x02,0xe5,0x03,0x46,0x03,0x86,0x03,0x65,0x03,0x24,0x03,0x04,0x0b,0x05,0x43,0xaa,0x74,0x6e,0x4b,0xcb,0x02,0x84,0x03,0x25,0x03,0x66,0x02,0xe5,0x2b,0xa8,0x7d,0x10,0x95,0x72,0x8d,0x71,0x53,0x4a,0x4a,0x68,0x4a,0x48,0x4a,0x89,0x4a,0x69,0x13,0x27,0x3c,0x6b,0x2c,0x49,0x4c,0xed,0x5d,0x2e,0x5d,0x0e,0x3c,0xcc,0x1c,0x29,0x7c,0xae,0xac,0xab,0x6c,0x2b,0x43,0x68,0x9c,0x2b,0x7c,0x4c,0x44,0x6a,0x5c,0xed,0x4c,0xcc,0x75,0x8f,0x03,0xe7,0x04,0x28
,0x04,0x27,0x0c,0x08,0x14,0x49,0x14,0x28,0x1c,0x49,0x1b,0xc7,0x43,0xc9,0x4b,0x89,0x1a,0xa6,0x02,0x44,0x2a,0xa6,0x12,0xa5,0x3c,0x09,0x03,0x45,0x0a,0xe5,0x12,0xc5,0x02,0xe4,0x0a,0x24,0x21,0x44,0x08,0x81,0x08,0x60,0x08,0x61,0x08,0x81,0x10,0x81,0x08,0x81,0x10,0x81,0x10,0x81,0x00,0xe1,0x1b,0x26,0x12,0xa5,0x02,0xc4,0x03,0x65,0x03,0x86,0x03,0x05,0x03,0x66,0x03,0x46,0x02,0xe5,0x03,0x45,0x03,0xa6,0x03,0x65,0x02,0xe4,0x02,0x82,0x02,0x83,0x02,0x44,0x2a,0xc7,0x1a,0x66,0x22,0x86,0x02,0x43,0x02,0xc4,0x03,0x26,0x02,0xc5,0x1b,0xa8,0x34,0x4b,0x0a,0xc5,0x6d,0x0f,0x43,0x69,0x52,0xe9,0x4a,0xe9,0x4a,0xe9,0x4a,0xe9,0x3c,0x2b,0x65,0x50,0x6d,0xb1,0x0c,0x08,0x0c,0x08,0x0c,0x08,0x03,0xe7,0x1c,0x29,0x33,0xe9,0x43,0x88,0x0a,0xa5,0x02,0x84,0x43,0x28,0x1b,0x06,0x3c,0xab,0x03,0xe6,0x0c,0x07,0x0c,0x07,0x04,0x07,0x04,0x28
,0x04,0x27,0x13,0xe8,0x13,0xe8,0x0b,0xe7,0x0b,0xe7,0x13,0xa7,0x4b,0xc9,0x63,0xaa,0x2a,0xe6,0x02,0x44,0x3b,0x08,0x1a,0x85,0x3c,0x0a,0x0b,0x45,0x13,0x05,0x0a,0xa4,0x02,0xe4,0x0a,0x25,0x21,0x44,0x10,0x81,0x08,0x60,0x08,0x61,0x08,0x61,0x08,0x60,0x08,0x40,0x10,0x81,0x08,0x81,0x08,0xc2,0x1a,0x86,0x33,0x69,0x2b,0xc8,0x23,0xe8,0x03,0x05,0x03,0x47,0x02,0xe5,0x02,0xc4,0x03,0x26,0x03,0xa7,0x03,0xa6,0x03,0x86,0x0a,0xc5,0x32,0x86,0x63,0xaa,0x74,0x4e,0x7c,0x6f,0x74,0x6f,0x6c,0x0d,0x6b,0xec,0x22,0xa5,0x0a,0xe6,0x02,0xc6,0x2b,0xe9,0x5c,0xce,0x0b,0x26,0x85,0xb2,0x0b,0x46,0x23,0x47,0x5c,0x8c,0x1a,0xe5,0x0a,0x64,0x03,0xa7,0x0b,0xe8,0x0c,0x08,0x14,0x48,0x14,0x28,0x14,0x28,0x0c,0x07,0x1c,0x28,0x4c,0x0a,0x63,0xeb,0x22,0xe6,0x12,0xa5,0x5b,0xaa,0x33,0x47,0x3c,0x8b,0x14,0x07,0x0c,0x06,0x14,0x48,0x03,0xe7,0x04,0x28
,0x04,0x27,0x65,0x2e,0x5c,0xee,0x5d,0x0d,0x55,0x0d,0x34,0x29,0x8c,0xef,0x94,0x0c,0x7c,0x2c,0x12,0x65,0x6b,0xaa,0x32,0xa7,0x43,0xea,0x85,0x50,0x53,0xea,0x12,0x84,0x02,0xc5,0x0a,0x65,0x21,0x65,0x08,0x81,0x08,0x81,0x08,0x81,0x08,0x81,0x08,0x61,0x08,0x40,0x08,0x60,0x08,0x61,0x08,0xa1,0x1a,0xa5,0x33,0xca,0x4c,0x6d,0x54,0xad,0x44,0x2b,0x33,0xca,0x1b,0x28,0x4b,0xeb,0x44,0xcc,0x03,0xa7,0x03,0xa7,0x0b,0x87,0x74,0xae,0xbe,0x15,0xad,0x73,0x94,0xb1,0xbe,0x16,0xbe,0x16,0x84,0x2f,0xc6,0x16,0xbe,0x36,0x5c,0x2d,0x03,0x06,0x34,0x6b,0x55,0x2e,0x03,0x66,0x44,0x8d,0x02,0xe5,0x13,0xc7,0x1b,0xa7,0x03,0x86,0x03,0x86,0x03,0xe7,0x03,0xe7,0x04,0x07,0x55,0x0d,0x6d,0x4f,0x5d,0x0e,0x2c,0x8a,0x1c,0x27,0x8c,0x8e,0x9c,0x0b,0x74,0x4c,0x4b,0x89,0x9c,0x09,0x84,0x8d,0x44,0x6a,0x65,0x2e,0x44,0xca,0x44,0xcc,0x04,0x07,0x04,0x08
,0x04,0x27,0x0c,0x28,0x24,0x69,0x24,0x48,0x2c,0x69,0x1b,0xe7,0x4b,0xea,0x6b,0xeb,0x33,0x67,0x02,0xe4,0x3a,0xe7,0x1a,0x85,0x3c,0x0a,0x1b,0xc7,0x23,0xa6,0x02,0xc4,0x02,0xa4,0x0a,0x64,0x29,0x85,0x08,0x81,0x10,0x81,0x08,0x81,0x08,0x61,0x08,0x60,0x08,0x60,0x08,0x61,0x08,0x61,0x08,0xc1,0x13,0x26,0x2b,0xa9,0x2b,0xc9,0x4c,0x2b,0x75,0x10,0x5c,0x8e,0x23,0x28,0x64,0x4e,0x2c,0x49,0x03,0xc6,0x03,0x86,0x1b,0x87,0x7c,0x8e,0xa5,0x73,0x8c,0x90,0x9d,0x32,0xbe,0x16,0xb5,0xb5,0x9d,0x12,0xa5,0x53,0xbe,0x36,0x6c,0x8d,0x13,0xa7,0x3c,0x8b,0x55,0x0d,0x3c,0x2a,0x2b,0xea,0x1b,0x47,0x34,0x4a,0x1b,0xa8,0x03,0x87,0x03,0x87,0x03,0xa7,0x03,0xa7,0x03,0xc7,0x14,0x48,0x14,0x48,0x24,0x89,0x14,0x27,0x1c,0x28,0x3b,0xc9,0x64,0x0b,0x23,0x27,0x13,0x05,0x74,0x0a,0x33,0x68,0x3c,0xab,0x0c,0x07,0x24,0x69,0x0c,0x48,0x04,0x07,0x0c,0x08
,0x04,0x27,0x04,0x06,0x04,0x06,0x03,0xe6,0x03,0xc6,0x0b,0xa6,0x44,0x49,0x43,0xc8,0x23,0xc8,0x03,0x46,0x22,0xc6,0x0a,0xc4,0x34,0x4a,0x03,0x65,0x03,0x44,0x02,0xc3,0x02,0x83,0x0a,0x45,0x21,0x44,0x08,0x81,0x10,0x81,0x10,0x81,0x10,0x81,0x08,0x81,0x08,0x61,0x08,0x61,0x08,0x61,0x08,0xc1,0x1b,0x26,0x73,0xec,0x7c,0x6f,0x6c,0x4e,0x8c,0xd0,0x43,0xaa,0x3b,0x8a,0xa5,0x73,0x4c,0x4d,0x03,0xc7,0x1b,0x87,0x8c,0xd0,0x9d,0x11,0xad,0x94,0xad,0xb4,0xad,0xb4,0xa5,0x33,0x9c,0xd1,0xb5,0xf5,0xbe,0x16,0xbe,0x15,0x9d,0x52,0x6c,0xaf,0x3c,0x4b,0x65,0x0e,0xad,0xb3,0x9d,0x71,0x5c,0x2c,0xbe,0x14,0x5c,0xce,0x03,0xa7,0x03,0xc7,0x03,0xa7,0x03,0xa7,0x03,0x87,0x03,0x86,0x03,0xe6,0x04,0x07,0x03,0xe7,0x1c,0x28,0x34,0x69,0x44,0x09,0x13,0xa6,0x0b,0xa6,0x4b,0xe9,0x23,0xa7,0x3c,0xcb,0x03,0xe6,0x03,0xe6,0x04,0x07,0x04,0x07,0x0c,0x28
,0x04,0x27,0x4c,0xcb,0x65,0x4e,0x65,0x0e,0x65,0x2e,0x0b,0xc6,0x95,0x70,0x9c,0xad,0x85,0x2f,0x13,0x87,0x5b,0x68,0x33,0x48,0x4c,0x8b,0x54,0xac,0x5c,0xad,0x4c,0x0a,0x22,0xe6,0x0a,0x65,0x29,0xa5,0x10,0xa2,0x08,0x61,0x08,0x61,0x08,0x61,0x10,0x81,0x10,0x81,0x08,0x61,0x08,0x61,0x08,0xc1,0x1b,0x07,0x53,0x2a,0x3a,0xa8,0x5b,0xab,0x63,0x09,0x64,0x4e,0x7c,0xcf,0xc5,0xf3,0x3b,0xc9,0x03,0xc6,0x23,0x88,0xa5,0x32,0xa5,0x32,0xad,0x94,0xad,0x94,0xad,0x94,0x94,0xd1,0x7c,0x0e,0x94,0xd1,0xad,0x93,0xbd,0xf5,0xc6,0x56,0x8d,0x30,0x03,0x86,0x85,0x70,0xb5,0xb1,0xad,0xb2,0x53,0xeb,0x73,0x8a,0x4b,0xea,0x6d,0x0f,0x64,0xcf,0x34,0x4a,0x03,0x86,0x03,0x86,0x4c,0xab,0x75,0x4f,0x6d,0x4f,0x6d,0x6f,0x24,0x48,0x8d,0x4f,0x94,0x2a,0x75,0x2e,0x54,0xab,0xa4,0x4c,0x8d,0x0f,0x3c,0xab,0x5d,0x2d,0x64,0xed,0x6d,0x6f,0x3c,0xec,0x0c,0x28
,0x04,0x27,0x34,0x6a,0x44,0xcb,0x3c,0xab,0x3c,0xcb,0x0b,0xc6,0x6c,0xed,0xad,0xf3,0x5c,0xee,0x1c,0x08,0x7c,0xad,0x3b,0xc9,0x44,0x6b,0x3c,0x8a,0x2b,0xe8,0x33,0xa8,0x1b,0x26,0x0a,0x65,0x29,0xa5,0x10,0xa1,0x08,0x60,0x08,0x40,0x08,0x60,0x10,0x81,0x10,0x81,0x08,0x61,0x08,0x81,0x08,0xc1,0x1b,0x06,0x6c,0x0c,0x63,0xcc,0x6c,0x2d,0x84,0x8e,0x5c,0x6d,0x64,0x6d,0xad,0x93,0x4c,0x6b,0x03,0xe6,0x23,0x87,0xb5,0xb4,0x94,0xf1,0xad,0xb4,0xad,0xb5,0xa5,0x74,0xa5,0x74,0x9d,0x12,0xa5,0x53,0xb5,0x74,0xb5,0xf5,0xb5,0x94,0x95,0x72,0x03,0xc6,0x44,0x8b,0xad,0xd2,0xad,0xd2,0x74,0xad,0x9c,0xd0,0x54,0xad,0x1c,0x49,0x24,0x4a,0x0c,0x27,0x04,0x06,0x04,0x07,0x24,0x6a,0x3c,0xcc,0x2c,0x8a,0x44,0xec,0x1c,0x28,0x64,0xed,0x9d,0x30,0x44,0x8c,0x2c,0x29,0xa5,0x0f,0x5c,0x8c,0x3c,0xab,0x44,0xca,0x2c,0x49,0x4d,0x0c,0x2c,0x8a,0x0c,0x28
,0x04,0x27,0x03,0xc6,0x03,0xe7,0x04,0x07,0x03,0xe6,0x03,0xc6,0x4c,0xac,0x4c,0x6b,0x44,0xab,0x44,0xab,0x3c,0x2a,0x3c,0x4a,0x2c,0x29,0x03,0xa5,0x03,0x65,0x03,0x24,0x03,0x04,0x1a,0xa6,0x29,0x85,0x10,0xa2,0x08,0x81,0x08,0x81,0x08,0x61,0x10,0x81,0x10,0x81,0x08,0x61,0x08,0x81,0x08,0xe2,0x2b,0x47,0x5c,0x8c,0x54,0x4b,0x64,0xcd,0x64,0xad,0x34,0x09,0x3c,0x4a,0x5c,0x8c,0x34,0x4a,0x03,0xa6,0x0b,0xa6,0x2b,0xe9,0x8d,0x10,0xb5,0xb4,0xb5,0xb4,0xad,0xb4,0xad,0x94,0xad,0xb4,0xad,0x94,0xb5,0xb5,0xbd,0xf5,0x7c,0xef,0x1b,0xc8,0x03,0xe6,0x0c,0x07,0x64,0xee,0x64,0xad,0x4c,0xcd,0x6c,0xef,0x44,0xac,0x04,0x06,0x04,0x07,0x04,0x07,0x04,0x07,0x03,0xe7,0x04,0x28,0x04,0x07,0x04,0x07,0x04,0x27,0x0c,0x28,0x55,0x0d,0x4c,0xcc,0x44,0xcc,0x4c,0xcc,0x4c,0xac,0x44,0xcc,0x24,0x8a,0x04,0x07,0x04,0x07,0x04,0x07,0x03,0xe7,0x0c,0x28
,0xbe,0xd8,0xb6,0x97,0xae,0x77,0xae,0x77,0xae,0x77,0xa6,0x76,0xa6,0x56,0xa6,0x56,0xa6,0x56,0xa6,0x56,0xa6,0x56,0xa6,0x35,0xa6,0x56,0xa6,0x56,0xa6,0x35,0xa6,0x35,0xa6,0x35,0x9d,0x73,0x18,0xe2,0x10,0xa1,0x10,0x81,0x10,0x81,0x10,0x61,0x10,0x61,0x10,0x81,0x10,0xa1,0x18,0xc2,0x31,0xe6,0xc6,0xb8,0xae,0x56,0xa6,0x56,0xa6,0x56,0xa6,0x36,0xa6,0x36,0xa6,0x56,0xa6,0x56,0xa6,0x56,0xa6,0x76,0xa6,0x56,0xae,0x77,0xd6,0xd9,0xf7,0x9d,0xef,0x5c,0xef,0x7c,0xef,0x7c,0xef,0x7c,0xef,0x7c,0xf7,0x9d,0xef,0x5c,0xd6,0xfa,0xa6,0x56,0xa6,0x56,0xa6,0x56,0xa6,0x76,0xa6,0x76,0xa6,0x76,0xa6,0x76,0xa6,0x76,0xae,0x76,0xa6,0x77,0xa6,0x56,0x9e,0x76,0x9e,0x76,0x9e,0x76,0xa6,0x76,0xa6,0x76,0x9e,0x76,0x9e,0x56,0x9e,0x56,0x9e,0x55,0x9e,0x55,0x9e,0x55,0x9e,0x56,0x9e,0x55,0x9e,0x56,0xa6,0x56,0xa6,0x56,0xa6,0x76,0xae,0x77,0xae,0x77
,0xff,0xff,0xff,0xff,0xff,0xff,0xff,0xff,0xff,0xff,0xff,0xff,0xff,0xff,0xff,0xff,0xff,0xff,0xff,0xff,0xff,0xff,0xff,0xff,0xff,0xff,0xff,0xff,0xff,0xff,0xff,0xff,0xff,0xff,0xff,0xdf,0x7b,0xcd,0x31,0x85,0x29,0x64,0x10,0x81,0x10,0xa2,0x29,0x64,0x39,0xe6,0xce,0x58,0xf7,0xbe,0xf7,0xbe,0xff,0xff,0xff,0xff,0xff,0xff,0xff,0xff,0xff,0xff,0xff,0xff,0xff,0xff,0xff,0xff,0xff,0xff,0xff,0xff,0xff,0xff,0xff,0xff,0xff,0xff,0xff,0xff,0xff,0xff,0xff,0xff,0xff,0xff,0xff,0xff,0xff,0xff,0xff,0xff,0xff,0xff,0xff,0xff,0xff,0xff,0xff,0xff,0xff,0xff,0xff,0xff,0xff,0xff,0xff,0xff,0xff,0xff,0xff,0xff,0xff,0xff,0xff,0xff,0xff,0xff,0xff,0xff,0xff,0xff,0xff,0xff,0xff,0xff,0xff,0xff,0xff,0xff,0xff,0xff,0xff,0xff,0xff,0xff,0xff,0xff,0xff,0xff,0xff,0xff,0xff,0xff,0xff,0xff,0xff,0xff,0xff,0xff,0xff,0xff,0xff,0xff,0xff,0xff
,0xff,0xff,0xff,0xff,0xff,0xff,0xff,0xff,0xff,0xff,0xff,0xff,0xff,0xff,0xff,0xff,0xff,0xff,0xff,0xff,0xff,0xff,0xff,0xff,0xff,0xff,0xff,0xff,0xff,0xff,0xff,0xff,0xff,0xff,0xff,0xff,0x84,0x0e,0x31,0xa5,0x29,0x44,0x08,0x81,0x08,0x81,0x29,0x64,0x3a,0x07,0xd6,0x99,0xff,0xff,0xff,0xff,0xff,0xff,0xff,0xff,0xff,0xff,0xff,0xff,0xff,0xff,0xff,0xff,0xff,0xff,0xff,0xff,0xff,0xff,0xff,0xff,0xff,0xff,0xff,0xff,0xff,0xff,0xff,0xff,0xff,0xff,0xff,0xff,0xff,0xff,0xff,0xff,0xff,0xff,0xff,0xff,0xff,0xff,0xff,0xff,0xff,0xff,0xff,0xff,0xff,0xff,0xff,0xff,0xff,0xff,0xff,0xff,0xff,0xff,0xff,0xff,0xff,0xff,0xff,0xff,0xff,0xff,0xff,0xff,0xff,0xff,0xff,0xff,0xff,0xff,0xff,0xff,0xff,0xff,0xff,0xff,0xff,0xff,0xff,0xff,0xff,0xff,0xff,0xff,0xff,0xff,0xff,0xff,0xff,0xff,0xff,0xff,0xff,0xff,0xff,0xff,0xff,0xff,0xff,0xff
,0xff,0xff,0xff,0xff,0xff,0xff,0xff,0xff,0xff,0xff,0xff,0xff,0xff,0xff,0xff,0xff,0xff,0xff,0xff,0xff,0xff,0xff,0xff,0xff,0xff,0xff,0xff,0xff,0xff,0xff,0xff,0xff,0xff,0xff,0xff,0xff,0x84,0x0f,0x31,0xa5,0x29,0x44,0x08,0x81,0x10,0xa1,0x29,0x64,0x3a,0x06,0xd6,0x99,0xff,0xff,0xff,0xff,0xff,0xff,0xff,0xff,0xff,0xff,0xff,0xff,0xff,0xff,0xff,0xff,0xff,0xff,0xff,0xff,0xff,0xff,0xff,0xff,0xff,0xff,0xff,0xff,0xff,0xff,0xff,0xff,0xff,0xff,0xff,0xff,0xff,0xff,0xff,0xff,0xff,0xff,0xff,0xff,0xff,0xff,0xff,0xff,0xff,0xff,0xff,0xff,0xff,0xff,0xff,0xff,0xff,0xff,0xff,0xff,0xff,0xff,0xff,0xff,0xff,0xff,0xff,0xff,0xff,0xff,0xff,0xff,0xff,0xff,0xff,0xff,0xff,0xff,0xff,0xff,0xff,0xff,0xff,0xff,0xff,0xff,0xff,0xff,0xff,0xff,0xff,0xff,0xff,0xff,0xff,0xff,0xff,0xff,0xff,0xff,0xff,0xff,0xff,0xff,0xff,0xff,0xff,0xff
,0xff,0xff,0xff,0xff,0xff,0xff,0xff,0xff,0xff,0xff,0xff,0xff,0xff,0xff,0xff,0xff,0xff,0xff,0xff,0xff,0xff,0xff,0xff,0xff,0xff,0xff,0xff,0xff,0xff,0xff,0xff,0xff,0xff,0xff,0xff,0xff,0x7c,0x0e,0x31,0xa5,0x29,0x44,0x10,0xa1,0x10,0xa2,0x29,0x64,0x42,0x06,0xd6,0x99,0xff,0xff,0xff,0xff,0xff,0xff,0xff,0xff,0xff,0xff,0xff,0xff,0xff,0xff,0xff,0xff,0xff,0xff,0xff,0xff,0xff,0xff,0xff,0xff,0xff,0xff,0xff,0xff,0xff,0xff,0xff,0xff,0xff,0xff,0xff,0xff,0xff,0xff,0xff,0xff,0xff,0xff,0xff,0xff,0xff,0xff,0xff,0xff,0xff,0xff,0xff,0xff,0xff,0xff,0xff,0xff,0xff,0xff,0xff,0xff,0xff,0xff,0xff,0xff,0xff,0xff,0xff,0xff,0xff,0xff,0xff,0xff,0xff,0xff,0xff,0xff,0xff,0xff,0xff,0xff,0xff,0xff,0xff,0xff,0xff,0xff,0xff,0xff,0xff,0xff,0xff,0xff,0xff,0xff,0xff,0xff,0xff,0xff,0xff,0xff,0xff,0xff,0xff,0xff,0xff,0xff,0xff,0xff
,0xff,0xff,0xff,0xff,0xff,0xff,0xff,0xff,0xff,0xff,0xff,0xff,0xff,0xff,0xff,0xff,0xff,0xff,0xff,0xff,0xff,0xff,0xff,0xff,0xff,0xff,0xff,0xff,0xff,0xff,0xff,0xff,0xff,0xff,0xff,0xff,0x8c,0x50,0x39,0xe6,0x31,0x85,0x18,0xe2,0x21,0x03,0x31,0xa5,0x4a,0x47,0xd6,0xba,0xff,0xff,0xff,0xff,0xff,0xff,0xff,0xff,0xff,0xff,0xff,0xff,0xff,0xff,0xff,0xff,0xff,0xff,0xff,0xff,0xff,0xff,0xff,0xff,0xff,0xff,0xff,0xff,0xff,0xff,0xff,0xff,0xff,0xff,0xff,0xff,0xff,0xff,0xff,0xff,0xff,0xff,0xff,0xff,0xff,0xff,0xff,0xff,0xff,0xff,0xff,0xff,0xff,0xff,0xff,0xff,0xff,0xff,0xff,0xff,0xff,0xff,0xff,0xff,0xff,0xff,0xff,0xff,0xff,0xff,0xff,0xff,0xff,0xff,0xff,0xff,0xff,0xff,0xff,0xff,0xff,0xff,0xff,0xff,0xff,0xff,0xff,0xff,0xff,0xff,0xff,0xff,0xff,0xff,0xff,0xff,0xff,0xff,0xff,0xff,0xff,0xff,0xff,0xff,0xff,0xff,0xff,0xff

};

uint8_t Data[]={ };
/* USER CODE END PTD */

I2C_HandleTypeDef hi2c2;

SD_HandleTypeDef hsd1;

SPI_HandleTypeDef hspi1;
SPI_HandleTypeDef hspi2;
SPI_HandleTypeDef hspi4;

TIM_HandleTypeDef htim3;

UART_HandleTypeDef huart3;

SRAM_HandleTypeDef hsram1;

void SystemClock_Config(void);
static void MX_GPIO_Init(void);
static void MX_SPI1_Init(void);
static void MX_USART3_UART_Init(void);
static void MX_FMC_Init(void);
static void MX_TIM3_Init(void);
static void MX_SPI2_Init(void);
static void MX_I2C2_Init(void);
static void MX_SDMMC1_SD_Init(void);
static void MX_SPI4_Init(void);

/* USER CODE BEGIN 0 */
/*
void print(char *buf){
	HAL_UART_Transmit(&huart3, (uint8_t*)buf , strlen(buf), 0xFFFF);
}
*/
void HAL_GPIO_EXTI_Callback(uint16_t GPIO_Pin){

	if(GPIO_Pin == GPIO_PIN_11){
		  LCD_courbe =1;

	}
	if(GPIO_Pin == GPIO_PIN_4){
		  LCD_courbe =0;

	}
}
//snprintf(buf, 100, "\n\rSTATUS now: %#.2x\n", tmp[0]);
//print(buf);

/* USER CODE END 0 */

int main(void)
{

  /* MCU Configuration--------------------------------------------------------*/

  /* Reset of all peripherals, Initializes the Flash interface and the Systick. */
  HAL_Init();

  /* Configure the system clock */
  SystemClock_Config();

  /* Initialize all configured peripherals */
  MX_GPIO_Init();
  MX_SPI1_Init();
  MX_USART3_UART_Init();
  MX_FMC_Init();
  MX_TIM3_Init();
  MX_SPI2_Init();
  MX_I2C2_Init();
  MX_SDMMC1_SD_Init();
  MX_SPI4_Init();
  MX_FATFS_Init();
  /* USER CODE BEGIN 2 */
  BSP_LED_Init(LED1);
  BSP_LED_Init(LED3);

#ifdef DDS_ON
  AD9833reset();
  AD9833setFreq(100.0);
  AD9833mode(AD_SQUARE);
#endif

#ifdef ad1256

  //************************************************************************************
  // Define the ADC
  //************************************************************************************

    ADS125X_t  my_ads1256 ;

    my_ads1256.hspix      = &hspi2 ;
    my_ads1256.vref       = ADS125X_VREF;
    my_ads1256.pga        = 1;
  // my_ads1256.convFactor = ADS125X_ConvFactor;
    //my_ads1256.oscFreq    = ADS125X_OSC_FREQ;
    my_ads1256.csPort     = GPIOB;
    my_ads1256.csPin      = GPIO_PIN_1;
    my_ads1256.drdyPort   = GPIOB;
    my_ads1256.drdyPin    = GPIO_PIN_2;

  //************************************************************************************
  // initialize the ADC
  //************************************************************************************
    uint8_t buffer_en = 1;

    ADS125X_Init( &my_ads1256 , &hspi2, ADS125X_DRATE_30000SPS, ADS125X_PGA1, buffer_en);
    int8_t channel = 0x10; //AIN0 pour AIN 1 change to 0001 0000 :)

    //ADS125X_Channel_Set(&my_ads1256, channel); // set channel
    ADS125X_ChannelDiff_Set(&my_ads1256, 0x00, 0x08);
    float data_ads1256 = 0;

    print("\n\r getting to the while ");
    uint8_t spiRx[3] = {0,0,0};

    ADS125X_ADC_setcontinuous (&my_ads1256);

    for(int i =0;i<300;i++){
    	data_ads1256 =  ADS125X_ADC_ReadVolt (&my_ads1256); // read data voltage
    }
#endif

#ifdef timer3
  HAL_TIM_Base_Start(&htim3);
#endif

#ifdef TFT3START
  HAL_GPIO_WritePin(GPIOE, GPIO_PIN_1, GPIO_PIN_RESET);
  HAL_Delay(10);
  HAL_GPIO_WritePin(GPIOE, GPIO_PIN_1, GPIO_PIN_SET); // RST � 1 pour valider les envois
  ILI9341_Init();
#endif

#ifdef TFT3START
#ifdef Fake_rainbow
  //ILI9341_Fill(COLOR_OLIVE);
  ILI9341_Fill_Rect(0,0, 50,480, COLOR_OLIVE) ;
  ILI9341_Fill_Rect(50,0, 100,480, COLOR_DGRAY) ;
  ILI9341_Fill_Rect(100,0, 150,480, COLOR_GREEN) ;
  ILI9341_Fill_Rect(150,0, 200, 480, COLOR_MAGENTA) ;

  ILI9341_Fill_Rect(200,0, 250, 480, COLOR_OLIVE) ;
  ILI9341_Fill_Rect(250,0, 300, 480, COLOR_DGRAY) ;
  ILI9341_Fill_Rect(300,0, 350, 480, COLOR_GREEN) ;
  ILI9341_Fill_Rect(350,0, 400, 480, COLOR_MAGENTA) ;
  ILI9341_Fill_Rect(400,0, 450, 480, COLOR_OLIVE) ;

  ILI9341_Fill_Rect(200,0, 250, 480, COLOR_OLIVE) ;
  ILI9341_Fill_Rect(250,0, 300, 480, COLOR_DGRAY) ;

  ILI9341_Fill_Rect(0,100, 320, 200, COLOR_MAGENTA) ;
  ILI9341_Fill_Rect(0,200, 320, 300, COLOR_OLIVE) ;
#endif
#endif

#ifdef TFT3START
#ifdef Check_Driver
  uint8_t val9[10]={0,0,0,0,0,0,0,0,0,0};
  ILI94XX_readRegister(0xD3, 4, val9);
  snprintf(buf, 100, "\n \r %d, %d, %d, %d,%d ,%d\r\n", val9[0],val9[1],val9[2],val9[3],val9[4],val9[5]);
  print(buf);
#endif
#endif
  /* USER CODE END 2 */

  /* Infinite loop */
  /* USER CODE BEGIN WHILE */
#ifdef TFT3START
#ifdef Courbes_axe_spectre
  ILI9341_drawLine(470, 10, 470, 200, COLOR_OLIVE);
  ILI9341_drawLine(469, 10, 469, 200, COLOR_OLIVE);
  ILI9341_drawLine(468, 10, 468, 200, COLOR_OLIVE);
//#else
//	  Courbes_axe_waveforme
  ILI9341_drawLine(10, 10, 10, 200, COLOR_RED);
  ILI9341_drawLine(11, 10, 11, 200, COLOR_RED);
  ILI9341_drawLine(12, 10, 12, 200, COLOR_RED);
#endif
#endif

/*
  ILI9341_drawLine(470, 200, 10, 200, COLOR_BLACK);
  ILI9341_drawLine(470, 199, 10, 199, COLOR_BLACK);
  ILI9341_drawLine(470, 198, 10, 198, COLOR_BLACK);
*/

  initialiser();
  char deb[]="Frequence   Debit   Temperature ";
  ILI9341_printText(deb, 40 , 230, COLOR_WHITE, COLOR_BLACK, 2);
  int i =0;
  int data=0;
  char freq_m[200];
  float32_t data2;

/******************************GEN********************************************/
/******************************GEN********************************************/
/******************************GEN********************************************/
  float32_t testInput_f32[NPT];
  float32_t testOutput_f32[NPT];
  float32_t  testOutput[NPT];
  for(int i =0;i< data_len;i++){
	  testInput_f32[i]= 0;
	  testOutput_f32[i]= 0;
	  testOutput[i]= 0;
  }

#ifdef Generate_OutLoop

  for(int i =0;i< data_len;i++){
	  data2 =  1000*arm_sin_f32(PI2*i*50.0/Fs)+
              2000*arm_sin_f32(PI2*i*500.0/Fs)+
              3000*arm_sin_f32(PI2*i*1550.0/Fs);//1000*((sin(2*3.14*i*50.0/Fs))*120);
	  //empiler2((int)data2);
	  testInput_f32[i]= data2;
  }

#endif

/******************************FFT Variables********************************************/
/***************************************************************************************/
  arm_rfft_fast_instance_f32 S;
  arm_rfft_fast_init_f32(&S, fftSize);

  i= (NPT/2) - 2;
  int m =0;
  int pos=0;

/******************************FFT Variables********************************************/
/***************************************************************************************/

#ifdef Correlate
/******************************Correlation********************************************/
/***************************************************************************************/
  float32_t pSrcA[NPT];
  uint32_t  srcALen = NPT;
  float32_t pSrcB[NPT];
  uint32_t  srcBLen = NPT;
  float32_t pDst[2*NPT];

  for(int i =0; i< NPT*2 ;i++){
	  pSrcA[i]= 0;
	  pSrcB[i]= 0;
	  pDst[i]= 0;
  }

  for(int i =0;i< NPT;i++){
	  data2 =  //1000*arm_sin_f32(PI2*i*50.0/Fs)+
              //2000*arm_sin_f32(PI2*i*500.0/Fs)+
              1*arm_sin_f32(PI2*i*50.0/Fs);//1000*((sin(2*3.14*i*50.0/Fs))*120);
	  //empiler2((int)data2);
	  pSrcA[i]= data2;
  }
  for(int i =0;i< NPT;i++){
	  data2 =  //1000*arm_sin_f32(PI2*i*50.0/Fs)+
              //2000*arm_sin_f32(PI2*i*500.0/Fs)+
              1*arm_sin_f32(PI2*i*50.0/Fs + PI2/4);//1000*((sin(2*3.14*i*50.0/Fs))*120);
	  //empiler2((int)data2);
	  pSrcB[i]= data2;
  }
  arm_correlate_f32 (pSrcA, srcALen, pSrcB, srcBLen, pDst);
/*
 for(int i =0;i< NPT-25;i++){
	  snprintf(buf, 100, "%d \r\n",(int)pDst[i]);
	  print(buf);
   }
*/

  for(int i = NPT-25;i< NPT*2-50;i++){
	  snprintf(buf, 100, "%d \r\n",(int)pDst[i]);
	  print(buf);
   }

/******************************Correlation********************************************/
/***************************************************************************************/
#endif

#ifdef ads1115

  /**********************************************************************************************/
  /**********************************************************************************************/
  /**********************************************************************************************/
  /*********************************************adc begin*************************************************/

  	  ADSwrite[0] = 0x01;
  	  int i =0;
  	  		switch(i){
  	  			case(0):
  	  				ADSwrite[1] = 0xC1; //11000001
  	  			break;
  	  			case(1):
  	  				ADSwrite[1] = 0xD1; //11010001
  	  			break;
  	  			case(2):
  	  				ADSwrite[1] = 0xE1;
  	  			break;
  	  			case(3):
  	  				ADSwrite[1] = 0xF1;
  	  			break;
  	  		}
  	  		ADSwrite[1] = 0xC7;
  	  		ADSwrite[2] = 0x83; //10000011 LSB

  	  HAL_I2C_Master_Transmit(&hi2c1, ADS1115_ADDRESS << 1, ADSwrite, 3, 100);
  	  ADSwrite[0] = 0x00;
  	  HAL_I2C_Master_Transmit(&hi2c1, ADS1115_ADDRESS << 1 , ADSwrite, 1 ,100);
  	  HAL_Delay(20);

  	  HAL_I2C_Master_Receive(&hi2c1, ADS1115_ADDRESS <<1, ADSwrite, 2, 100);
  	  reading = (ADSwrite[0] << 8 | ADSwrite[1] );
  	  if(reading < 0) {
  		  reading = 0;
  	  }
  	  voltage[i] = reading ;//* voltageConv;
  	  uint16_t voltage2 = (int)voltage[0];
  	  itoa((voltage2), buf, 10);
  	  print(buf);
  	  print("\n\r");

   }

  /**********************************************************************************************/
  /**********************************************************************************************/
  /**********************************************************************************************/
  /*********************************************adc end *************************************************/
#endif

#ifdef Ad760
  int a,b,c,busytest;
  uint16_t value1;
  uint16_t value2;
  uint16_t value3;
  uint16_t value4;
  float valuee;
  int compt=0;
  float t_values[300];
  float tab[300][2];

  //compteur a 0 pour echantilloner simultanement le nb de voies desire
  	int cpt=0;
  	//Reset AD7606
  	HAL_GPIO_WritePin(GPIOD,rst_ad7606_Pin,GPIO_PIN_SET);
  	HAL_Delay(1);
  	HAL_GPIO_WritePin(GPIOD,rst_ad7606_Pin,GPIO_PIN_RESET);

  	//no Oversampling os0/os1/os2 = 0
  	HAL_GPIO_WritePin(GPIOA,osc1_ad7606_Pin,GPIO_PIN_RESET);
  	HAL_GPIO_WritePin(GPIOA,osc2_ad7606_Pin,GPIO_PIN_RESET);
  	HAL_GPIO_WritePin(GPIOA,osc3_ad7606_Pin,GPIO_PIN_RESET);

  	//Bloc conversion analogique-numerique
int bb =0;

	while(compt<300){

		HAL_GPIO_WritePin(GPIOA,cvab_ad7606_Pin,GPIO_PIN_SET);
		HAL_Delay(1);
		for (cpt=0;cpt<1;cpt++) { //mettre cpt a 8 pour conversion simultanee

			HAL_GPIO_WritePin(GPIOA,rd_cs_ad7606_Pin,GPIO_PIN_RESET);
			HAL_Delay(1);
			value1=HAL_GPIO_ReadPin(d15_GPIO_Port,d15_Pin)<<15|HAL_GPIO_ReadPin(d14_GPIO_Port,d14_Pin)<<14|HAL_GPIO_ReadPin(d13_GPIO_Port,d13_Pin)<<13|HAL_GPIO_ReadPin(d12_GPIO_Port,d12_Pin)<<12;
			value2=HAL_GPIO_ReadPin(d11_GPIO_Port,d11_Pin)<<11|HAL_GPIO_ReadPin(d10_GPIO_Port,d10_Pin)<<10|HAL_GPIO_ReadPin(d9_GPIO_Port,d9_Pin)<<9|HAL_GPIO_ReadPin(d8_GPIO_Port,d8_Pin)<<8;
			value3=HAL_GPIO_ReadPin(d7_GPIO_Port,d7_Pin)<<7|HAL_GPIO_ReadPin(d6_GPIO_Port,d6_Pin)<<6|HAL_GPIO_ReadPin(d5_GPIO_Port,d5_Pin)<<5|HAL_GPIO_ReadPin(d4_GPIO_Port,d4_Pin)<<4;
			value4=HAL_GPIO_ReadPin(d3_GPIO_Port,d3_Pin)<<3|HAL_GPIO_ReadPin(d2_GPIO_Port,d2_Pin)<<2|HAL_GPIO_ReadPin(d1_GPIO_Port,d1_Pin)<<1|HAL_GPIO_ReadPin(d0_GPIO_Port,d0_Pin)<<0;
			uint16_t value=value1|value2|value3|value4;
			valuee= ((float)value *10)/32768; // valeure convertie
			//tab[compt][cpt]=valuee;
			t_values[compt]= valuee;
			HAL_GPIO_WritePin(GPIOA,rd_cs_ad7606_Pin,GPIO_PIN_SET);
		}

		HAL_GPIO_WritePin(GPIOA,cvab_ad7606_Pin,GPIO_PIN_RESET);
		compt++;
	}

for(int i=0;i<200;i++){
	  snprintf(buf, 100, "%f \r\n", t_values[compt]);
	   print(buf);
}

#endif

#ifdef Scroll
scrollinit();
#endif

int max =0;
LCD_courbe =3;
while (1)
{

	  HAL_GPIO_WritePin(GPIOE, GPIO_PIN_1, GPIO_PIN_RESET);
	  HAL_Delay(10);
	  HAL_GPIO_WritePin(GPIOE, GPIO_PIN_1, GPIO_PIN_SET); // RST � 1 pour valider les envois

	  ILI9341_Init();
	  ILI9341_Fill(COLOR_OLIVE);

	#ifdef Fake_rainbow
	  ILI9341_Fill_Rect(0,0, 50,480, COLOR_OLIVE) ;
	  ILI9341_Fill_Rect(50,0, 100,480, COLOR_DGRAY) ;
	  ILI9341_Fill_Rect(100,0, 150,480, COLOR_GREEN) ;
	  ILI9341_Fill_Rect(150,0, 200, 480, COLOR_MAGENTA) ;

	  ILI9341_Fill_Rect(200,0, 250, 480, COLOR_OLIVE) ;
	  ILI9341_Fill_Rect(250,0, 300, 480, COLOR_DGRAY) ;
	  ILI9341_Fill_Rect(300,0, 350, 480, COLOR_GREEN) ;
	  ILI9341_Fill_Rect(350,0, 400, 480, COLOR_MAGENTA) ;
	  ILI9341_Fill_Rect(400,0, 450, 480, COLOR_OLIVE) ;

	  ILI9341_Fill_Rect(200,0, 250, 480, COLOR_OLIVE) ;
	  ILI9341_Fill_Rect(250,0, 300, 480, COLOR_DGRAY) ;

	  ILI9341_Fill_Rect(0,100, 320, 200, COLOR_MAGENTA) ;
	  ILI9341_Fill_Rect(0,200, 320, 300, COLOR_OLIVE) ;
	#endif

/*
	HAL_GPIO_WritePin(GPIOA,cvab_ad7606_Pin,GPIO_PIN_SET);
	HAL_Delay(1);
	for (cpt=0;cpt<1;cpt++) { //mettre cpt � 8 pour conversion simultan�e

		HAL_GPIO_WritePin(GPIOA,rd_cs_ad7606_Pin,GPIO_PIN_RESET);
		HAL_Delay(1);
		value1=HAL_GPIO_ReadPin(d15_GPIO_Port,d15_Pin)<<15|HAL_GPIO_ReadPin(d14_GPIO_Port,d14_Pin)<<14|HAL_GPIO_ReadPin(d13_GPIO_Port,d13_Pin)<<13|HAL_GPIO_ReadPin(d12_GPIO_Port,d12_Pin)<<12;
		value2=HAL_GPIO_ReadPin(d11_GPIO_Port,d11_Pin)<<11|HAL_GPIO_ReadPin(d10_GPIO_Port,d10_Pin)<<10|HAL_GPIO_ReadPin(d9_GPIO_Port,d9_Pin)<<9|HAL_GPIO_ReadPin(d8_GPIO_Port,d8_Pin)<<8;
		value3=HAL_GPIO_ReadPin(d7_GPIO_Port,d7_Pin)<<7|HAL_GPIO_ReadPin(d6_GPIO_Port,d6_Pin)<<6|HAL_GPIO_ReadPin(d5_GPIO_Port,d5_Pin)<<5|HAL_GPIO_ReadPin(d4_GPIO_Port,d4_Pin)<<4;
		value4=HAL_GPIO_ReadPin(d3_GPIO_Port,d3_Pin)<<3|HAL_GPIO_ReadPin(d2_GPIO_Port,d2_Pin)<<2|HAL_GPIO_ReadPin(d1_GPIO_Port,d1_Pin)<<1|HAL_GPIO_ReadPin(d0_GPIO_Port,d0_Pin)<<0;
		uint16_t value=value1|value2|value3|value4;
		valuee= ((float)value *10)/32768; // valeure convertie
		//tab[compt][cpt]=valuee;
		HAL_GPIO_WritePin(GPIOA,rd_cs_ad7606_Pin,GPIO_PIN_SET);
	}

	HAL_GPIO_WritePin(GPIOA,cvab_ad7606_Pin,GPIO_PIN_RESET);
//	compt++;
  snprintf(buf, 100, "%f \r\n", valuee);
  print(buf);
*/

	/*
		  ILI9341_drawLine(470, 10, 470, 200, COLOR_OLIVE);
		   ILI9341_drawLine(469, 10, 469, 200, COLOR_OLIVE);
		   ILI9341_drawLine(468, 10, 468, 200, COLOR_OLIVE);
		   data_ads1256 =  ADS125X_ADC_ReadVolt (&my_ads1256); // read data voltage
	*/
#ifdef loop
		  data2 =((40*sin(PI2*m*50.0/Fs)+120*sin(PI2*m*100.0/Fs)+0*sin(PI2*m*1550.0/Fs)));
		  data = abs((int)(data2));

			//3Frequency 50Hz 2500Hz 2550Hz
		  testInput_f32[m] = 25*data2 ;

		  if (m==data_len){
			  m=0;
	/******************************FFT********************************************/
	/******************************FFT********************************************/
	/******************************FFT********************************************/

				  /* 1024Point real sequence fastFFT */
			  arm_rfft_fast_f32(&S, testInput_f32, testOutput_f32, ifftFlag);

					 /* For convenience and functionarm_cfft_f32The calculated results are compared and solved here1024Group modulus value, actual functionarm_rfft_fast_f32
						   Only solved512Group
				  */
			  arm_cmplx_mag_f32(testOutput_f32, testOutput, fftSize);

					 /* Serial port prints the solved modulus */
#ifdef Debug
			  for(uint16_t k=0; k<fftSize/2; k++)
			  {
				  snprintf(buf, 100, "%d is %f\r\n", k, testOutput[k]);
				  print(buf);

			  }
#endif
			  for(int p= 0 ; p< data_len2;p++){
				  empiler2(((int)(testOutput[p]))/10000);
			  }

			  max=0;
			  for (int i=0 ; i< data_len ; i++)
			  {
				  if((int)testOutput[i]>max){
					  max=(int)testOutput[i];
					  pos =i;
					  pos=pos*5;
				  }
			  }
			  itoa(pos,freq_m,10);
			  ILI9341_printText(freq_m, 40 , 250, COLOR_WHITE, COLOR_BLACK, 2);
			  if(LCD_courbe==0){
				  ILI9341_Clear_Courbe2();
				  ILI9341_Draw_Courbe2();

			  }
	/******************************FFT********************************************/
	/******************************FFT********************************************/
	/******************************FFT********************************************/
		  }

		  empiler(data);
		  m++;
		  if(LCD_courbe==1){
			  ILI9341_Draw_Courbe1();
			  ILI9341_Clear_Courbe1();
			//ILI9341_Clear_Courbe2();
		  }

#ifdef Scroll

		  for(uint i=1; i<479;i++){
			  ILI9341_Scroll(i);
			  HAL_Delay(2);
		  }
#endif
#endif
}

    /* USER CODE END WHILE */

}

void SystemClock_Config(void)
{
  RCC_OscInitTypeDef RCC_OscInitStruct = {0};
  RCC_ClkInitTypeDef RCC_ClkInitStruct = {0};
  RCC_PeriphCLKInitTypeDef PeriphClkInitStruct = {0};

  /** Configure the main internal regulator output voltage
  */
  __HAL_RCC_PWR_CLK_ENABLE();
  __HAL_PWR_VOLTAGESCALING_CONFIG(PWR_REGULATOR_VOLTAGE_SCALE1);
  /** Initializes the RCC Oscillators according to the specified parameters
  * in the RCC_OscInitTypeDef structure.
  */
  RCC_OscInitStruct.OscillatorType = RCC_OSCILLATORTYPE_HSI;
  RCC_OscInitStruct.HSIState = RCC_HSI_ON;
  RCC_OscInitStruct.HSICalibrationValue = RCC_HSICALIBRATION_DEFAULT;
  RCC_OscInitStruct.PLL.PLLState = RCC_PLL_ON;
  RCC_OscInitStruct.PLL.PLLSource = RCC_PLLSOURCE_HSI;
  RCC_OscInitStruct.PLL.PLLM = 8;
  RCC_OscInitStruct.PLL.PLLN = 216;
  RCC_OscInitStruct.PLL.PLLP = RCC_PLLP_DIV2;
  RCC_OscInitStruct.PLL.PLLQ = 2;
  if (HAL_RCC_OscConfig(&RCC_OscInitStruct) != HAL_OK)
  {
    Error_Handler();
  }
  /** Activate the Over-Drive mode
  */
  if (HAL_PWREx_EnableOverDrive() != HAL_OK)
  {
    Error_Handler();
  }
  /** Initializes the CPU, AHB and APB buses clocks
  */
  RCC_ClkInitStruct.ClockType = RCC_CLOCKTYPE_HCLK|RCC_CLOCKTYPE_SYSCLK
                              |RCC_CLOCKTYPE_PCLK1|RCC_CLOCKTYPE_PCLK2;
  RCC_ClkInitStruct.SYSCLKSource = RCC_SYSCLKSOURCE_PLLCLK;
  RCC_ClkInitStruct.AHBCLKDivider = RCC_SYSCLK_DIV1;
  RCC_ClkInitStruct.APB1CLKDivider = RCC_HCLK_DIV4;
  RCC_ClkInitStruct.APB2CLKDivider = RCC_HCLK_DIV2;

  if (HAL_RCC_ClockConfig(&RCC_ClkInitStruct, FLASH_LATENCY_7) != HAL_OK)
  {
    Error_Handler();
  }
  PeriphClkInitStruct.PeriphClockSelection = RCC_PERIPHCLK_USART3|RCC_PERIPHCLK_I2C2
                              |RCC_PERIPHCLK_SDMMC1;
  PeriphClkInitStruct.Usart3ClockSelection = RCC_USART3CLKSOURCE_PCLK1;
  PeriphClkInitStruct.I2c2ClockSelection = RCC_I2C2CLKSOURCE_PCLK1;
  PeriphClkInitStruct.Sdmmc1ClockSelection = RCC_SDMMC1CLKSOURCE_SYSCLK;
  if (HAL_RCCEx_PeriphCLKConfig(&PeriphClkInitStruct) != HAL_OK)
  {
    Error_Handler();
  }
}

static void MX_I2C2_Init(void)
{

  hi2c2.Instance = I2C2;
  hi2c2.Init.Timing = 0x20404768;
  hi2c2.Init.OwnAddress1 = 0;
  hi2c2.Init.AddressingMode = I2C_ADDRESSINGMODE_7BIT;
  hi2c2.Init.DualAddressMode = I2C_DUALADDRESS_DISABLE;
  hi2c2.Init.OwnAddress2 = 0;
  hi2c2.Init.OwnAddress2Masks = I2C_OA2_NOMASK;
  hi2c2.Init.GeneralCallMode = I2C_GENERALCALL_DISABLE;
  hi2c2.Init.NoStretchMode = I2C_NOSTRETCH_DISABLE;
  if (HAL_I2C_Init(&hi2c2) != HAL_OK)
  {
    Error_Handler();
  }
  /** Configure Analogue filter
  */
  if (HAL_I2CEx_ConfigAnalogFilter(&hi2c2, I2C_ANALOGFILTER_ENABLE) != HAL_OK)
  {
    Error_Handler();
  }
  /** Configure Digital filter
  */
  if (HAL_I2CEx_ConfigDigitalFilter(&hi2c2, 0) != HAL_OK)
  {
    Error_Handler();
  }

}

static void MX_SDMMC1_SD_Init(void)
{

  hsd1.Instance = SDMMC1;
  hsd1.Init.ClockEdge = SDMMC_CLOCK_EDGE_RISING;
  hsd1.Init.ClockBypass = SDMMC_CLOCK_BYPASS_DISABLE;
  hsd1.Init.ClockPowerSave = SDMMC_CLOCK_POWER_SAVE_DISABLE;
  hsd1.Init.BusWide = SDMMC_BUS_WIDE_1B;
  hsd1.Init.HardwareFlowControl = SDMMC_HARDWARE_FLOW_CONTROL_DISABLE;
  hsd1.Init.ClockDiv = 0;
  if (HAL_SD_Init(&hsd1) != HAL_OK)
  {
    Error_Handler();
  }
  if (HAL_SD_ConfigWideBusOperation(&hsd1, SDMMC_BUS_WIDE_4B) != HAL_OK)
  {
    Error_Handler();
  }

}

static void MX_SPI1_Init(void)
{

  /* SPI1 parameter configuration*/
  hspi1.Instance = SPI1;
  hspi1.Init.Mode = SPI_MODE_MASTER;
  hspi1.Init.Direction = SPI_DIRECTION_2LINES;
  hspi1.Init.DataSize = SPI_DATASIZE_8BIT;
  hspi1.Init.CLKPolarity = SPI_POLARITY_HIGH;
  hspi1.Init.CLKPhase = SPI_PHASE_1EDGE;
  hspi1.Init.NSS = SPI_NSS_SOFT;
  hspi1.Init.BaudRatePrescaler = SPI_BAUDRATEPRESCALER_64;
  hspi1.Init.FirstBit = SPI_FIRSTBIT_MSB;
  hspi1.Init.TIMode = SPI_TIMODE_DISABLE;
  hspi1.Init.CRCCalculation = SPI_CRCCALCULATION_DISABLE;
  hspi1.Init.CRCPolynomial = 7;
  hspi1.Init.CRCLength = SPI_CRC_LENGTH_DATASIZE;
  hspi1.Init.NSSPMode = SPI_NSS_PULSE_DISABLE;
  if (HAL_SPI_Init(&hspi1) != HAL_OK)
  {
    Error_Handler();
  }

}

static void MX_SPI2_Init(void)
{

  /* SPI2 parameter configuration*/
  hspi2.Instance = SPI2;
  hspi2.Init.Mode = SPI_MODE_MASTER;
  hspi2.Init.Direction = SPI_DIRECTION_2LINES;
  hspi2.Init.DataSize = SPI_DATASIZE_8BIT;
  hspi2.Init.CLKPolarity = SPI_POLARITY_LOW;
  hspi2.Init.CLKPhase = SPI_PHASE_1EDGE;
  hspi2.Init.NSS = SPI_NSS_SOFT;
  hspi2.Init.BaudRatePrescaler = SPI_BAUDRATEPRESCALER_32;
  hspi2.Init.FirstBit = SPI_FIRSTBIT_MSB;
  hspi2.Init.TIMode = SPI_TIMODE_DISABLE;
  hspi2.Init.CRCCalculation = SPI_CRCCALCULATION_DISABLE;
  hspi2.Init.CRCPolynomial = 7;
  hspi2.Init.CRCLength = SPI_CRC_LENGTH_DATASIZE;
  hspi2.Init.NSSPMode = SPI_NSS_PULSE_ENABLE;
  if (HAL_SPI_Init(&hspi2) != HAL_OK)
  {
    Error_Handler();
  }

}

static void MX_SPI4_Init(void)
{

  /* SPI4 parameter configuration*/
  hspi4.Instance = SPI4;
  hspi4.Init.Mode = SPI_MODE_MASTER;
  hspi4.Init.Direction = SPI_DIRECTION_2LINES;
  hspi4.Init.DataSize = SPI_DATASIZE_8BIT;
  hspi4.Init.CLKPolarity = SPI_POLARITY_LOW;
  hspi4.Init.CLKPhase = SPI_PHASE_1EDGE;
  hspi4.Init.NSS = SPI_NSS_SOFT;
  hspi4.Init.BaudRatePrescaler = SPI_BAUDRATEPRESCALER_2;
  hspi4.Init.FirstBit = SPI_FIRSTBIT_MSB;
  hspi4.Init.TIMode = SPI_TIMODE_DISABLE;
  hspi4.Init.CRCCalculation = SPI_CRCCALCULATION_DISABLE;
  hspi4.Init.CRCPolynomial = 7;
  hspi4.Init.CRCLength = SPI_CRC_LENGTH_DATASIZE;
  hspi4.Init.NSSPMode = SPI_NSS_PULSE_ENABLE;
  if (HAL_SPI_Init(&hspi4) != HAL_OK)
  {
    Error_Handler();
  }

}

static void MX_TIM3_Init(void)
{

  TIM_ClockConfigTypeDef sClockSourceConfig = {0};
  TIM_MasterConfigTypeDef sMasterConfig = {0};

  htim3.Instance = TIM3;
  htim3.Init.Prescaler = 65;
  htim3.Init.CounterMode = TIM_COUNTERMODE_UP;
  htim3.Init.Period = 65535;
  htim3.Init.ClockDivision = TIM_CLOCKDIVISION_DIV1;
  htim3.Init.AutoReloadPreload = TIM_AUTORELOAD_PRELOAD_DISABLE;
  if (HAL_TIM_Base_Init(&htim3) != HAL_OK)
  {
    Error_Handler();
  }
  sClockSourceConfig.ClockSource = TIM_CLOCKSOURCE_INTERNAL;
  if (HAL_TIM_ConfigClockSource(&htim3, &sClockSourceConfig) != HAL_OK)
  {
    Error_Handler();
  }
  sMasterConfig.MasterOutputTrigger = TIM_TRGO_RESET;
  sMasterConfig.MasterSlaveMode = TIM_MASTERSLAVEMODE_DISABLE;
  if (HAL_TIMEx_MasterConfigSynchronization(&htim3, &sMasterConfig) != HAL_OK)
  {
    Error_Handler();
  }

}

static void MX_USART3_UART_Init(void)
{

  huart3.Instance = USART3;
  huart3.Init.BaudRate = 115200;
  huart3.Init.WordLength = UART_WORDLENGTH_8B;
  huart3.Init.StopBits = UART_STOPBITS_1;
  huart3.Init.Parity = UART_PARITY_NONE;
  huart3.Init.Mode = UART_MODE_TX_RX;
  huart3.Init.HwFlowCtl = UART_HWCONTROL_NONE;
  huart3.Init.OverSampling = UART_OVERSAMPLING_16;
  huart3.Init.OneBitSampling = UART_ONE_BIT_SAMPLE_DISABLE;
  huart3.AdvancedInit.AdvFeatureInit = UART_ADVFEATURE_NO_INIT;
  if (HAL_UART_Init(&huart3) != HAL_OK)
  {
    Error_Handler();
  }

}

/* FMC initialization function */
static void MX_FMC_Init(void)
{

  FMC_NORSRAM_TimingTypeDef Timing = {0};

  /** Perform the SRAM1 memory initialization sequence
  */
  hsram1.Instance = FMC_NORSRAM_DEVICE;
  hsram1.Extended = FMC_NORSRAM_EXTENDED_DEVICE;
  /* hsram1.Init */
  hsram1.Init.NSBank = FMC_NORSRAM_BANK1;
  hsram1.Init.DataAddressMux = FMC_DATA_ADDRESS_MUX_DISABLE;
  hsram1.Init.MemoryType = FMC_MEMORY_TYPE_SRAM;
  hsram1.Init.MemoryDataWidth = FMC_NORSRAM_MEM_BUS_WIDTH_8;
  hsram1.Init.BurstAccessMode = FMC_BURST_ACCESS_MODE_DISABLE;
  hsram1.Init.WaitSignalPolarity = FMC_WAIT_SIGNAL_POLARITY_LOW;
  hsram1.Init.WaitSignalActive = FMC_WAIT_TIMING_BEFORE_WS;
  hsram1.Init.WriteOperation = FMC_WRITE_OPERATION_ENABLE;
  hsram1.Init.WaitSignal = FMC_WAIT_SIGNAL_DISABLE;
  hsram1.Init.ExtendedMode = FMC_EXTENDED_MODE_DISABLE;
  hsram1.Init.AsynchronousWait = FMC_ASYNCHRONOUS_WAIT_DISABLE;
  hsram1.Init.WriteBurst = FMC_WRITE_BURST_DISABLE;
  hsram1.Init.ContinuousClock = FMC_CONTINUOUS_CLOCK_SYNC_ONLY;
  hsram1.Init.WriteFifo = FMC_WRITE_FIFO_ENABLE;
  hsram1.Init.PageSize = FMC_PAGE_SIZE_NONE;
  /* Timing */
  Timing.AddressSetupTime = 15;
  Timing.AddressHoldTime = 15;
  Timing.DataSetupTime = 255;
  Timing.BusTurnAroundDuration = 15;
  Timing.CLKDivision = 16;
  Timing.DataLatency = 17;
  Timing.AccessMode = FMC_ACCESS_MODE_A;
  /* ExtTiming */

  if (HAL_SRAM_Init(&hsram1, &Timing, NULL) != HAL_OK)
  {
    Error_Handler( );
  }

}

static void MX_GPIO_Init(void)
{
  GPIO_InitTypeDef GPIO_InitStruct = {0};

  /* GPIO Ports Clock Enable */
  __HAL_RCC_GPIOE_CLK_ENABLE();
  __HAL_RCC_GPIOF_CLK_ENABLE();
  __HAL_RCC_GPIOC_CLK_ENABLE();
  __HAL_RCC_GPIOA_CLK_ENABLE();
  __HAL_RCC_GPIOB_CLK_ENABLE();
  __HAL_RCC_GPIOD_CLK_ENABLE();
  __HAL_RCC_GPIOG_CLK_ENABLE();

  /*Configure GPIO pin Output Level */
  HAL_GPIO_WritePin(GPIOE, cs_sd_Pin|GPIO_PIN_1, GPIO_PIN_RESET);

  /*Configure GPIO pin Output Level */
  HAL_GPIO_WritePin(GPIOB, GPIO_PIN_1|GPIO_PIN_8, GPIO_PIN_RESET);

  /*Configure GPIO pin Output Level */
  HAL_GPIO_WritePin(rst_ad7606_GPIO_Port, rst_ad7606_Pin, GPIO_PIN_RESET);

  /*Configure GPIO pin Output Level */
  HAL_GPIO_WritePin(GPIOA, rd_cs_ad7606_Pin|osc1_ad7606_Pin|cvab_ad7606_Pin|osc3_ad7606_Pin
                          |osc2_ad7606_Pin, GPIO_PIN_RESET);

  /*Configure GPIO pins : cs_sd_Pin PE1 */
  GPIO_InitStruct.Pin = cs_sd_Pin|GPIO_PIN_1;
  GPIO_InitStruct.Mode = GPIO_MODE_OUTPUT_PP;
  GPIO_InitStruct.Pull = GPIO_NOPULL;
  GPIO_InitStruct.Speed = GPIO_SPEED_FREQ_LOW;
  HAL_GPIO_Init(GPIOE, &GPIO_InitStruct);

  /*Configure GPIO pin : PE4 */
  GPIO_InitStruct.Pin = GPIO_PIN_4;
  GPIO_InitStruct.Mode = GPIO_MODE_IT_RISING;
  GPIO_InitStruct.Pull = GPIO_PULLUP;
  HAL_GPIO_Init(GPIOE, &GPIO_InitStruct);

  /*Configure GPIO pins : PB1 PB8 */
  GPIO_InitStruct.Pin = GPIO_PIN_1|GPIO_PIN_8;
  GPIO_InitStruct.Mode = GPIO_MODE_OUTPUT_PP;
  GPIO_InitStruct.Pull = GPIO_NOPULL;
  GPIO_InitStruct.Speed = GPIO_SPEED_FREQ_LOW;
  HAL_GPIO_Init(GPIOB, &GPIO_InitStruct);

  /*Configure GPIO pins : PB2 d5_Pin d4_Pin d3_Pin
                           d2_Pin d1_Pin d0_Pin */
  GPIO_InitStruct.Pin = GPIO_PIN_2|d5_Pin|d4_Pin|d3_Pin
                          |d2_Pin|d1_Pin|d0_Pin;
  GPIO_InitStruct.Mode = GPIO_MODE_INPUT;
  GPIO_InitStruct.Pull = GPIO_NOPULL;
  HAL_GPIO_Init(GPIOB, &GPIO_InitStruct);

  /*Configure GPIO pin : rst_ad7606_Pin */
  GPIO_InitStruct.Pin = rst_ad7606_Pin;
  GPIO_InitStruct.Mode = GPIO_MODE_OUTPUT_PP;
  GPIO_InitStruct.Pull = GPIO_NOPULL;
  GPIO_InitStruct.Speed = GPIO_SPEED_FREQ_LOW;
  HAL_GPIO_Init(rst_ad7606_GPIO_Port, &GPIO_InitStruct);

  /*Configure GPIO pins : rd_cs_ad7606_Pin osc1_ad7606_Pin cvab_ad7606_Pin osc3_ad7606_Pin
                           osc2_ad7606_Pin */
  GPIO_InitStruct.Pin = rd_cs_ad7606_Pin|osc1_ad7606_Pin|cvab_ad7606_Pin|osc3_ad7606_Pin
                          |osc2_ad7606_Pin;
  GPIO_InitStruct.Mode = GPIO_MODE_OUTPUT_PP;
  GPIO_InitStruct.Pull = GPIO_NOPULL;
  GPIO_InitStruct.Speed = GPIO_SPEED_FREQ_LOW;
  HAL_GPIO_Init(GPIOA, &GPIO_InitStruct);

  /*Configure GPIO pin : d15_Pin */
  GPIO_InitStruct.Pin = d15_Pin;
  GPIO_InitStruct.Mode = GPIO_MODE_INPUT;
  GPIO_InitStruct.Pull = GPIO_NOPULL;
  HAL_GPIO_Init(d15_GPIO_Port, &GPIO_InitStruct);

  /*Configure GPIO pins : d14_Pin d13_Pin d12_Pin */
  GPIO_InitStruct.Pin = d14_Pin|d13_Pin|d12_Pin;
  GPIO_InitStruct.Mode = GPIO_MODE_INPUT;
  GPIO_InitStruct.Pull = GPIO_NOPULL;
  HAL_GPIO_Init(GPIOD, &GPIO_InitStruct);

  /*Configure GPIO pins : d11_Pin d10_Pin d9_Pin d8_Pin
                           d7_Pin d6_Pin */
  GPIO_InitStruct.Pin = d11_Pin|d10_Pin|d9_Pin|d8_Pin
                          |d7_Pin|d6_Pin;
  GPIO_InitStruct.Mode = GPIO_MODE_INPUT;
  GPIO_InitStruct.Pull = GPIO_NOPULL;
  HAL_GPIO_Init(GPIOG, &GPIO_InitStruct);

  /* EXTI interrupt init*/
  HAL_NVIC_SetPriority(EXTI4_IRQn, 0, 0);
  HAL_NVIC_EnableIRQ(EXTI4_IRQn);

}

/* USER CODE BEGIN 4 */

void delay_us (uint16_t us)
{
	__HAL_TIM_SET_COUNTER(&htim3,0);  // set the counter value a 0
	while (__HAL_TIM_GET_COUNTER(&htim3) < us);  // wait for the counter to reach the us input in the parameter
}
/* USER CODE END 4 */

void Error_Handler(void)
{
  __disable_irq();
  while (1)
  {
  }
}

/************************ (C) COPYRIGHT STMicroelectronics *****END OF FILE****/
